VERSION ""

NS_ :

BS_:

BU_: CHUD_LS VKM_LS RCRM_LS MSM_RR_LS MSM_LR_LS CGM_LS BSM_LS VPM_LS ISRVM_LS DCAC_LS TouchPad_LS RSC_LS LVMPC_LS EOCM2B_K1_LS EOCM2A_K1_LS LCM_LS TIM_B_LS V2V_LS TCP_LS CSM_LS EOCM2B_K2_LS EOCM2A_K2_LS TIM_A_LS LVMNav_LS HFP_LS EDI_LS ARB_LS RSE_LS Dummy_LS VIS2_LS ICS_LS FCM_LS EOCM_F_LS VICM_LS AGC_LS MSM_P_LS OTIM_LS HVSM_R_LS HVSM_F_LS DVB_T_LS SBZA_R_LS PSD_R_LS PSD_L_LS UHP_Low UPA_LS STC_LS SBZA_L_LS PTM_LS ONSTAR_LS APA_LS TestTool_LS PHS_LS PDIM_LS CHM_LS RSA_LS AMP_LS HUD_LS MSM_LS HBSM_LS SCL_LS ECC_LS RadioHead_LS PEPS_LS IPC_LS AOS_LS SDM_LS TIM_LS BCM_LS

BO_ 2151292928 V2V_Customization_Menu_LS: 5 V2V_LS
 SG_ TrfRdsdInfCsStAvail : 0|1@0+ (1,0) [0|1] ""  CGM_LS,CSM_LS,RadioHead_LS
 SG_ TrfRdsdInfCsCrStVal : 10|3@0+ (1,0) [0|7] ""  CGM_LS,CSM_LS,RadioHead_LS
 SG_ TRICA_Resrv5Avail : 32|1@0+ (1,0) [0|1] ""  CGM_LS,CSM_LS,RadioHead_LS
 SG_ TRICA_Resrv4Avail : 33|1@0+ (1,0) [0|1] ""  CGM_LS,CSM_LS,RadioHead_LS
 SG_ TRICA_Resrv3Avail : 34|1@0+ (1,0) [0|1] ""  CGM_LS,CSM_LS,RadioHead_LS
 SG_ TRICA_Resrv2Avail : 35|1@0+ (1,0) [0|1] ""  CGM_LS,CSM_LS,RadioHead_LS
 SG_ TRICA_Resrv1Avail : 36|1@0+ (1,0) [0|1] ""  CGM_LS,CSM_LS,RadioHead_LS
 SG_ TRICA_OnAvail : 37|1@0+ (1,0) [0|1] ""  CGM_LS,CSM_LS,RadioHead_LS
 SG_ TRICA_OfAvail : 38|1@0+ (1,0) [0|1] ""  CGM_LS,CSM_LS,RadioHead_LS
 SG_ IntrStopAlrtCsSetAvl : 2|1@0+ (1,0) [0|1] ""  CGM_LS,CSM_LS,RadioHead_LS
 SG_ IntrStAlrtCsCrSetVal : 5|3@0+ (1,0) [0|7] ""  CGM_LS,CSM_LS,RadioHead_LS
 SG_ ISACA_Resrv4Avail : 16|1@0+ (1,0) [0|1] ""  CGM_LS,CSM_LS,RadioHead_LS
 SG_ ISACA_Resrv3Avail : 17|1@0+ (1,0) [0|1] ""  CGM_LS,CSM_LS,RadioHead_LS
 SG_ ISACA_Resrv2Avail : 18|1@0+ (1,0) [0|1] ""  CGM_LS,CSM_LS,RadioHead_LS
 SG_ ISACA_Resrv1Avail : 19|1@0+ (1,0) [0|1] ""  CGM_LS,CSM_LS,RadioHead_LS
 SG_ ISACA_AlrtBrkAvail : 20|1@0+ (1,0) [0|1] ""  CGM_LS,CSM_LS,RadioHead_LS
 SG_ ISACA_AlrtAvail : 21|1@0+ (1,0) [0|1] ""  CGM_LS,CSM_LS,RadioHead_LS
 SG_ ISACA_OfAvail : 22|1@0+ (1,0) [0|1] ""  CGM_LS,CSM_LS,RadioHead_LS
 SG_ CntdVehBrkAltCsStAvl : 1|1@0+ (1,0) [0|1] ""  CGM_LS,CSM_LS,RadioHead_LS
 SG_ CntdVehBrAltCsCrStVal : 13|3@0+ (1,0) [0|7] ""  CGM_LS,CSM_LS,RadioHead_LS
 SG_ CVBACA_Resrv5Avail : 24|1@0+ (1,0) [0|1] ""  CGM_LS,CSM_LS,RadioHead_LS
 SG_ CVBACA_Resrv4Avail : 25|1@0+ (1,0) [0|1] ""  CGM_LS,CSM_LS,RadioHead_LS
 SG_ CVBACA_Resrv3Avail : 26|1@0+ (1,0) [0|1] ""  CGM_LS,CSM_LS,RadioHead_LS
 SG_ CVBACA_Resrv2Avail : 27|1@0+ (1,0) [0|1] ""  CGM_LS,CSM_LS,RadioHead_LS
 SG_ CVBACA_Resrv1Avail : 28|1@0+ (1,0) [0|1] ""  CGM_LS,CSM_LS,RadioHead_LS
 SG_ CVBACA_OnAvail : 29|1@0+ (1,0) [0|1] ""  CGM_LS,CSM_LS,RadioHead_LS
 SG_ CVBACA_OfAvail : 30|1@0+ (1,0) [0|1] ""  CGM_LS,CSM_LS,RadioHead_LS

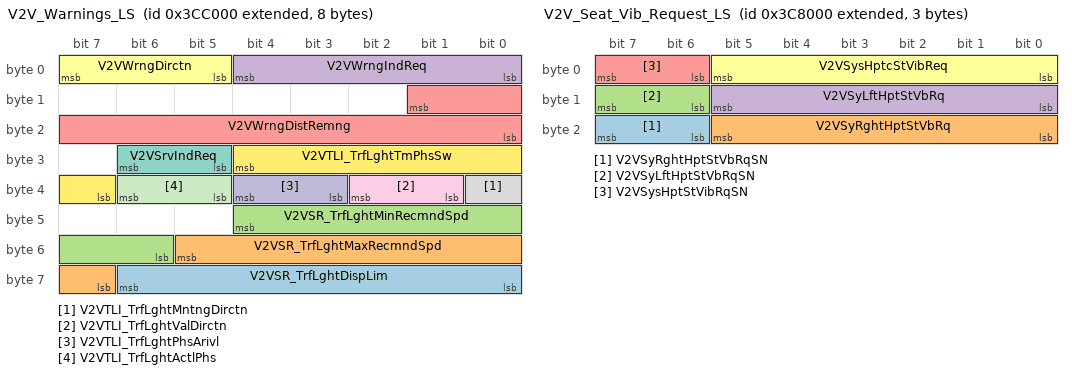
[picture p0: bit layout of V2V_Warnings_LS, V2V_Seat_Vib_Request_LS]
BO_ 2151464960 V2V_Warnings_LS: 8 V2V_LS
 SG_ V2VSR_TrfLghtDispLim : 62|7@0+ (1,0) [0|127] "km/h"  CGM_LS,IPC_LS
 SG_ V2VSR_TrfLghtMaxRecmndSpd : 53|7@0+ (1,0) [0|127] "km/h"  CGM_LS,IPC_LS
 SG_ V2VSR_TrfLghtMinRecmndSpd : 44|7@0+ (1,0) [0|127] "km/h"  CGM_LS,IPC_LS
 SG_ V2VWrngIndReq : 4|5@0+ (1,0) [0|31] ""  CGM_LS,IPC_LS
 SG_ V2VWrngDistRemng : 9|10@0+ (1,0) [0|1023] ""  CGM_LS,IPC_LS
 SG_ V2VWrngDirctn : 7|3@0+ (1,0) [0|7] ""  CGM_LS,IPC_LS
 SG_ V2VSrvIndReq : 30|2@0+ (1,0) [0|3] ""  CGM_LS,IPC_LS
 SG_ V2VTLI_TrfLghtMntngDirctn : 32|1@0+ (1,0) [0|1] ""  CGM_LS,IPC_LS
 SG_ V2VTLI_TrfLghtValDirctn : 34|2@0+ (1,0) [0|3] ""  CGM_LS,IPC_LS
 SG_ V2VTLI_TrfLghtPhsArivl : 36|2@0+ (1,0) [0|3] ""  CGM_LS,IPC_LS
 SG_ V2VTLI_TrfLghtActlPhs : 38|2@0+ (1,0) [0|3] ""  CGM_LS,IPC_LS
 SG_ V2VTLI_TrfLghtTmPhsSw : 28|6@0+ (1,0) [0|63] ""  CGM_LS,IPC_LS

BO_ 2151448576 V2V_Seat_Vib_Request_LS: 3 V2V_LS
 SG_ V2VSyRghtHptStVbRqSN : 23|2@0+ (1,0) [0|3] ""  MSM_P_LS,MSM_LS
 SG_ V2VSyRghtHptStVbRq : 21|6@0+ (1,0) [0|63] ""  MSM_P_LS,MSM_LS
 SG_ V2VSyLftHptStVbRqSN : 15|2@0+ (1,0) [0|3] ""  MSM_P_LS,MSM_LS
 SG_ V2VSyLftHptStVbRq : 13|6@0+ (1,0) [0|63] ""  MSM_P_LS,MSM_LS
 SG_ V2VSysHptStVibRqSN : 7|2@0+ (1,0) [0|3] ""  MSM_P_LS,MSM_LS
 SG_ V2VSysHptcStVibReq : 5|6@0+ (1,0) [0|63] ""  MSM_P_LS,MSM_LS

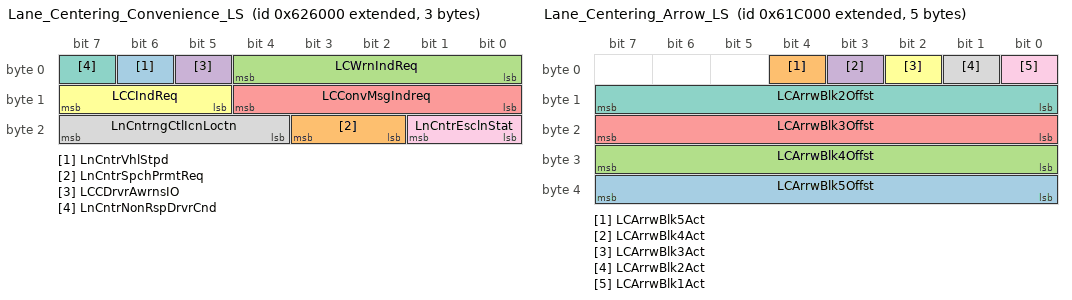
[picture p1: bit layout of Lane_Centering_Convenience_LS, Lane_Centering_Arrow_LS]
BO_ 2153930752 Lane_Centering_Convenience_LS: 3 EOCM2A_K2_LS
 SG_ LnCntrVhlStpd : 6|1@0+ (1,0) [0|1] ""  TCP_LS,ONSTAR_LS,CGM_LS
 SG_ LnCntrSpchPrmtReq : 19|2@0+ (1,0) [0|3] ""  CSM_LS,TCP_LS,ONSTAR_LS,CGM_LS
 SG_ LCWrnIndReq : 4|5@0+ (1,0) [0|31] ""  CGM_LS,IPC_LS
 SG_ LCCDrvrAwrnsIO : 5|1@0+ (1,0) [0|1] ""  TCP_LS,ONSTAR_LS,CGM_LS,IPC_LS
 SG_ LCConvMsgIndreq : 12|5@0+ (1,0) [0|31] ""  CSM_LS,CGM_LS,IPC_LS
 SG_ LCCIndReq : 15|3@0+ (1,0) [0|7] ""  TCP_LS,ONSTAR_LS,CGM_LS,IPC_LS
 SG_ LnCntrNonRspDrvrCnd : 7|1@0+ (1,0) [0|1] ""  TCP_LS,ONSTAR_LS,CGM_LS
 SG_ LnCntrngCtlIcnLoctn : 23|4@0- (1,0) [-8|7] ""  CGM_LS,IPC_LS
 SG_ LnCntrEsclnStat : 17|2@0+ (1,0) [0|3] ""  TCP_LS,ONSTAR_LS,CGM_LS

BO_ 2153889792 Lane_Centering_Arrow_LS: 5 EOCM2A_K2_LS
 SG_ LCArrwBlk5Offst : 39|8@0- (1,0) [-128|127] ""  CGM_LS,IPC_LS
 SG_ LCArrwBlk5Act : 4|1@0+ (1,0) [0|1] ""  CGM_LS,IPC_LS
 SG_ LCArrwBlk4Offst : 31|8@0- (1,0) [-128|127] ""  CGM_LS,IPC_LS
 SG_ LCArrwBlk4Act : 3|1@0+ (1,0) [0|1] ""  CGM_LS,IPC_LS
 SG_ LCArrwBlk3Offst : 23|8@0- (1,0) [-128|127] ""  CGM_LS,IPC_LS
 SG_ LCArrwBlk3Act : 2|1@0+ (1,0) [0|1] ""  CGM_LS,IPC_LS
 SG_ LCArrwBlk2Offst : 15|8@0- (1,0) [-128|127] ""  CGM_LS,IPC_LS
 SG_ LCArrwBlk2Act : 1|1@0+ (1,0) [0|1] ""  CGM_LS,IPC_LS
 SG_ LCArrwBlk1Act : 0|1@0+ (1,0) [0|1] ""  CGM_LS,IPC_LS

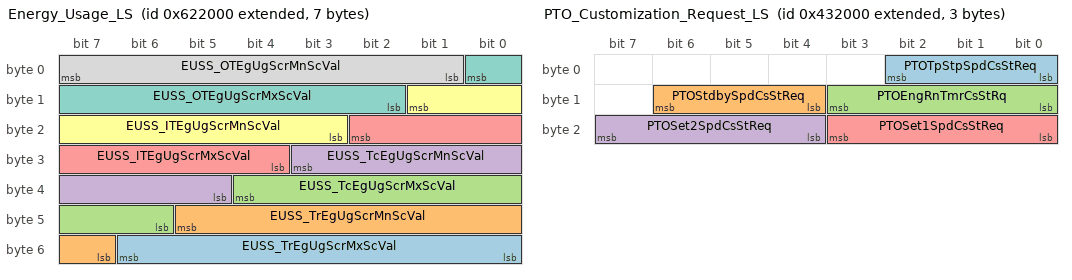
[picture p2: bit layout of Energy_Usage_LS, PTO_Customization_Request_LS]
BO_ 2153914368 Energy_Usage_LS: 7 VICM_LS
 SG_ EUSS_TrEgUgScrMxScVal : 54|7@0- (0.1,0) [-5|5] ""  CGM_LS,CSM_LS,RadioHead_LS
 SG_ EUSS_TrEgUgScrMnScVal : 45|7@0- (0.1,0) [-5|5] ""  CGM_LS,CSM_LS,RadioHead_LS
 SG_ EUSS_TcEgUgScrMxScVal : 36|7@0- (0.1,0) [-5|5] ""  CGM_LS,CSM_LS,RadioHead_LS
 SG_ EUSS_TcEgUgScrMnScVal : 27|7@0- (0.1,0) [-5|5] ""  CGM_LS,CSM_LS,RadioHead_LS
 SG_ EUSS_ITEgUgScrMxScVal : 18|7@0- (0.1,0) [-5|5] ""  CGM_LS,CSM_LS,RadioHead_LS
 SG_ EUSS_ITEgUgScrMnScVal : 9|7@0- (0.1,0) [-5|5] ""  CGM_LS,CSM_LS,RadioHead_LS
 SG_ EUSS_OTEgUgScrMxScVal : 0|7@0- (0.1,0) [-5|5] ""  CGM_LS,CSM_LS,RadioHead_LS
 SG_ EUSS_OTEgUgScrMnScVal : 7|7@0- (0.1,0) [-5|5] ""  CGM_LS,CSM_LS,RadioHead_LS

BO_ 2151882752 PTO_Customization_Request_LS: 3 RadioHead_LS
 SG_ PTOTpStpSpdCsStReq : 2|3@0+ (1,0) [0|7] ""  BCM_LS
 SG_ PTOStdbySpdCsStReq : 14|3@0+ (1,0) [0|7] ""  BCM_LS
 SG_ PTOEngRnTmrCsStRq : 11|4@0+ (1,0) [0|15] ""  BCM_LS
 SG_ PTOSet2SpdCsStReq : 23|4@0+ (1,0) [0|15] ""  BCM_LS
 SG_ PTOSet1SpdCsStReq : 19|4@0+ (1,0) [0|15] ""  BCM_LS

BO_ 2151899136 PTO_Status_LS: 5 BCM_LS
 SG_ PTOAccelUpnBrkRelIO : 22|1@0+ (1,0) [0|1] ""  CGM_LS,IPC_LS
 SG_ PTOEngUpnBrkRelIO : 23|1@0+ (1,0) [0|1] ""  CGM_LS,IPC_LS
 SG_ PTOManTransInGrIO : 21|1@0+ (1,0) [0|1] ""  CGM_LS,IPC_LS
 SG_ PTOServIndOn : 31|1@0+ (1,0) [0|1] ""  CGM_LS,IPC_LS
 SG_ PTOVDM : 20|1@0+ (1,0) [0|1] ""  CGM_LS,CSM_LS,RadioHead_LS,IPC_LS
 SG_ PTOVDA : 19|1@0+ (1,0) [0|1] ""  CGM_LS,CSM_LS,RadioHead_LS,IPC_LS
 SG_ PTOTransInGearIO : 13|1@0+ (1,0) [0|1] ""  CGM_LS,IPC_LS
 SG_ PTOTpStpSpdCsStAvl : 10|1@0+ (1,0) [0|1] ""  CGM_LS,CSM_LS,RadioHead_LS
 SG_ PTOTpStSpdCsCrStVal : 26|3@0+ (1,0) [0|7] ""  CGM_LS,CSM_LS,RadioHead_LS
 SG_ PTOStdbySpdCsStAvl : 12|1@0+ (1,0) [0|1] ""  CGM_LS,CSM_LS,RadioHead_LS
 SG_ PTOStdbSpdCsCrStVal : 18|3@0+ (1,0) [0|7] ""  CGM_LS,CSM_LS,RadioHead_LS
 SG_ PTOSetPrkBrkIO : 14|1@0+ (1,0) [0|1] ""  CGM_LS,IPC_LS
 SG_ PTOSet2SpdCsStAvl : 9|1@0+ (1,0) [0|1] ""  CGM_LS,CSM_LS,RadioHead_LS
 SG_ PTOSet2SpdCsCrStVal : 39|4@0+ (1,0) [0|15] ""  CGM_LS,CSM_LS,RadioHead_LS
 SG_ PTOSet1SpdCsStAvl : 8|1@0+ (1,0) [0|1] ""  CGM_LS,CSM_LS,RadioHead_LS
 SG_ PTOSet1SpdCsCrStVal : 35|4@0+ (1,0) [0|15] ""  CGM_LS,CSM_LS,RadioHead_LS
 SG_ PTORelCltPedIO : 15|1@0+ (1,0) [0|1] ""  CGM_LS,IPC_LS
 SG_ PTORelBrkPedIO : 0|1@0+ (1,0) [0|1] ""  CGM_LS,IPC_LS
 SG_ PTORelAccPedIO : 1|1@0+ (1,0) [0|1] ""  CGM_LS,IPC_LS
 SG_ PTORedEngSpdIO : 2|1@0+ (1,0) [0|1] ""  CGM_LS,IPC_LS
 SG_ PTOPrsRelCltPedIO : 3|1@0+ (1,0) [0|1] ""  CGM_LS,IPC_LS
 SG_ PTOPrsRelBrkPedIO : 4|1@0+ (1,0) [0|1] ""  CGM_LS,IPC_LS
 SG_ PTOEngRnTmrCsStAvl : 11|1@0+ (1,0) [0|1] ""  CGM_LS,CSM_LS,RadioHead_LS
 SG_ PTOEnRnTmCsCrStVal : 30|4@0+ (1,0) [0|15] ""  CGM_LS,CSM_LS,RadioHead_LS
 SG_ PTOEngmntStatInd : 6|2@0+ (1,0) [0|3] ""  CGM_LS,IPC_LS
 SG_ PTODisengCrsCntlIO : 7|1@0+ (1,0) [0|1] ""  CGM_LS,IPC_LS

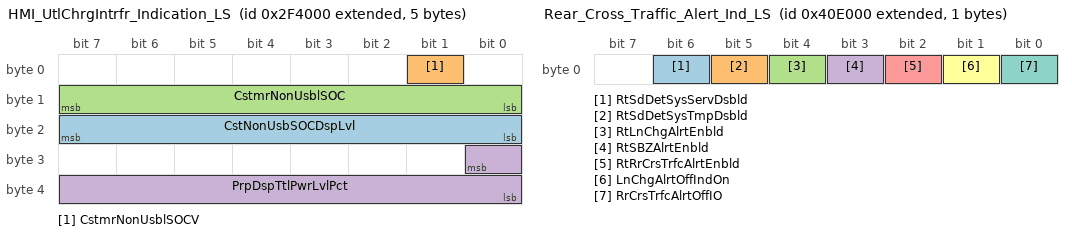
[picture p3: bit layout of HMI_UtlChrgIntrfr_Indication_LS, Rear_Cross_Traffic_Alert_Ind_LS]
BO_ 2150580224 HMI_UtlChrgIntrfr_Indication_LS: 5 VICM_LS
 SG_ CstNonUsbSOCDspLvl : 23|8@0+ (0.392157,0) [0|100.000035] "%"  CGM_LS,IPC_LS
 SG_ CstmrNonUsblSOCV : 1|1@0+ (1,0) [0|1] ""  CSM_LS,ONSTAR_LS,CGM_LS,IPC_LS
 SG_ CstmrNonUsblSOC : 15|8@0+ (0.392157,0) [0|100.000035] "%"  CSM_LS,ONSTAR_LS,CGM_LS,IPC_LS
 SG_ PrpDspTtlPwrLvlPct : 24|9@0- (0.392157,0) [-100.392192|100.000035] "%"  CSM_LS,RadioHead_LS,CGM_LS,IPC_LS

BO_ 2020 USDT_Req_to_VICM_LS: 8 TestTool_LS
 SG_ DgnInf : 7|64@0+ (1,0) [0|1.84467440737096E+019] ""  CGM_LS,TCP_LS,ONSTAR_LS,BSM_LS,VICM_LS

BO_ 2151735296 Rear_Cross_Traffic_Alert_Ind_LS: 1 SBZA_L_LS
 SG_ RtSdDetSysServDsbld : 6|1@0+ (1,0) [0|1] ""  SBZA_R_LS,CGM_LS
 SG_ RtSdDetSysTmpDsbld : 5|1@0+ (1,0) [0|1] ""  SBZA_R_LS,CGM_LS
 SG_ RtLnChgAlrtEnbld : 4|1@0+ (1,0) [0|1] ""  SBZA_R_LS,CGM_LS
 SG_ RtSBZAlrtEnbld : 3|1@0+ (1,0) [0|1] ""  SBZA_R_LS,CGM_LS
 SG_ RtRrCrsTrfcAlrtEnbld : 2|1@0+ (1,0) [0|1] ""  SBZA_R_LS,CGM_LS
 SG_ LnChgAlrtOffIndOn : 1|1@0+ (1,0) [0|1] ""  CGM_LS,SBZA_R_LS,IPC_LS
 SG_ RrCrsTrfcAlrtOffIO : 0|1@0+ (1,0) [0|1] ""  CGM_LS,SBZA_R_LS,IPC_LS

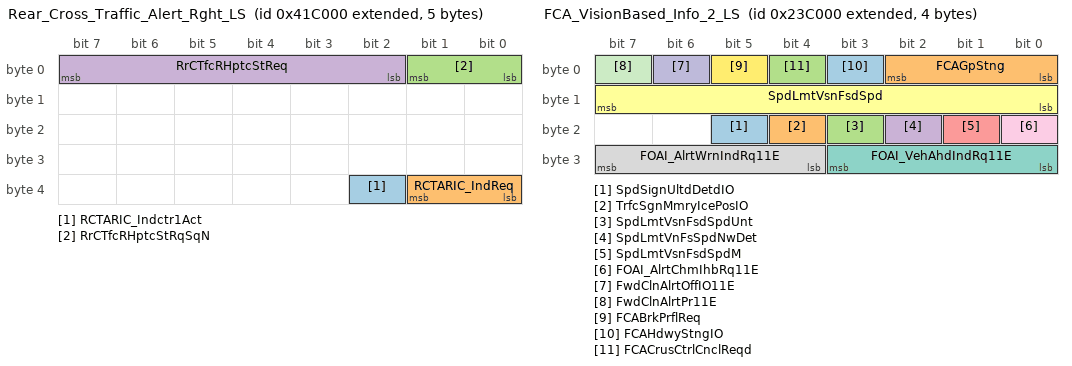
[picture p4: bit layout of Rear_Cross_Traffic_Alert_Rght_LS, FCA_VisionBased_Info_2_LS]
BO_ 2151792640 Rear_Cross_Traffic_Alert_Rght_LS: 5 SBZA_R_LS
 SG_ RCTARIC_Indctr1Act : 34|1@0+ (1,0) [0|1] ""  CGM_LS,VPM_LS,CSM_LS,RadioHead_LS
 SG_ RCTARIC_IndReq : 33|2@0+ (1,0) [0|3] ""  CGM_LS,VPM_LS,CSM_LS,RadioHead_LS
 SG_ RrCTfcRHptcStRqSqN : 1|2@0+ (1,0) [0|3] ""  CGM_LS,VPM_LS,MSM_P_LS,MSM_LS
 SG_ RrCTfcRHptcStReq : 7|6@0+ (1,0) [0|63] ""  CGM_LS,VPM_LS,MSM_P_LS,MSM_LS

BO_ 2149826560 FCA_VisionBased_Info_2_LS: 4 FCM_LS
 SG_ SpdSignUltdDetdIO : 21|1@0+ (1,0) [0|1] ""  CGM_LS,IPC_LS
 SG_ TrfcSgnMmryIcePosIO : 20|1@0+ (1,0) [0|1] ""  CGM_LS,IPC_LS
 SG_ SpdLmtVsnFsdSpdUnt : 19|1@0+ (1,0) [0|1] ""  IPC_LS,CGM_LS,BCM_LS
 SG_ SpdLmtVnFsSpdNwDet : 18|1@0+ (1,0) [0|1] ""  CGM_LS,BCM_LS
 SG_ SpdLmtVsnFsdSpdM : 17|1@0+ (1,0) [0|1] ""  CGM_LS,BCM_LS,IPC_LS
 SG_ SpdLmtVsnFsdSpd : 15|8@0+ (1,0) [0|255] ""  CSM_LS,RadioHead_LS,CGM_LS,BCM_LS,IPC_LS
 SG_ FOAI_VehAhdIndRq11E : 27|4@0+ (1,0) [0|15] ""  BCM_LS,CGM_LS,IPC_LS,CHUD_LS,HUD_LS
 SG_ FOAI_AlrtWrnIndRq11E : 31|4@0+ (1,0) [0|15] ""  BCM_LS,CGM_LS,IPC_LS,CHUD_LS,HUD_LS
 SG_ FOAI_AlrtChmIhbRq11E : 16|1@0+ (1,0) [0|1] ""  BCM_LS,CGM_LS,IPC_LS,CHUD_LS,HUD_LS
 SG_ FwdClnAlrtOffIO11E : 6|1@0+ (1,0) [0|1] ""  CGM_LS,IPC_LS
 SG_ FwdClnAlrtPr11E : 7|1@0+ (1,0) [0|1] ""  CGM_LS,IPC_LS,CHUD_LS,HUD_LS
 SG_ FCABrkPrflReq : 5|1@0+ (1,0) [0|1] ""  CGM_LS,BCM_LS
 SG_ FCAHdwyStngIO : 3|1@0+ (1,0) [0|1] ""  CGM_LS,IPC_LS
 SG_ FCAGpStng : 2|3@0+ (1,0) [0|7] ""  CGM_LS,IPC_LS
 SG_ FCACrusCtrlCnclReqd : 4|1@0+ (1,0) [0|1] ""  CGM_LS,BCM_LS

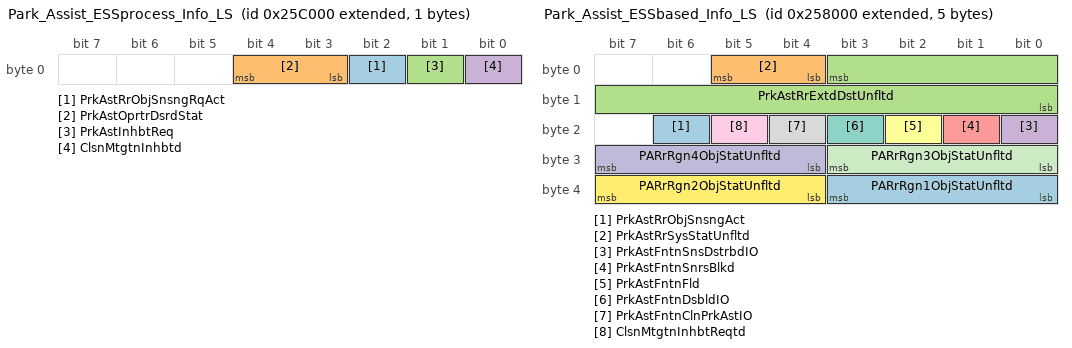
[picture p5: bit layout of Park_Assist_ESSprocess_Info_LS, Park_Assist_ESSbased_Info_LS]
BO_ 2149957632 Park_Assist_ESSprocess_Info_LS: 1 EOCM_F_LS
 SG_ PrkAstRrObjSnsngRqAct : 2|1@0+ (1,0) [0|1] ""  CGM_LS,UPA_LS,APA_LS
 SG_ PrkAstOprtrDsrdStat : 4|2@0+ (1,0) [0|3] ""  CGM_LS,UPA_LS,APA_LS
 SG_ PrkAstInhbtReq : 1|1@0+ (1,0) [0|1] ""  CGM_LS,UPA_LS,APA_LS
 SG_ ClsnMtgtnInhbtd : 0|1@0+ (1,0) [0|1] ""  CGM_LS,UPA_LS,APA_LS

BO_ 2149941248 Park_Assist_ESSbased_Info_LS: 5 APA_LS
 SG_ PrkAstRrObjSnsngAct : 22|1@0+ (1,0) [0|1] ""  EOCM2B_K2_LS,EOCM2A_K2_LS,CGM_LS,EOCM_F_LS
 SG_ PrkAstRrSysStatUnfltd : 5|2@0+ (1,0) [0|3] ""  EOCM2B_K2_LS,EOCM2A_K2_LS,CGM_LS,EOCM_F_LS
 SG_ PrkAstRrExtdDstUnfltd : 3|12@0+ (0.01,0) [0|40.95] "m"  EOCM2B_K2_LS,EOCM2A_K2_LS,CGM_LS,EOCM_F_LS
 SG_ PrkAstFntnSnsDstrbdIO : 16|1@0+ (1,0) [0|1] ""  CGM_LS,EOCM2B_K2_LS,EOCM2A_K2_LS,SBZA_R_LS,SBZA_L_LS,EOCM_F_LS
 SG_ PrkAstFntnSnrsBlkd : 17|1@0+ (1,0) [0|1] ""  CGM_LS,EOCM2B_K2_LS,EOCM2A_K2_LS,SBZA_R_LS,SBZA_L_LS,EOCM_F_LS
 SG_ PrkAstFntnFld : 18|1@0+ (1,0) [0|1] ""  CGM_LS,EOCM2B_K2_LS,EOCM2A_K2_LS,SBZA_R_LS,SBZA_L_LS,EOCM_F_LS
 SG_ PrkAstFntnDsbldIO : 19|1@0+ (1,0) [0|1] ""  CGM_LS,EOCM2B_K2_LS,EOCM2A_K2_LS,SBZA_R_LS,SBZA_L_LS,EOCM_F_LS
 SG_ PrkAstFntnClnPrkAstIO : 20|1@0+ (1,0) [0|1] ""  CGM_LS,EOCM2B_K2_LS,EOCM2A_K2_LS,SBZA_R_LS,SBZA_L_LS,EOCM_F_LS
 SG_ ClsnMtgtnInhbtReqtd : 21|1@0+ (1,0) [0|1] ""  EOCM2B_K2_LS,EOCM2A_K2_LS,CGM_LS,EOCM_F_LS
 SG_ PARrRgn4ObjStatUnfltd : 31|4@0+ (1,0) [0|15] ""  EOCM2B_K2_LS,EOCM2A_K2_LS,CGM_LS,EOCM_F_LS
 SG_ PARrRgn3ObjStatUnfltd : 27|4@0+ (1,0) [0|15] ""  EOCM2B_K2_LS,EOCM2A_K2_LS,CGM_LS,EOCM_F_LS
 SG_ PARrRgn2ObjStatUnfltd : 39|4@0+ (1,0) [0|15] ""  EOCM2B_K2_LS,EOCM2A_K2_LS,CGM_LS,EOCM_F_LS
 SG_ PARrRgn1ObjStatUnfltd : 35|4@0+ (1,0) [0|15] ""  EOCM2B_K2_LS,EOCM2A_K2_LS,CGM_LS,EOCM_F_LS

BO_ 2156314624 High_Volt_Time_Based_Chrg_LS: 8 VICM_LS
 SG_ HVChrgSysSplyFltIO : 23|1@0+ (1,0) [0|1] ""  CGM_LS,IPC_LS
 SG_ OffBrdCSFltDtctd : 6|1@0+ (1,0) [0|1] ""  CSM_LS,ONSTAR_LS,CGM_LS,IPC_LS
 SG_ OBVhCsACChgRqBnVs : 7|1@0+ (1,0) [0|1] ""  BCM_LS,CGM_LS,CSM_LS,RadioHead_LS
 SG_ TODCNPDT_Min : 13|6@0+ (1,0) [0|63] "Minute"  BCM_LS,CGM_LS,CSM_LS,RadioHead_LS
 SG_ TODCNPDT_Hr : 2|5@0+ (1,0) [0|31] "Hour"  BCM_LS,CGM_LS,CSM_LS,RadioHead_LS
 SG_ TODCNPDT_DyOfWk : 5|3@0+ (1,0) [0|7] ""  BCM_LS,CGM_LS,CSM_LS,RadioHead_LS
 SG_ HVBatBlkSOC : 63|8@0+ (0.392157,0) [0|100.000035] "%"  CGM_LS,CSM_LS,RadioHead_LS,IPC_LS
 SG_ TODCOpMd : 22|3@0+ (1,0) [0|7] ""  CSM_LS,TCP_LS,CGM_LS,RadioHead_LS,ONSTAR_LS
 SG_ TODCDMPTO_TpOvR : 51|4@0+ (1,0) [0|15] ""  BCM_LS,TCP_LS,CGM_LS,ONSTAR_LS,CSM_LS,RadioHead_LS,IPC_LS
 SG_ TODCDMPTO_CmPgR : 52|1@0+ (1,0) [0|1] ""  BCM_LS,TCP_LS,CGM_LS,ONSTAR_LS,CSM_LS,RadioHead_LS,IPC_LS
 SG_ HVChrgSysStNot : 55|3@0+ (1,0) [0|7] ""  BCM_LS,CSM_LS,TCP_LS,CGM_LS,RadioHead_LS,ONSTAR_LS
 SG_ HVChrgAbrtRsn : 19|3@0+ (1,0) [0|7] ""  CSM_LS,TCP_LS,CGM_LS,RadioHead_LS,ONSTAR_LS
 SG_ HVCSCLPD_UsrIntTyp : 16|2@0+ (1,0) [0|3] ""  BCM_LS,CGM_LS,CSM_LS,RadioHead_LS
 SG_ HVCSCLPD_RdCrntLv3 : 44|5@0+ (1,0) [0|31] "A"  BCM_LS,CGM_LS,CSM_LS,RadioHead_LS
 SG_ HVCSCLPD_RdCrntLv2 : 33|5@0+ (1,0) [0|31] "A"  BCM_LS,CGM_LS,CSM_LS,RadioHead_LS
 SG_ HVCSCLPD_RdCrntLv1 : 38|5@0+ (1,0) [0|31] "A"  BCM_LS,CGM_LS,CSM_LS,RadioHead_LS
 SG_ HVCSCLPD_NrmChrgC : 27|5@0+ (1,0) [0|31] "A"  BCM_LS,CGM_LS,CSM_LS,RadioHead_LS
 SG_ HVCSCLPD_ChgLvlPfS : 30|3@0+ (1,0) [0|7] ""  BCM_LS,CGM_LS,CSM_LS,RadioHead_LS

BO_ 2150449152 Engine_Information_5_LS: 4 BCM_LS
 SG_ ESPDrvrExtIO : 29|1@0+ (1,0) [0|1] ""  IPC_LS,CGM_LS
 SG_ ESPDrvrDrStIndtrmntIO : 30|1@0+ (1,0) [0|1] ""  IPC_LS,CGM_LS
 SG_ ESPAutoPrkIO : 31|1@0+ (1,0) [0|1] ""  IPC_LS,CGM_LS
 SG_ ManTransIndReq : 28|3@0+ (1,0) [0|7] ""  CGM_LS,IPC_LS
 SG_ SrvcFlSysPrkInOpnArIO : 0|1@0+ (1,0) [0|1] ""  CGM_LS,IPC_LS
 SG_ TnDrvStblCtrlOffUnbIO : 2|1@0+ (1,0) [0|1] ""  CGM_LS,IPC_LS
 SG_ TnDrvTrCtrlOffUnbIO : 1|1@0+ (1,0) [0|1] ""  CGM_LS,IPC_LS
 SG_ ASIRI_Indication08 : 16|1@0+ (1,0) [0|1] ""  CSM_LS,CGM_LS,IPC_LS
 SG_ ASIRI_Indication07 : 17|1@0+ (1,0) [0|1] ""  CSM_LS,CGM_LS,IPC_LS
 SG_ ASIRI_Indication06 : 18|1@0+ (1,0) [0|1] ""  CSM_LS,CGM_LS,IPC_LS
 SG_ ASIRI_Indication05 : 19|1@0+ (1,0) [0|1] ""  CSM_LS,CGM_LS,IPC_LS
 SG_ ASIRI_Indication04 : 20|1@0+ (1,0) [0|1] ""  CSM_LS,CGM_LS,IPC_LS
 SG_ ASIRI_Indication03 : 21|1@0+ (1,0) [0|1] ""  CSM_LS,CGM_LS,IPC_LS
 SG_ ASIRI_Indication02 : 22|1@0+ (1,0) [0|1] ""  CSM_LS,CGM_LS,IPC_LS
 SG_ ASIRI_Indication01 : 23|1@0+ (1,0) [0|1] ""  CSM_LS,CGM_LS,IPC_LS
 SG_ SpdLmtrSttngTypAct : 25|2@0+ (1,0) [0|3] ""  FCM_LS,VIS2_LS,CSM_LS,RadioHead_LS,CGM_LS,IPC_LS
 SG_ FuelSysNEmsRltMalfAct : 4|1@0+ (1,0) [0|1] ""  CGM_LS,IPC_LS
 SG_ InActFuelMdFuelLvlIO : 3|1@0+ (1,0) [0|1] ""  CGM_LS,IPC_LS
 SG_ EngInltSpcfcHmdtyV : 7|1@0+ (1,0) [0|1] ""  CGM_LS,ECC_LS
 SG_ EngInltSpcfcHmdtyM : 6|1@0+ (1,0) [0|1] ""  CGM_LS,ECC_LS
 SG_ EngInltSpcfcHmdty : 15|8@0+ (0.0196078,0) [0|4.999989] "% water"  CGM_LS,ECC_LS
 SG_ AltFuelSysOvrflDtdIO : 5|1@0+ (1,0) [0|1] ""  CGM_LS,IPC_LS

BO_ 2149810176 FCA_VisionBased_Info_1_LS: 1 BCM_LS
 SG_ FCAHptcStVbnRqSeqN : 1|2@0+ (1,0) [0|3] ""  MSM_P_LS,MSM_LS
 SG_ FCAHptcStVbnReq : 7|6@0+ (1,0) [0|63] ""  MSM_P_LS,MSM_LS

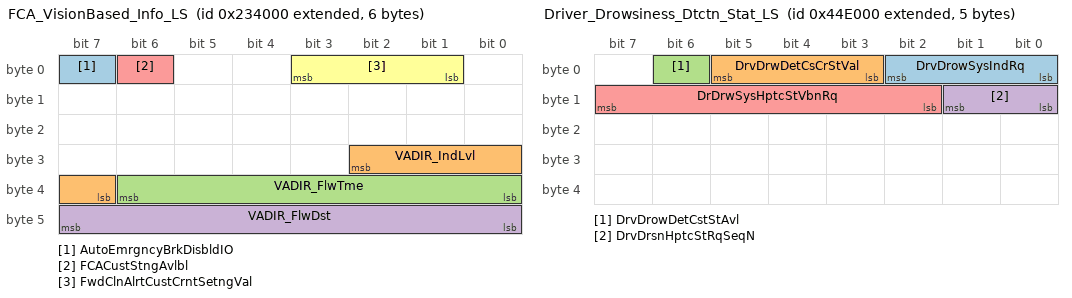
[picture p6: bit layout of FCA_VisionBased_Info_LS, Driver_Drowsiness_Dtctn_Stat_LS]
BO_ 2149793792 FCA_VisionBased_Info_LS: 6 FCM_LS
 SG_ AutoEmrgncyBrkDisbldIO : 7|1@0+ (1,0) [0|1] ""  CGM_LS,IPC_LS
 SG_ VADIR_IndLvl : 26|4@0+ (1,0) [0|15] ""  CSM_LS,RadioHead_LS,CGM_LS,IPC_LS
 SG_ VADIR_FlwTme : 38|7@0+ (0.1,0) [0|12.7] "s"  CSM_LS,RadioHead_LS,CGM_LS,IPC_LS
 SG_ VADIR_FlwDst : 47|8@0+ (1,0) [0|255] "m"  CSM_LS,RadioHead_LS,CGM_LS,IPC_LS
 SG_ FCACustStngAvlbl : 6|1@0+ (1,0) [0|1] ""  CGM_LS,CSM_LS,RadioHead_LS
 SG_ FwdClnAlrtCustCrntSetngVal : 3|3@0+ (1,0) [0|7] ""  CGM_LS,CSM_LS,RadioHead_LS

BO_ 2150080512 Aux_Coolant_Heater_Status_LS: 8 VICM_LS
 SG_ LBCVLS_VehGPSLctV : 27|1@0+ (1,0) [0|1] ""  CGM_LS,CSM_LS,RadioHead_LS
 SG_ LBCVLS_VehGPSLct : 26|3@0+ (1,0) [0|7] ""  CGM_LS,CSM_LS,RadioHead_LS
 SG_ LBCPSS_PosUpdtStat : 20|2@0+ (1,0) [0|3] ""  CGM_LS,CSM_LS,RadioHead_LS
 SG_ LBCPSS_PosUpdtLct : 18|3@0+ (1,0) [0|7] ""  CGM_LS,CSM_LS,RadioHead_LS
 SG_ LBCCsStAvl : 7|1@0+ (1,0) [0|1] ""  CGM_LS,CSM_LS,RadioHead_LS
 SG_ LBCCsCrStVal : 2|2@0+ (1,0) [0|3] ""  CGM_LS,CSM_LS,RadioHead_LS
 SG_ LBCCF_Lct4PosStrdIO : 28|1@0+ (1,0) [0|1] ""  CGM_LS,CSM_LS,RadioHead_LS
 SG_ LBCCF_Lct3PosStrdIO : 29|1@0+ (1,0) [0|1] ""  CGM_LS,CSM_LS,RadioHead_LS
 SG_ LBCCF_Lct2PosStrdIO : 30|1@0+ (1,0) [0|1] ""  CGM_LS,CSM_LS,RadioHead_LS
 SG_ LBCCF_Lct1PosStrdIO : 31|1@0+ (1,0) [0|1] ""  CGM_LS,CSM_LS,RadioHead_LS
 SG_ LBCCDRR_PosNumbr : 10|3@0+ (1,0) [0|7] ""  CGM_LS,CSM_LS,RadioHead_LS
 SG_ LBCCDRR_ClrStrdPosResp : 12|2@0+ (1,0) [0|3] ""  CGM_LS,CSM_LS,RadioHead_LS
 SG_ ChrgCyclOvrlEngyEcnEq : 51|12@0+ (0.1,0) [0|409.5] "km/l"  CGM_LS,CSM_LS,RadioHead_LS
 SG_ ChrgCyclElecEngyEcnEq : 35|12@0+ (0.1,0) [0|409.5] "km/l"  CGM_LS,CSM_LS,RadioHead_LS
 SG_ LBCChrgLvlPrfExpIO : 6|1@0+ (1,0) [0|1] ""  CGM_LS,CSM_LS,RadioHead_LS
 SG_ EngAstHtDfrdHtMdAct : 0|1@0+ (1,0) [0|1] ""  CGM_LS,ECC_LS
 SG_ AuxClntHtrVlvStat : 5|3@0+ (1,0) [0|7] ""  CGM_LS,ECC_LS

BO_ 2153873408 Heated_Steering_Whl_Rqsted_LS: 1 EOCM2B_K2_LS
 SG_ MnlHtdStWhlRqstd : 7|1@0+ (1,0) [0|1] ""  CGM_LS,ECC_LS

BO_ 2152128512 Performance_Mode_Cust_Setings_LS: 4 BCM_LS
 SG_ PSPMCA_PsngStPrfMd6Avl : 16|1@0+ (1,0) [0|1] ""  CGM_LS,CSM_LS,RadioHead_LS
 SG_ PSPMCA_PsngStPrfMd5Avl : 17|1@0+ (1,0) [0|1] ""  CGM_LS,CSM_LS,RadioHead_LS
 SG_ PSPMCA_PsngStPrfMd4Avl : 18|1@0+ (1,0) [0|1] ""  CGM_LS,CSM_LS,RadioHead_LS
 SG_ PSPMCA_PsngStPrfMd3Avl : 19|1@0+ (1,0) [0|1] ""  CGM_LS,CSM_LS,RadioHead_LS
 SG_ PSPMCA_PsngStPrfMd2Avl : 20|1@0+ (1,0) [0|1] ""  CGM_LS,CSM_LS,RadioHead_LS
 SG_ PSPMCA_PsngStPrfMd1Avl : 21|1@0+ (1,0) [0|1] ""  CGM_LS,CSM_LS,RadioHead_LS
 SG_ DSPMCA_DrvrStPrfMd6Avl : 8|1@0+ (1,0) [0|1] ""  CGM_LS,CSM_LS,RadioHead_LS
 SG_ DSPMCA_DrvrStPrfMd5Avl : 9|1@0+ (1,0) [0|1] ""  CGM_LS,CSM_LS,RadioHead_LS
 SG_ DSPMCA_DrvrStPrfMd4Avl : 10|1@0+ (1,0) [0|1] ""  CGM_LS,CSM_LS,RadioHead_LS
 SG_ DSPMCA_DrvrStPrfMd3Avl : 11|1@0+ (1,0) [0|1] ""  CGM_LS,CSM_LS,RadioHead_LS
 SG_ DSPMCA_DrvrStPrfMd2Avl : 12|1@0+ (1,0) [0|1] ""  CGM_LS,CSM_LS,RadioHead_LS
 SG_ DSPMCA_DrvrStPrfMd1Avl : 13|1@0+ (1,0) [0|1] ""  CGM_LS,CSM_LS,RadioHead_LS
 SG_ DSPMCA_DrvStyPrfMd7Avl : 24|1@0+ (1,0) [0|1] ""  CGM_LS,CSM_LS,RadioHead_LS
 SG_ DSPMCA_DrvStyPrfMd6Avl : 25|1@0+ (1,0) [0|1] ""  CGM_LS,CSM_LS,RadioHead_LS
 SG_ DSPMCA_DrvStyPrfMd5Avl : 26|1@0+ (1,0) [0|1] ""  CGM_LS,CSM_LS,RadioHead_LS
 SG_ DSPMCA_DrvStyPrfMd4Avl : 27|1@0+ (1,0) [0|1] ""  CGM_LS,CSM_LS,RadioHead_LS
 SG_ DSPMCA_DrvStyPrfMd3Avl : 28|1@0+ (1,0) [0|1] ""  CGM_LS,CSM_LS,RadioHead_LS
 SG_ DSPMCA_DrvStyPrfMd2Avl : 29|1@0+ (1,0) [0|1] ""  CGM_LS,CSM_LS,RadioHead_LS
 SG_ DSPMCA_DrvStyPrfMd1Avl : 30|1@0+ (1,0) [0|1] ""  CGM_LS,CSM_LS,RadioHead_LS
 SG_ ACCPMCA_ACCPrfMd6Avl : 0|1@0+ (1,0) [0|1] ""  CGM_LS,CSM_LS,RadioHead_LS
 SG_ ACCPMCA_ACCPrfMd5Avl : 1|1@0+ (1,0) [0|1] ""  CGM_LS,CSM_LS,RadioHead_LS
 SG_ ACCPMCA_ACCPrfMd4Avl : 2|1@0+ (1,0) [0|1] ""  CGM_LS,CSM_LS,RadioHead_LS
 SG_ ACCPMCA_ACCPrfMd3Avl : 3|1@0+ (1,0) [0|1] ""  CGM_LS,CSM_LS,RadioHead_LS
 SG_ ACCPMCA_ACCPrfMd2Avl : 4|1@0+ (1,0) [0|1] ""  CGM_LS,CSM_LS,RadioHead_LS
 SG_ ACCPMCA_ACCPrfMd1Avl : 5|1@0+ (1,0) [0|1] ""  CGM_LS,CSM_LS,RadioHead_LS

BO_ 2151997440 Driver_Drowsiness_Dtctn_Stat_LS: 5 FCM_LS
 SG_ DrvDrowSysIndRq : 2|3@0+ (1,0) [0|7] ""  CGM_LS,BCM_LS,IPC_LS
 SG_ DrvDrwDetCsCrStVal : 5|3@0+ (1,0) [0|7] ""  CGM_LS,CSM_LS,RadioHead_LS
 SG_ DrvDrowDetCstStAvl : 6|1@0+ (1,0) [0|1] ""  CGM_LS,CSM_LS,RadioHead_LS
 SG_ DrvDrsnHptcStRqSeqN : 9|2@0+ (1,0) [0|3] ""  CGM_LS,MSM_P_LS,MSM_LS
 SG_ DrDrwSysHptcStVbnRq : 15|6@0+ (1,0) [0|63] ""  CGM_LS,BCM_LS,MSM_P_LS,MSM_LS

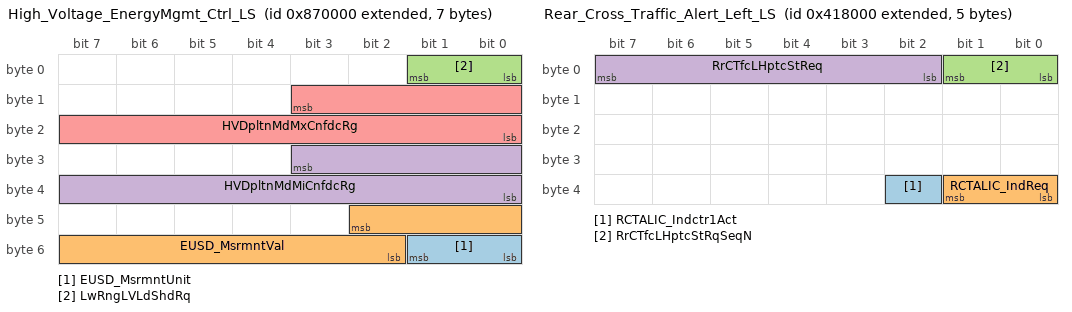
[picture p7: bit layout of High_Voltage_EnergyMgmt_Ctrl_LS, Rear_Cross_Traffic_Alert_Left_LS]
BO_ 2156331008 High_Voltage_EnergyMgmt_Ctrl_LS: 7 VICM_LS
 SG_ EUSD_MsrmntUnit : 49|2@0+ (1,0) [0|3] ""  CGM_LS,CSM_LS,RadioHead_LS
 SG_ EUSD_MsrmntVal : 42|9@0+ (1,0) [0|511] ""  CGM_LS,CSM_LS,RadioHead_LS
 SG_ LwRngLVLdShdRq : 1|2@0+ (1,0) [0|3] ""  CSM_LS,CGM_LS,RadioHead_LS,BCM_LS
 SG_ HVDpltnMdMiCnfdcRg : 27|12@0+ (0.1,0) [0|409.5] "km"  CGM_LS,CSM_LS,RadioHead_LS,IPC_LS
 SG_ HVDpltnMdMxCnfdcRg : 11|12@0+ (0.1,0) [0|409.5] "km"  CGM_LS,CSM_LS,RadioHead_LS,IPC_LS

BO_ 2151776256 Rear_Cross_Traffic_Alert_Left_LS: 5 SBZA_L_LS
 SG_ RCTALIC_Indctr1Act : 34|1@0+ (1,0) [0|1] ""  CGM_LS,VPM_LS,CSM_LS,RadioHead_LS
 SG_ RCTALIC_IndReq : 33|2@0+ (1,0) [0|3] ""  CGM_LS,VPM_LS,CSM_LS,RadioHead_LS
 SG_ RrCTfcLHptcStRqSeqN : 1|2@0+ (1,0) [0|3] ""  CGM_LS,VPM_LS,MSM_P_LS,MSM_LS
 SG_ RrCTfcLHptcStReq : 7|6@0+ (1,0) [0|63] ""  CGM_LS,VPM_LS,MSM_P_LS,MSM_LS

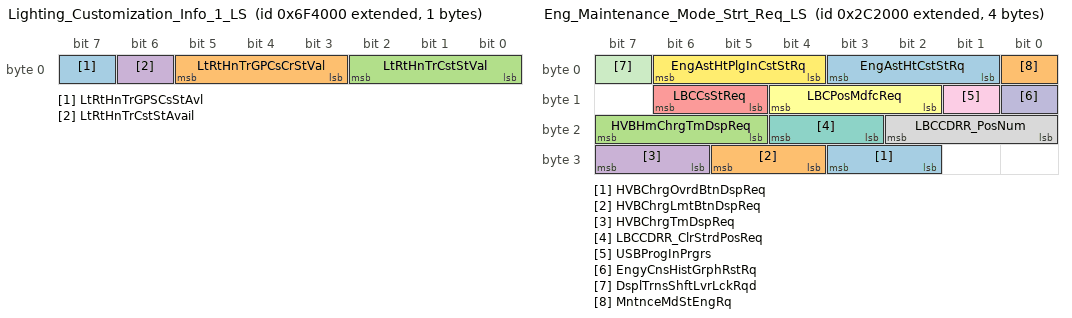
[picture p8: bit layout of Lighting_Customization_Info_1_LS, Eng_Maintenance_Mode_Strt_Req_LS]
BO_ 2154774528 Lighting_Customization_Info_1_LS: 1 BCM_LS
 SG_ LtRtHnTrGPSCsStAvl : 7|1@0+ (1,0) [0|1] ""  CGM_LS,CSM_LS,RadioHead_LS
 SG_ LtRtHnTrGPCsCrStVal : 5|3@0+ (1,0) [0|7] ""  CGM_LS,CSM_LS,RadioHead_LS
 SG_ LtRtHnTrCstStVal : 2|3@0+ (1,0) [0|7] ""  CGM_LS,CSM_LS,RadioHead_LS
 SG_ LtRtHnTrCstStAvail : 6|1@0+ (1,0) [0|1] ""  CGM_LS,CSM_LS,RadioHead_LS

BO_ 2150375424 Eng_Maintenance_Mode_Strt_Req_LS: 4 RadioHead_LS
 SG_ HVBChrgOvrdBtnDspReq : 27|2@0+ (1,0) [0|3] ""  VICM_LS
 SG_ HVBChrgLmtBtnDspReq : 29|2@0+ (1,0) [0|3] ""  VICM_LS
 SG_ HVBHmChrgTmDspReq : 23|3@0+ (1,0) [0|7] ""  VICM_LS
 SG_ HVBChrgTmDspReq : 31|2@0+ (1,0) [0|3] ""  VICM_LS
 SG_ LBCCsStReq : 14|2@0+ (1,0) [0|3] ""  BSM_LS,VICM_LS
 SG_ LBCPosMdfcReq : 12|3@0+ (1,0) [0|7] ""  BSM_LS,VICM_LS
 SG_ LBCCDRR_ClrStrdPosReq : 20|2@0+ (1,0) [0|3] ""  BSM_LS,VICM_LS
 SG_ LBCCDRR_PosNum : 18|3@0+ (1,0) [0|7] ""  BSM_LS,VICM_LS
 SG_ USBProgInPrgrs : 9|1@0+ (1,0) [0|1] ""  BCM_LS
 SG_ EngyCnsHistGrphRstRq : 8|1@0+ (1,0) [0|1] ""  BSM_LS,VICM_LS
 SG_ DsplTrnsShftLvrLckRqd : 7|1@0+ (1,0) [0|1] ""  BCM_LS
 SG_ EngAstHtPlgInCstStRq : 6|3@0+ (1,0) [0|7] ""  BSM_LS,VICM_LS
 SG_ EngAstHtCstStRq : 3|3@0+ (1,0) [0|7] ""  BSM_LS,VICM_LS
 SG_ MntnceMdStEngRq : 0|1@0+ (1,0) [0|1] ""  BSM_LS,VICM_LS

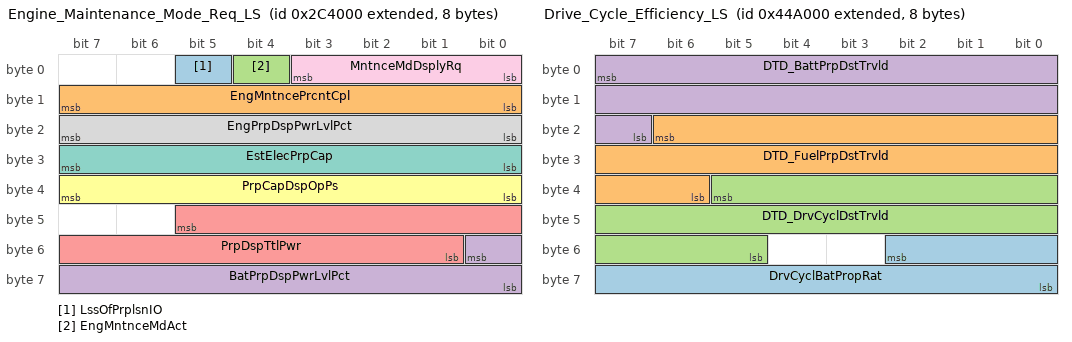
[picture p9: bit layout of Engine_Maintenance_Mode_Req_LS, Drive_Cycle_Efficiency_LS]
BO_ 2150383616 Engine_Maintenance_Mode_Req_LS: 8 VICM_LS
 SG_ LssOfPrplsnIO : 5|1@0+ (1,0) [0|1] ""  CGM_LS,IPC_LS
 SG_ EngMntncePrcntCpl : 15|8@0+ (0.392157,0) [0|100.000035] "%"  CGM_LS,IPC_LS
 SG_ EngMntnceMdAct : 4|1@0+ (1,0) [0|1] ""  CGM_LS,IPC_LS
 SG_ BatPrpDspPwrLvlPct : 48|9@0- (0.392157,0) [-100.392192|100.000035] "%"  CSM_LS,CGM_LS,IPC_LS
 SG_ PrpDspTtlPwr : 45|13@0+ (0.5,-326.6) [-326.6|3768.9] "kW"  CSM_LS,RadioHead_LS,CGM_LS,IPC_LS
 SG_ PrpCapDspOpPs : 39|8@0+ (0.392157,0) [0|100.000035] "%"  CSM_LS,RadioHead_LS,CGM_LS,IPC_LS
 SG_ EstElecPrpCap : 31|8@0+ (0.392157,0) [0|100.000035] "%"  CSM_LS,ONSTAR_LS,CGM_LS,IPC_LS
 SG_ EngPrpDspPwrLvlPct : 23|8@0+ (0.392157,0) [0|100.000035] "%"  CSM_LS,RadioHead_LS,CGM_LS,IPC_LS
 SG_ MntnceMdDsplyRq : 3|4@0+ (1,0) [0|15] ""  CGM_LS,CSM_LS,RadioHead_LS

BO_ 2151981056 Drive_Cycle_Efficiency_LS: 8 VICM_LS
 SG_ DrvCyclBatPropRat : 50|11@0+ (0.048852,0) [0|100.000044] "%"  CGM_LS,CSM_LS,RadioHead_LS
 SG_ DTD_FuelPrpDstTrvld : 22|17@0+ (0.015625,0) [0|2047.984375] "km"  CGM_LS,CSM_LS,RadioHead_LS
 SG_ DTD_DrvCyclDstTrvld : 37|17@0+ (0.015625,0) [0|2047.984375] "km"  CGM_LS,CSM_LS,RadioHead_LS
 SG_ DTD_BattPrpDstTrvld : 7|17@0+ (0.015625,0) [0|2047.984375] "km"  CGM_LS,CSM_LS,RadioHead_LS

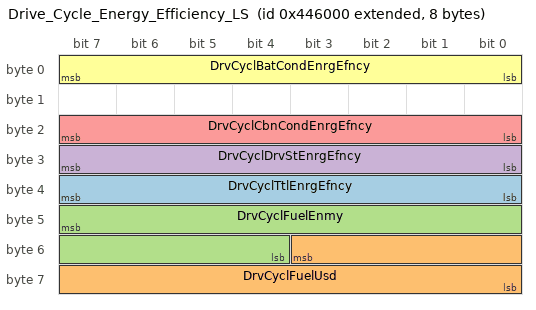
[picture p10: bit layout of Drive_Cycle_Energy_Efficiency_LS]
BO_ 2151964672 Drive_Cycle_Energy_Efficiency_LS: 8 VICM_LS
 SG_ DrvCyclTtlEnrgEfncy : 39|8@0+ (0.392157,0) [0|100.000035] "%"  CGM_LS,CSM_LS,RadioHead_LS
 SG_ DrvCyclFuelUsd : 51|12@0+ (0.125,0) [0|511.875] "liters"  CGM_LS,CSM_LS,RadioHead_LS
 SG_ DrvCyclFuelEnmy : 47|12@0+ (0.1,0) [0|409.5] "km/liters"  CGM_LS,CSM_LS,RadioHead_LS
 SG_ DrvCyclDrvStEnrgEfncy : 31|8@0+ (0.392157,0) [0|100.000035] "%"  CGM_LS,CSM_LS,RadioHead_LS
 SG_ DrvCyclCbnCondEnrgEfncy : 23|8@0+ (0.392157,0) [0|100.000035] "%"  CGM_LS,CSM_LS,RadioHead_LS
 SG_ DrvCyclBatCondEnrgEfncy : 7|8@0+ (0.392157,0) [0|100.000035] "%"  CGM_LS,CSM_LS,RadioHead_LS

BO_TX_BU_ 2151448576 : CGM_LS,V2V_LS;
BO_TX_BU_ 2153914368 : BSM_LS,VICM_LS;
BO_TX_BU_ 2151882752 : CGM_LS,CSM_LS,RadioHead_LS;
BO_TX_BU_ 2150580224 : BSM_LS,VICM_LS;
BO_TX_BU_ 2020 : CSM_LS,CGM_LS,TCP_LS,ONSTAR_LS,TestTool_LS;
BO_TX_BU_ 2151735296 : EOCM2A_K2_LS,SBZA_L_LS;
BO_TX_BU_ 2151792640 : EOCM2A_K2_LS,SBZA_L_LS,SBZA_R_LS;
BO_TX_BU_ 2149826560 : VIS2_LS,FCM_LS;
BO_TX_BU_ 2149957632 : EOCM2A_K2_LS,EOCM_F_LS;
BO_TX_BU_ 2149941248 : UPA_LS,APA_LS;
BO_TX_BU_ 2149810176 : EOCM2B_K2_LS,FCM_LS,BCM_LS;
BO_TX_BU_ 2149793792 : EOCM_F_LS,BCM_LS,FCM_LS;
BO_TX_BU_ 2150080512 : BSM_LS,VICM_LS;
BO_TX_BU_ 2151997440 : VIS2_LS,FCM_LS;
BO_TX_BU_ 2156331008 : BSM_LS,VICM_LS;
BO_TX_BU_ 2151776256 : EOCM2A_K2_LS,SBZA_L_LS;
BO_TX_BU_ 2150375424 : CGM_LS,CSM_LS,RadioHead_LS;
BO_TX_BU_ 2150383616 : BSM_LS,VICM_LS;
BO_TX_BU_ 2151981056 : BSM_LS,VICM_LS;
BO_TX_BU_ 2151964672 : BSM_LS,VICM_LS;
CM_ SG_ 2151899136 PTORelBrkPedIO "Power Take Off Release Brake Pedal To Engage Indication On";
BA_DEF_ SG_  "VNSigPrimaryTriggering" ENUM  "No","Yes","DLCLS","DLCHS","DLCCE","DLCFO";
BA_DEF_ SG_  "VNSigRemoteDiagnostics" ENUM  "No","Yes","DLCLS","DLCHS","DLCCE","DLCFO";
BA_DEF_ SG_  "VNSigInfotainment" ENUM  "No","Yes","DLCLS","DLCHS","DLCCE","DLCFO";
BA_DEF_ SG_  "VNSigParkedVehicle" ENUM  "No","Yes","DLCLS","DLCHS","DLCCE","DLCFO";
BA_DEF_ SG_  "VNSigIntermediate" ENUM  "No","Yes","DLCLS","DLCHS","DLCCE","DLCFO";
BA_DEF_ SG_  "VNSigUnused_4" ENUM  "No","Yes","DLCLS","DLCHS","DLCCE","DLCFO";
BA_DEF_ SG_  "SignalType" STRING ;
BA_DEF_ SG_  "PacketOrder" INT 0 65535;
BA_DEF_ SG_  "SignalLongName" STRING ;
BA_DEF_ SG_  "GenSigStartValue" INT 0 65535;
BA_DEF_ SG_  "VNSigDiagnostic" ENUM  "No","Yes","DLCLS","DLCHS","DLCCE","DLCFO";
BA_DEF_ SG_  "VNSigAllNodes" ENUM  "No","Yes","DLCLS","DLCHS","DLCCE","DLCFO";
BA_DEF_ SG_  "GenSigDeltaValue" INT 0 0;
BA_DEF_ SG_  "GenSigInactiveValue" INT 0 0;
BA_DEF_ SG_  "GenSigSendType" ENUM  "not used","not used","not used","not used","not used","not used","not used","NoSigSendType","not used","not used","OnAnyChange","OnChangeIfActive","OnDelta","DLCLS","DLCHS","DLCCE","DLCFO";
BA_DEF_ SG_  "GenSigSendOnInit" ENUM  "Not Initialized","Application","Handler","DLCLS","DLCHS","DLCCE","DLCFO";
BA_DEF_ BO_  "AppGenMsgCycleTime" INT 0 0;
BA_DEF_ BO_  "TpTxIndex" INT 0 99;
BA_DEF_ BO_  "GenMsgILSupport" ENUM  "No","Yes","DLCLS","DLCHS","DLCCE","DLCFO";
BA_DEF_ BO_  "TpApplType" STRING ;
BA_DEF_ BO_  "Prio" INT 0 7;
BA_DEF_ BO_  "MessageSubnet" ENUM  "LS","MS","HS","CE","PE","HV","FO","S1","HE","LE","HE2","DLCLS","DLCHS","DLCCE","DLCFO";
BA_DEF_ BO_  "GenMsgMandatoryToSupervision" ENUM  "No","Yes","DLCLS","DLCHS","DLCCE","DLCFO";
BA_DEF_ BO_  "DiagState" ENUM  "No","Yes","DLCLS","DLCHS","DLCCE","DLCFO";
BA_DEF_ BO_  "GenMsgStartDelayTime" INT 0 100000;
BA_DEF_ BO_  "GenMsgDelayTime" INT 0 100000;
BA_DEF_ BO_  "GenMsgCycleTime" INT 0 100000;
BA_DEF_ BO_  "GenMsgSendType" ENUM  "cyclicX","spontanX","cyclicIfActiveX","spontanWithDelay","cyclicAndSpontanX","cyclicAndSpontanWithDelay","spontanWithRepitition","cyclicIfActiveAndSpontanWD","DLCLS","DLCHS","DLCCE","DLCFO";
BA_DEF_ BO_  "DiagResponse" ENUM  "No","Yes","DLCLS","DLCHS","DLCCE","DLCFO";
BA_DEF_ BO_  "DiagRequest" ENUM  "No","Yes","DLCLS","DLCHS","DLCCE","DLCFO";
BA_DEF_ BO_  "NmMessage" ENUM  "No","Yes","DLCLS","DLCHS","DLCCE","DLCFO";
BA_DEF_REL_ BU_SG_REL_  "GenSigSuprvRespComment" STRING ;
BA_DEF_REL_ BU_SG_REL_  "GenSigVBitResp" ENUM  "No","Yes","DLCLS","DLCHS","DLCCE","DLCFO";
BA_DEF_REL_ BU_SG_REL_  "GenSigVBitRespComment" STRING ;
BA_DEF_REL_ BU_SG_REL_  "GenSigVDAFailComment" STRING ;
BA_DEF_REL_ BU_SG_REL_  "GenSigVDAFailResp" ENUM  "No","Yes","DLCLS","DLCHS","DLCCE","DLCFO";
BA_DEF_REL_ BU_SG_REL_  "GenSigRxStartValue" STRING ;
BA_DEF_REL_ BU_SG_REL_  "GenSigSuprvRespSubValue" INT 0 65535;
BA_DEF_REL_ BU_SG_REL_  "GenSigSuprvResp" ENUM  "None","Notify App","Substitute Default","DLCLS","DLCHS","DLCCE","DLCFO";
BA_DEF_REL_ BU_SG_REL_  "GenSigTimeoutMsg" HEX -2147483648 268435455;
BA_DEF_REL_ BU_SG_REL_  "GenSigTimeoutTime" INT 0 15000;
BA_DEF_DEF_  "VNSigPrimaryTriggering" "No";
BA_DEF_DEF_  "VNSigRemoteDiagnostics" "No";
BA_DEF_DEF_  "VNSigInfotainment" "No";
BA_DEF_DEF_  "VNSigParkedVehicle" "No";
BA_DEF_DEF_  "VNSigIntermediate" "No";
BA_DEF_DEF_  "VNSigUnused_4" "No";
BA_DEF_DEF_  "SignalType" "";
BA_DEF_DEF_  "PacketOrder" 0;
BA_DEF_DEF_  "SignalLongName" "";
BA_DEF_DEF_  "GenSigStartValue" 0;
BA_DEF_DEF_  "VNSigDiagnostic" "No";
BA_DEF_DEF_  "VNSigAllNodes" "No";
BA_DEF_DEF_  "GenSigDeltaValue" 0;
BA_DEF_DEF_  "GenSigInactiveValue" 0;
BA_DEF_DEF_  "GenSigSendType" "NoSigSendType";
BA_DEF_DEF_  "GenSigSendOnInit" "Not Initialized";
BA_DEF_DEF_  "AppGenMsgCycleTime" 0;
BA_DEF_DEF_  "TpTxIndex" 0;
BA_DEF_DEF_  "GenMsgILSupport" "Yes";
BA_DEF_DEF_  "TpApplType" "";
BA_DEF_DEF_  "Prio" 4;
BA_DEF_DEF_  "MessageSubnet" "FO";
BA_DEF_DEF_  "GenMsgMandatoryToSupervision" "No";
BA_DEF_DEF_  "DiagState" "No";
BA_DEF_DEF_  "GenMsgStartDelayTime" 0;
BA_DEF_DEF_  "GenMsgDelayTime" 0;
BA_DEF_DEF_  "GenMsgCycleTime" 0;
BA_DEF_DEF_  "GenMsgSendType" "spontanX";
BA_DEF_DEF_  "DiagResponse" "No";
BA_DEF_DEF_  "DiagRequest" "No";
BA_DEF_DEF_  "NmMessage" "No";
BA_DEF_DEF_REL_ "GenSigSuprvRespComment" "";
BA_DEF_DEF_REL_ "GenSigVBitResp" "No";
BA_DEF_DEF_REL_ "GenSigVBitRespComment" "";
BA_DEF_DEF_REL_ "GenSigVDAFailComment" "";
BA_DEF_DEF_REL_ "GenSigVDAFailResp" "No";
BA_DEF_DEF_REL_ "GenSigRxStartValue" "";
BA_DEF_DEF_REL_ "GenSigSuprvRespSubValue" 0;
BA_DEF_DEF_REL_ "GenSigSuprvResp" "None";
BA_DEF_DEF_REL_ "GenSigTimeoutMsg" 0;
BA_DEF_DEF_REL_ "GenSigTimeoutTime" 0;
BA_ "MessageSubnet" BO_ 2151292928 0;
BA_ "GenMsgDelayTime" BO_ 2151292928 100;
BA_ "MessageSubnet" BO_ 2151464960 0;
BA_ "GenMsgDelayTime" BO_ 2151464960 100;
BA_ "MessageSubnet" BO_ 2151448576 0;
BA_ "GenMsgDelayTime" BO_ 2151448576 100;
BA_ "MessageSubnet" BO_ 2153930752 0;
BA_ "GenMsgDelayTime" BO_ 2153930752 100;
BA_ "AppGenMsgCycleTime" BO_ 2153889792 250;
BA_ "MessageSubnet" BO_ 2153889792 0;
BA_ "GenMsgDelayTime" BO_ 2153889792 100;
BA_ "MessageSubnet" BO_ 2153914368 0;
BA_ "GenMsgDelayTime" BO_ 2153914368 100;
BA_ "MessageSubnet" BO_ 2151882752 0;
BA_ "GenMsgDelayTime" BO_ 2151882752 100;
BA_ "MessageSubnet" BO_ 2151899136 0;
BA_ "GenMsgCycleTime" BO_ 2151899136 250;
BA_ "GenMsgSendType" BO_ 2151899136 0;
BA_ "MessageSubnet" BO_ 2150580224 0;
BA_ "GenMsgDelayTime" BO_ 2150580224 100;
BA_ "Prio" BO_ 2020 0;
BA_ "MessageSubnet" BO_ 2020 0;
BA_ "DiagRequest" BO_ 2020 1;
BA_ "MessageSubnet" BO_ 2151735296 0;
BA_ "GenMsgDelayTime" BO_ 2151735296 100;
BA_ "MessageSubnet" BO_ 2151792640 0;
BA_ "GenMsgDelayTime" BO_ 2151792640 100;
BA_ "MessageSubnet" BO_ 2149826560 0;
BA_ "GenMsgDelayTime" BO_ 2149826560 100;
BA_ "MessageSubnet" BO_ 2149957632 0;
BA_ "GenMsgDelayTime" BO_ 2149957632 100;
BA_ "MessageSubnet" BO_ 2149941248 0;
BA_ "GenMsgDelayTime" BO_ 2149941248 30;
BA_ "MessageSubnet" BO_ 2156314624 0;
BA_ "GenMsgDelayTime" BO_ 2156314624 100;
BA_ "MessageSubnet" BO_ 2150449152 0;
BA_ "GenMsgDelayTime" BO_ 2150449152 100;
BA_ "MessageSubnet" BO_ 2149810176 0;
BA_ "GenMsgDelayTime" BO_ 2149810176 100;
BA_ "MessageSubnet" BO_ 2149793792 0;
BA_ "GenMsgDelayTime" BO_ 2149793792 100;
BA_ "MessageSubnet" BO_ 2150080512 0;
BA_ "GenMsgDelayTime" BO_ 2150080512 100;
BA_ "MessageSubnet" BO_ 2153873408 0;
BA_ "GenMsgDelayTime" BO_ 2153873408 100;
BA_ "MessageSubnet" BO_ 2152128512 0;
BA_ "GenMsgCycleTime" BO_ 2152128512 2000;
BA_ "GenMsgSendType" BO_ 2152128512 0;
BA_ "MessageSubnet" BO_ 2151997440 0;
BA_ "GenMsgDelayTime" BO_ 2151997440 100;
BA_ "MessageSubnet" BO_ 2156331008 0;
BA_ "GenMsgDelayTime" BO_ 2156331008 100;
BA_ "MessageSubnet" BO_ 2151776256 0;
BA_ "GenMsgDelayTime" BO_ 2151776256 100;
BA_ "MessageSubnet" BO_ 2154774528 0;
BA_ "GenMsgDelayTime" BO_ 2154774528 100;
BA_ "MessageSubnet" BO_ 2150375424 0;
BA_ "GenMsgDelayTime" BO_ 2150375424 100;
BA_ "MessageSubnet" BO_ 2150383616 0;
BA_ "GenMsgDelayTime" BO_ 2150383616 100;
BA_ "MessageSubnet" BO_ 2151981056 0;
BA_ "GenMsgDelayTime" BO_ 2151981056 100;
BA_ "MessageSubnet" BO_ 2151964672 0;
BA_ "GenMsgDelayTime" BO_ 2151964672 100;
BA_ "GenSigSendType" SG_ 2151292928 TrfRdsdInfCsStAvail 10;
BA_ "GenSigSendOnInit" SG_ 2151292928 TrfRdsdInfCsStAvail 2;
BA_ "SignalType" SG_ 2151292928 TrfRdsdInfCsStAvail "BLN";
BA_ "SignalLongName" SG_ 2151292928 TrfRdsdInfCsStAvail "Traffic and Roadside Information Customization Setting Available";
BA_ "VNSigAllNodes" SG_ 2151292928 TrfRdsdInfCsStAvail 1;
BA_ "GenSigSendType" SG_ 2151292928 TrfRdsdInfCsCrStVal 10;
BA_ "GenSigSendOnInit" SG_ 2151292928 TrfRdsdInfCsCrStVal 2;
BA_ "SignalType" SG_ 2151292928 TrfRdsdInfCsCrStVal "ENM";
BA_ "SignalLongName" SG_ 2151292928 TrfRdsdInfCsCrStVal "Traffic and Roadside Information Customization Current Setting Value";
BA_ "VNSigAllNodes" SG_ 2151292928 TrfRdsdInfCsCrStVal 1;
BA_ "GenSigSendType" SG_ 2151292928 TRICA_Resrv5Avail 10;
BA_ "GenSigSendOnInit" SG_ 2151292928 TRICA_Resrv5Avail 2;
BA_ "SignalType" SG_ 2151292928 TRICA_Resrv5Avail "BLN";
BA_ "PacketOrder" SG_ 2151292928 TRICA_Resrv5Avail 7;
BA_ "SignalLongName" SG_ 2151292928 TRICA_Resrv5Avail "Traffic and Roadside Information Customization Available : Reserved5 Available";
BA_ "VNSigAllNodes" SG_ 2151292928 TRICA_Resrv5Avail 1;
BA_ "GenSigSendType" SG_ 2151292928 TRICA_Resrv4Avail 10;
BA_ "GenSigSendOnInit" SG_ 2151292928 TRICA_Resrv4Avail 2;
BA_ "SignalType" SG_ 2151292928 TRICA_Resrv4Avail "BLN";
BA_ "PacketOrder" SG_ 2151292928 TRICA_Resrv4Avail 6;
BA_ "SignalLongName" SG_ 2151292928 TRICA_Resrv4Avail "Traffic and Roadside Information Customization Available : Reserved4 Available";
BA_ "VNSigAllNodes" SG_ 2151292928 TRICA_Resrv4Avail 1;
BA_ "GenSigSendType" SG_ 2151292928 TRICA_Resrv3Avail 10;
BA_ "GenSigSendOnInit" SG_ 2151292928 TRICA_Resrv3Avail 2;
BA_ "SignalType" SG_ 2151292928 TRICA_Resrv3Avail "BLN";
BA_ "PacketOrder" SG_ 2151292928 TRICA_Resrv3Avail 5;
BA_ "SignalLongName" SG_ 2151292928 TRICA_Resrv3Avail "Traffic and Roadside Information Customization Available : Reserved3 Available";
BA_ "VNSigAllNodes" SG_ 2151292928 TRICA_Resrv3Avail 1;
BA_ "GenSigSendType" SG_ 2151292928 TRICA_Resrv2Avail 10;
BA_ "GenSigSendOnInit" SG_ 2151292928 TRICA_Resrv2Avail 2;
BA_ "SignalType" SG_ 2151292928 TRICA_Resrv2Avail "BLN";
BA_ "PacketOrder" SG_ 2151292928 TRICA_Resrv2Avail 4;
BA_ "SignalLongName" SG_ 2151292928 TRICA_Resrv2Avail "Traffic and Roadside Information Customization Available : Reserved2 Available";
BA_ "VNSigAllNodes" SG_ 2151292928 TRICA_Resrv2Avail 1;
BA_ "GenSigSendType" SG_ 2151292928 TRICA_Resrv1Avail 10;
BA_ "GenSigSendOnInit" SG_ 2151292928 TRICA_Resrv1Avail 2;
BA_ "SignalType" SG_ 2151292928 TRICA_Resrv1Avail "BLN";
BA_ "PacketOrder" SG_ 2151292928 TRICA_Resrv1Avail 3;
BA_ "SignalLongName" SG_ 2151292928 TRICA_Resrv1Avail "Traffic and Roadside Information Customization Available : Reserved1 Available";
BA_ "VNSigAllNodes" SG_ 2151292928 TRICA_Resrv1Avail 1;
BA_ "GenSigSendType" SG_ 2151292928 TRICA_OnAvail 10;
BA_ "GenSigSendOnInit" SG_ 2151292928 TRICA_OnAvail 2;
BA_ "SignalType" SG_ 2151292928 TRICA_OnAvail "BLN";
BA_ "PacketOrder" SG_ 2151292928 TRICA_OnAvail 2;
BA_ "SignalLongName" SG_ 2151292928 TRICA_OnAvail "Traffic and Roadside Information Customization Available : On Available";
BA_ "VNSigAllNodes" SG_ 2151292928 TRICA_OnAvail 1;
BA_ "GenSigSendType" SG_ 2151292928 TRICA_OfAvail 10;
BA_ "GenSigSendOnInit" SG_ 2151292928 TRICA_OfAvail 2;
BA_ "SignalType" SG_ 2151292928 TRICA_OfAvail "BLN";
BA_ "PacketOrder" SG_ 2151292928 TRICA_OfAvail 1;
BA_ "SignalLongName" SG_ 2151292928 TRICA_OfAvail "Traffic and Roadside Information Customization Available : Off Available";
BA_ "VNSigAllNodes" SG_ 2151292928 TRICA_OfAvail 1;
BA_ "GenSigSendType" SG_ 2151292928 IntrStopAlrtCsSetAvl 10;
BA_ "GenSigSendOnInit" SG_ 2151292928 IntrStopAlrtCsSetAvl 2;
BA_ "SignalType" SG_ 2151292928 IntrStopAlrtCsSetAvl "BLN";
BA_ "SignalLongName" SG_ 2151292928 IntrStopAlrtCsSetAvl "Intersection Stop Alert Customization Setting Available";
BA_ "VNSigAllNodes" SG_ 2151292928 IntrStopAlrtCsSetAvl 1;
BA_ "GenSigSendType" SG_ 2151292928 IntrStAlrtCsCrSetVal 10;
BA_ "GenSigSendOnInit" SG_ 2151292928 IntrStAlrtCsCrSetVal 2;
BA_ "SignalType" SG_ 2151292928 IntrStAlrtCsCrSetVal "ENM";
BA_ "SignalLongName" SG_ 2151292928 IntrStAlrtCsCrSetVal "Intersection Stop Alert Customization Current Setting Value";
BA_ "VNSigAllNodes" SG_ 2151292928 IntrStAlrtCsCrSetVal 1;
BA_ "GenSigSendType" SG_ 2151292928 ISACA_Resrv4Avail 10;
BA_ "GenSigSendOnInit" SG_ 2151292928 ISACA_Resrv4Avail 2;
BA_ "SignalType" SG_ 2151292928 ISACA_Resrv4Avail "BLN";
BA_ "PacketOrder" SG_ 2151292928 ISACA_Resrv4Avail 7;
BA_ "SignalLongName" SG_ 2151292928 ISACA_Resrv4Avail "Intersection Stop Alert Customization Available : Reserved4 Available";
BA_ "VNSigAllNodes" SG_ 2151292928 ISACA_Resrv4Avail 1;
BA_ "GenSigSendType" SG_ 2151292928 ISACA_Resrv3Avail 10;
BA_ "GenSigSendOnInit" SG_ 2151292928 ISACA_Resrv3Avail 2;
BA_ "SignalType" SG_ 2151292928 ISACA_Resrv3Avail "BLN";
BA_ "PacketOrder" SG_ 2151292928 ISACA_Resrv3Avail 6;
BA_ "SignalLongName" SG_ 2151292928 ISACA_Resrv3Avail "Intersection Stop Alert Customization Available : Reserved3 Available";
BA_ "VNSigAllNodes" SG_ 2151292928 ISACA_Resrv3Avail 1;
BA_ "GenSigSendType" SG_ 2151292928 ISACA_Resrv2Avail 10;
BA_ "GenSigSendOnInit" SG_ 2151292928 ISACA_Resrv2Avail 2;
BA_ "SignalType" SG_ 2151292928 ISACA_Resrv2Avail "BLN";
BA_ "PacketOrder" SG_ 2151292928 ISACA_Resrv2Avail 5;
BA_ "SignalLongName" SG_ 2151292928 ISACA_Resrv2Avail "Intersection Stop Alert Customization Available : Reserved2 Available";
BA_ "VNSigAllNodes" SG_ 2151292928 ISACA_Resrv2Avail 1;
BA_ "GenSigSendType" SG_ 2151292928 ISACA_Resrv1Avail 10;
BA_ "GenSigSendOnInit" SG_ 2151292928 ISACA_Resrv1Avail 2;
BA_ "SignalType" SG_ 2151292928 ISACA_Resrv1Avail "BLN";
BA_ "PacketOrder" SG_ 2151292928 ISACA_Resrv1Avail 4;
BA_ "SignalLongName" SG_ 2151292928 ISACA_Resrv1Avail "Intersection Stop Alert Customization Available : Reserved1 Available";
BA_ "VNSigAllNodes" SG_ 2151292928 ISACA_Resrv1Avail 1;
BA_ "GenSigSendType" SG_ 2151292928 ISACA_AlrtBrkAvail 10;
BA_ "GenSigSendOnInit" SG_ 2151292928 ISACA_AlrtBrkAvail 2;
BA_ "SignalType" SG_ 2151292928 ISACA_AlrtBrkAvail "BLN";
BA_ "PacketOrder" SG_ 2151292928 ISACA_AlrtBrkAvail 3;
BA_ "SignalLongName" SG_ 2151292928 ISACA_AlrtBrkAvail "Intersection Stop Alert Customization Available : Alert and Brake Available";
BA_ "VNSigAllNodes" SG_ 2151292928 ISACA_AlrtBrkAvail 1;
BA_ "GenSigSendType" SG_ 2151292928 ISACA_AlrtAvail 10;
BA_ "GenSigSendOnInit" SG_ 2151292928 ISACA_AlrtAvail 2;
BA_ "SignalType" SG_ 2151292928 ISACA_AlrtAvail "BLN";
BA_ "PacketOrder" SG_ 2151292928 ISACA_AlrtAvail 2;
BA_ "SignalLongName" SG_ 2151292928 ISACA_AlrtAvail "Intersection Stop Alert Customization Available : Alert Available";
BA_ "VNSigAllNodes" SG_ 2151292928 ISACA_AlrtAvail 1;
BA_ "GenSigSendType" SG_ 2151292928 ISACA_OfAvail 10;
BA_ "GenSigSendOnInit" SG_ 2151292928 ISACA_OfAvail 2;
BA_ "SignalType" SG_ 2151292928 ISACA_OfAvail "BLN";
BA_ "PacketOrder" SG_ 2151292928 ISACA_OfAvail 1;
BA_ "SignalLongName" SG_ 2151292928 ISACA_OfAvail "Intersection Stop Alert Customization Available : Off Available";
BA_ "VNSigAllNodes" SG_ 2151292928 ISACA_OfAvail 1;
BA_ "GenSigSendType" SG_ 2151292928 CntdVehBrkAltCsStAvl 10;
BA_ "GenSigSendOnInit" SG_ 2151292928 CntdVehBrkAltCsStAvl 2;
BA_ "SignalType" SG_ 2151292928 CntdVehBrkAltCsStAvl "BLN";
BA_ "SignalLongName" SG_ 2151292928 CntdVehBrkAltCsStAvl "Connected Vehicle Braking Alerts Customization Setting Available";
BA_ "VNSigAllNodes" SG_ 2151292928 CntdVehBrkAltCsStAvl 1;
BA_ "GenSigSendType" SG_ 2151292928 CntdVehBrAltCsCrStVal 10;
BA_ "GenSigSendOnInit" SG_ 2151292928 CntdVehBrAltCsCrStVal 2;
BA_ "SignalType" SG_ 2151292928 CntdVehBrAltCsCrStVal "ENM";
BA_ "SignalLongName" SG_ 2151292928 CntdVehBrAltCsCrStVal "Connected Vehicle Braking Alerts Customization Current Setting Value";
BA_ "VNSigAllNodes" SG_ 2151292928 CntdVehBrAltCsCrStVal 1;
BA_ "GenSigSendType" SG_ 2151292928 CVBACA_Resrv5Avail 10;
BA_ "GenSigSendOnInit" SG_ 2151292928 CVBACA_Resrv5Avail 2;
BA_ "SignalType" SG_ 2151292928 CVBACA_Resrv5Avail "BLN";
BA_ "PacketOrder" SG_ 2151292928 CVBACA_Resrv5Avail 7;
BA_ "SignalLongName" SG_ 2151292928 CVBACA_Resrv5Avail "Connected Vehicle Braking Alerts Customization Available : Reserved5 Available";
BA_ "VNSigAllNodes" SG_ 2151292928 CVBACA_Resrv5Avail 1;
BA_ "GenSigSendType" SG_ 2151292928 CVBACA_Resrv4Avail 10;
BA_ "GenSigSendOnInit" SG_ 2151292928 CVBACA_Resrv4Avail 2;
BA_ "SignalType" SG_ 2151292928 CVBACA_Resrv4Avail "BLN";
BA_ "PacketOrder" SG_ 2151292928 CVBACA_Resrv4Avail 6;
BA_ "SignalLongName" SG_ 2151292928 CVBACA_Resrv4Avail "Connected Vehicle Braking Alerts Customization Available : Reserved4 Available";
BA_ "VNSigAllNodes" SG_ 2151292928 CVBACA_Resrv4Avail 1;
BA_ "GenSigSendType" SG_ 2151292928 CVBACA_Resrv3Avail 10;
BA_ "GenSigSendOnInit" SG_ 2151292928 CVBACA_Resrv3Avail 2;
BA_ "SignalType" SG_ 2151292928 CVBACA_Resrv3Avail "BLN";
BA_ "PacketOrder" SG_ 2151292928 CVBACA_Resrv3Avail 5;
BA_ "SignalLongName" SG_ 2151292928 CVBACA_Resrv3Avail "Connected Vehicle Braking Alerts Customization Available : Reserved3 Available";
BA_ "VNSigAllNodes" SG_ 2151292928 CVBACA_Resrv3Avail 1;
BA_ "GenSigSendType" SG_ 2151292928 CVBACA_Resrv2Avail 10;
BA_ "GenSigSendOnInit" SG_ 2151292928 CVBACA_Resrv2Avail 2;
BA_ "SignalType" SG_ 2151292928 CVBACA_Resrv2Avail "BLN";
BA_ "PacketOrder" SG_ 2151292928 CVBACA_Resrv2Avail 4;
BA_ "SignalLongName" SG_ 2151292928 CVBACA_Resrv2Avail "Connected Vehicle Braking Alerts Customization Available : Reserved2 Available";
BA_ "VNSigAllNodes" SG_ 2151292928 CVBACA_Resrv2Avail 1;
BA_ "GenSigSendType" SG_ 2151292928 CVBACA_Resrv1Avail 10;
BA_ "GenSigSendOnInit" SG_ 2151292928 CVBACA_Resrv1Avail 2;
BA_ "SignalType" SG_ 2151292928 CVBACA_Resrv1Avail "BLN";
BA_ "PacketOrder" SG_ 2151292928 CVBACA_Resrv1Avail 3;
BA_ "SignalLongName" SG_ 2151292928 CVBACA_Resrv1Avail "Connected Vehicle Braking Alerts Customization Available : Reserved1 Available";
BA_ "VNSigAllNodes" SG_ 2151292928 CVBACA_Resrv1Avail 1;
BA_ "GenSigSendType" SG_ 2151292928 CVBACA_OnAvail 10;
BA_ "GenSigSendOnInit" SG_ 2151292928 CVBACA_OnAvail 2;
BA_ "SignalType" SG_ 2151292928 CVBACA_OnAvail "BLN";
BA_ "PacketOrder" SG_ 2151292928 CVBACA_OnAvail 2;
BA_ "SignalLongName" SG_ 2151292928 CVBACA_OnAvail "Connected Vehicle Braking Alerts Customization Available : On Available";
BA_ "VNSigAllNodes" SG_ 2151292928 CVBACA_OnAvail 1;
BA_ "GenSigSendType" SG_ 2151292928 CVBACA_OfAvail 10;
BA_ "GenSigSendOnInit" SG_ 2151292928 CVBACA_OfAvail 2;
BA_ "SignalType" SG_ 2151292928 CVBACA_OfAvail "BLN";
BA_ "PacketOrder" SG_ 2151292928 CVBACA_OfAvail 1;
BA_ "SignalLongName" SG_ 2151292928 CVBACA_OfAvail "Connected Vehicle Braking Alerts Customization Available : Off Available";
BA_ "VNSigAllNodes" SG_ 2151292928 CVBACA_OfAvail 1;
BA_ "GenSigDeltaValue" SG_ 2151464960 V2VSR_TrfLghtDispLim 1;
BA_ "GenSigSendType" SG_ 2151464960 V2VSR_TrfLghtDispLim 12;
BA_ "PacketOrder" SG_ 2151464960 V2VSR_TrfLghtDispLim 3;
BA_ "SignalType" SG_ 2151464960 V2VSR_TrfLghtDispLim "UNM";
BA_ "SignalLongName" SG_ 2151464960 V2VSR_TrfLghtDispLim "Vehicle to Vehicle Speed Recommendation : Traffic Light Maximum Display Limit";
BA_ "VNSigAllNodes" SG_ 2151464960 V2VSR_TrfLghtDispLim 1;
BA_ "GenSigDeltaValue" SG_ 2151464960 V2VSR_TrfLghtMaxRecmndSpd 1;
BA_ "GenSigSendType" SG_ 2151464960 V2VSR_TrfLghtMaxRecmndSpd 12;
BA_ "PacketOrder" SG_ 2151464960 V2VSR_TrfLghtMaxRecmndSpd 2;
BA_ "SignalType" SG_ 2151464960 V2VSR_TrfLghtMaxRecmndSpd "UNM";
BA_ "SignalLongName" SG_ 2151464960 V2VSR_TrfLghtMaxRecmndSpd "Vehicle to Vehicle Speed Recommendation : Traffic Light Maximum Recommended Speed";
BA_ "VNSigAllNodes" SG_ 2151464960 V2VSR_TrfLghtMaxRecmndSpd 1;
BA_ "GenSigDeltaValue" SG_ 2151464960 V2VSR_TrfLghtMinRecmndSpd 1;
BA_ "GenSigSendType" SG_ 2151464960 V2VSR_TrfLghtMinRecmndSpd 12;
BA_ "PacketOrder" SG_ 2151464960 V2VSR_TrfLghtMinRecmndSpd 1;
BA_ "SignalType" SG_ 2151464960 V2VSR_TrfLghtMinRecmndSpd "UNM";
BA_ "SignalLongName" SG_ 2151464960 V2VSR_TrfLghtMinRecmndSpd "Vehicle to Vehicle Speed Recommendation : Traffic Light Minimum Recommended Speed";
BA_ "VNSigAllNodes" SG_ 2151464960 V2VSR_TrfLghtMinRecmndSpd 1;
BA_ "GenSigSendType" SG_ 2151464960 V2VWrngIndReq 10;
BA_ "SignalType" SG_ 2151464960 V2VWrngIndReq "ENM";
BA_ "SignalLongName" SG_ 2151464960 V2VWrngIndReq "Vehicle To Vehicle Warning Indication Request";
BA_ "VNSigAllNodes" SG_ 2151464960 V2VWrngIndReq 1;
BA_ "GenSigDeltaValue" SG_ 2151464960 V2VWrngDistRemng 1;
BA_ "GenSigSendType" SG_ 2151464960 V2VWrngDistRemng 12;
BA_ "SignalType" SG_ 2151464960 V2VWrngDistRemng "UNM";
BA_ "SignalLongName" SG_ 2151464960 V2VWrngDistRemng "Vehicle to Vehicle Warning Distance Remaining";
BA_ "VNSigAllNodes" SG_ 2151464960 V2VWrngDistRemng 1;
BA_ "GenSigSendType" SG_ 2151464960 V2VWrngDirctn 10;
BA_ "SignalType" SG_ 2151464960 V2VWrngDirctn "ENM";
BA_ "SignalLongName" SG_ 2151464960 V2VWrngDirctn "Vehicle to Vehicle Warning Direction";
BA_ "VNSigAllNodes" SG_ 2151464960 V2VWrngDirctn 1;
BA_ "GenSigSendType" SG_ 2151464960 V2VSrvIndReq 10;
BA_ "SignalType" SG_ 2151464960 V2VSrvIndReq "ENM";
BA_ "SignalLongName" SG_ 2151464960 V2VSrvIndReq "Vehicle To Vehicle Service Indication Request";
BA_ "VNSigAllNodes" SG_ 2151464960 V2VSrvIndReq 1;
BA_ "GenSigSendType" SG_ 2151464960 V2VTLI_TrfLghtMntngDirctn 10;
BA_ "PacketOrder" SG_ 2151464960 V2VTLI_TrfLghtMntngDirctn 5;
BA_ "SignalType" SG_ 2151464960 V2VTLI_TrfLghtMntngDirctn "ENM";
BA_ "SignalLongName" SG_ 2151464960 V2VTLI_TrfLghtMntngDirctn "Vehicle to Vehicle Traffic Light Information : Traffic Light Mounting Direction";
BA_ "VNSigAllNodes" SG_ 2151464960 V2VTLI_TrfLghtMntngDirctn 1;
BA_ "GenSigSendType" SG_ 2151464960 V2VTLI_TrfLghtValDirctn 10;
BA_ "PacketOrder" SG_ 2151464960 V2VTLI_TrfLghtValDirctn 4;
BA_ "SignalType" SG_ 2151464960 V2VTLI_TrfLghtValDirctn "ENM";
BA_ "SignalLongName" SG_ 2151464960 V2VTLI_TrfLghtValDirctn "Vehicle to Vehicle Traffic Light Information : Traffic Light Valid Direction";
BA_ "VNSigAllNodes" SG_ 2151464960 V2VTLI_TrfLghtValDirctn 1;
BA_ "GenSigSendType" SG_ 2151464960 V2VTLI_TrfLghtPhsArivl 10;
BA_ "PacketOrder" SG_ 2151464960 V2VTLI_TrfLghtPhsArivl 3;
BA_ "SignalType" SG_ 2151464960 V2VTLI_TrfLghtPhsArivl "ENM";
BA_ "SignalLongName" SG_ 2151464960 V2VTLI_TrfLghtPhsArivl "Vehicle to Vehicle Traffic Light Information : Traffic Light Phase at Arrival";
BA_ "VNSigAllNodes" SG_ 2151464960 V2VTLI_TrfLghtPhsArivl 1;
BA_ "GenSigSendType" SG_ 2151464960 V2VTLI_TrfLghtActlPhs 10;
BA_ "PacketOrder" SG_ 2151464960 V2VTLI_TrfLghtActlPhs 2;
BA_ "SignalType" SG_ 2151464960 V2VTLI_TrfLghtActlPhs "ENM";
BA_ "SignalLongName" SG_ 2151464960 V2VTLI_TrfLghtActlPhs "Vehicle to Vehicle Traffic Light Information : Traffic Light Actual Phase";
BA_ "VNSigAllNodes" SG_ 2151464960 V2VTLI_TrfLghtActlPhs 1;
BA_ "GenSigDeltaValue" SG_ 2151464960 V2VTLI_TrfLghtTmPhsSw 1;
BA_ "GenSigSendType" SG_ 2151464960 V2VTLI_TrfLghtTmPhsSw 12;
BA_ "PacketOrder" SG_ 2151464960 V2VTLI_TrfLghtTmPhsSw 1;
BA_ "SignalType" SG_ 2151464960 V2VTLI_TrfLghtTmPhsSw "UNM";
BA_ "SignalLongName" SG_ 2151464960 V2VTLI_TrfLghtTmPhsSw "Vehicle to Vehicle Traffic Light Information : Traffic Light Time to Phase Switch";
BA_ "VNSigAllNodes" SG_ 2151464960 V2VTLI_TrfLghtTmPhsSw 1;
BA_ "GenSigDeltaValue" SG_ 2151448576 V2VSyRghtHptStVbRqSN 1;
BA_ "GenSigSendType" SG_ 2151448576 V2VSyRghtHptStVbRqSN 12;
BA_ "SignalType" SG_ 2151448576 V2VSyRghtHptStVbRqSN "UNM";
BA_ "SignalLongName" SG_ 2151448576 V2VSyRghtHptStVbRqSN "Vehicle to Vehicle System Right Haptic Seat Vibration Request Sequence Number";
BA_ "VNSigAllNodes" SG_ 2151448576 V2VSyRghtHptStVbRqSN 1;
BA_ "GenSigDeltaValue" SG_ 2151448576 V2VSyRghtHptStVbRq 1;
BA_ "GenSigSendType" SG_ 2151448576 V2VSyRghtHptStVbRq 12;
BA_ "SignalType" SG_ 2151448576 V2VSyRghtHptStVbRq "UNM";
BA_ "SignalLongName" SG_ 2151448576 V2VSyRghtHptStVbRq "Vehicle to Vehicle System Right Haptic Seat Vibration Request";
BA_ "VNSigAllNodes" SG_ 2151448576 V2VSyRghtHptStVbRq 1;
BA_ "GenSigDeltaValue" SG_ 2151448576 V2VSyLftHptStVbRqSN 1;
BA_ "GenSigSendType" SG_ 2151448576 V2VSyLftHptStVbRqSN 12;
BA_ "SignalType" SG_ 2151448576 V2VSyLftHptStVbRqSN "UNM";
BA_ "SignalLongName" SG_ 2151448576 V2VSyLftHptStVbRqSN "Vehicle to Vehicle System Left Haptic Seat Vibration Request Sequence Number";
BA_ "VNSigAllNodes" SG_ 2151448576 V2VSyLftHptStVbRqSN 1;
BA_ "GenSigDeltaValue" SG_ 2151448576 V2VSyLftHptStVbRq 1;
BA_ "GenSigSendType" SG_ 2151448576 V2VSyLftHptStVbRq 12;
BA_ "SignalType" SG_ 2151448576 V2VSyLftHptStVbRq "UNM";
BA_ "SignalLongName" SG_ 2151448576 V2VSyLftHptStVbRq "Vehicle to Vehicle System Left Haptic Seat Vibration Request";
BA_ "VNSigAllNodes" SG_ 2151448576 V2VSyLftHptStVbRq 1;
BA_ "GenSigDeltaValue" SG_ 2151448576 V2VSysHptStVibRqSN 1;
BA_ "GenSigSendType" SG_ 2151448576 V2VSysHptStVibRqSN 12;
BA_ "SignalType" SG_ 2151448576 V2VSysHptStVibRqSN "UNM";
BA_ "SignalLongName" SG_ 2151448576 V2VSysHptStVibRqSN "Vehicle to Vehicle System Haptic Seat Vibration Request Sequence Number";
BA_ "VNSigAllNodes" SG_ 2151448576 V2VSysHptStVibRqSN 1;
BA_ "GenSigDeltaValue" SG_ 2151448576 V2VSysHptcStVibReq 1;
BA_ "GenSigSendType" SG_ 2151448576 V2VSysHptcStVibReq 12;
BA_ "SignalType" SG_ 2151448576 V2VSysHptcStVibReq "UNM";
BA_ "SignalLongName" SG_ 2151448576 V2VSysHptcStVibReq "Vehicle to Vehicle System Haptic Seat Vibration Request";
BA_ "VNSigAllNodes" SG_ 2151448576 V2VSysHptcStVibReq 1;
BA_ "GenSigSendType" SG_ 2153930752 LnCntrVhlStpd 10;
BA_ "GenSigSendOnInit" SG_ 2153930752 LnCntrVhlStpd 2;
BA_ "SignalType" SG_ 2153930752 LnCntrVhlStpd "BLN";
BA_ "SignalLongName" SG_ 2153930752 LnCntrVhlStpd "Lane Centering Vehicle Stopped";
BA_ "VNSigAllNodes" SG_ 2153930752 LnCntrVhlStpd 1;
BA_ "GenSigSendType" SG_ 2153930752 LnCntrSpchPrmtReq 10;
BA_ "GenSigSendOnInit" SG_ 2153930752 LnCntrSpchPrmtReq 2;
BA_ "SignalType" SG_ 2153930752 LnCntrSpchPrmtReq "ENM";
BA_ "SignalLongName" SG_ 2153930752 LnCntrSpchPrmtReq "Lane Centering Speech Prompt Request";
BA_ "VNSigAllNodes" SG_ 2153930752 LnCntrSpchPrmtReq 1;
BA_ "GenSigSendType" SG_ 2153930752 LCWrnIndReq 10;
BA_ "SignalType" SG_ 2153930752 LCWrnIndReq "ENM";
BA_ "SignalLongName" SG_ 2153930752 LCWrnIndReq "Lane Centering Warning Indication Request";
BA_ "VNSigAllNodes" SG_ 2153930752 LCWrnIndReq 1;
BA_ "GenSigSendType" SG_ 2153930752 LCCDrvrAwrnsIO 10;
BA_ "SignalType" SG_ 2153930752 LCCDrvrAwrnsIO "BLN";
BA_ "SignalLongName" SG_ 2153930752 LCCDrvrAwrnsIO "Lane Centering Driver Awareness Indication On";
BA_ "VNSigAllNodes" SG_ 2153930752 LCCDrvrAwrnsIO 1;
BA_ "GenSigSendType" SG_ 2153930752 LCConvMsgIndreq 10;
BA_ "SignalType" SG_ 2153930752 LCConvMsgIndreq "ENM";
BA_ "SignalLongName" SG_ 2153930752 LCConvMsgIndreq "Lane Centering Convenience Message Indication Request";
BA_ "VNSigAllNodes" SG_ 2153930752 LCConvMsgIndreq 1;
BA_ "GenSigSendType" SG_ 2153930752 LCCIndReq 10;
BA_ "SignalType" SG_ 2153930752 LCCIndReq "ENM";
BA_ "SignalLongName" SG_ 2153930752 LCCIndReq "Lane Centering Control Indication Request";
BA_ "VNSigAllNodes" SG_ 2153930752 LCCIndReq 1;
BA_ "GenSigSendType" SG_ 2153930752 LnCntrNonRspDrvrCnd 10;
BA_ "GenSigSendOnInit" SG_ 2153930752 LnCntrNonRspDrvrCnd 2;
BA_ "SignalType" SG_ 2153930752 LnCntrNonRspDrvrCnd "BLN";
BA_ "SignalLongName" SG_ 2153930752 LnCntrNonRspDrvrCnd "Lane Centering Non Responsive Driver Condition";
BA_ "VNSigAllNodes" SG_ 2153930752 LnCntrNonRspDrvrCnd 1;
BA_ "GenSigDeltaValue" SG_ 2153930752 LnCntrngCtlIcnLoctn 1;
BA_ "GenSigSendType" SG_ 2153930752 LnCntrngCtlIcnLoctn 12;
BA_ "SignalType" SG_ 2153930752 LnCntrngCtlIcnLoctn "SNM";
BA_ "SignalLongName" SG_ 2153930752 LnCntrngCtlIcnLoctn "Lane Centering Control Icon Location";
BA_ "VNSigAllNodes" SG_ 2153930752 LnCntrngCtlIcnLoctn 1;
BA_ "GenSigSendType" SG_ 2153930752 LnCntrEsclnStat 10;
BA_ "GenSigSendOnInit" SG_ 2153930752 LnCntrEsclnStat 2;
BA_ "SignalType" SG_ 2153930752 LnCntrEsclnStat "ENM";
BA_ "SignalLongName" SG_ 2153930752 LnCntrEsclnStat "Lane Centering Escalation Status";
BA_ "VNSigAllNodes" SG_ 2153930752 LnCntrEsclnStat 1;
BA_ "GenSigDeltaValue" SG_ 2153889792 LCArrwBlk5Offst 1;
BA_ "GenSigSendType" SG_ 2153889792 LCArrwBlk5Offst 12;
BA_ "GenSigSendOnInit" SG_ 2153889792 LCArrwBlk5Offst 2;
BA_ "SignalType" SG_ 2153889792 LCArrwBlk5Offst "SNM";
BA_ "SignalLongName" SG_ 2153889792 LCArrwBlk5Offst "Lane Centering Arrow Block 5 Offset";
BA_ "VNSigAllNodes" SG_ 2153889792 LCArrwBlk5Offst 1;
BA_ "GenSigSendType" SG_ 2153889792 LCArrwBlk5Act 10;
BA_ "GenSigSendOnInit" SG_ 2153889792 LCArrwBlk5Act 2;
BA_ "SignalType" SG_ 2153889792 LCArrwBlk5Act "BLN";
BA_ "SignalLongName" SG_ 2153889792 LCArrwBlk5Act "Lane Centering Arrow Block 5 Active";
BA_ "VNSigAllNodes" SG_ 2153889792 LCArrwBlk5Act 1;
BA_ "GenSigDeltaValue" SG_ 2153889792 LCArrwBlk4Offst 1;
BA_ "GenSigSendType" SG_ 2153889792 LCArrwBlk4Offst 12;
BA_ "GenSigSendOnInit" SG_ 2153889792 LCArrwBlk4Offst 2;
BA_ "SignalType" SG_ 2153889792 LCArrwBlk4Offst "SNM";
BA_ "SignalLongName" SG_ 2153889792 LCArrwBlk4Offst "Lane Centering Arrow Block 4 Offset";
BA_ "VNSigAllNodes" SG_ 2153889792 LCArrwBlk4Offst 1;
BA_ "GenSigSendType" SG_ 2153889792 LCArrwBlk4Act 10;
BA_ "GenSigSendOnInit" SG_ 2153889792 LCArrwBlk4Act 2;
BA_ "SignalType" SG_ 2153889792 LCArrwBlk4Act "BLN";
BA_ "SignalLongName" SG_ 2153889792 LCArrwBlk4Act "Lane Centering Arrow Block 4 Active";
BA_ "VNSigAllNodes" SG_ 2153889792 LCArrwBlk4Act 1;
BA_ "GenSigDeltaValue" SG_ 2153889792 LCArrwBlk3Offst 1;
BA_ "GenSigSendType" SG_ 2153889792 LCArrwBlk3Offst 12;
BA_ "GenSigSendOnInit" SG_ 2153889792 LCArrwBlk3Offst 2;
BA_ "SignalType" SG_ 2153889792 LCArrwBlk3Offst "SNM";
BA_ "SignalLongName" SG_ 2153889792 LCArrwBlk3Offst "Lane Centering Arrow Block 3 Offset";
BA_ "VNSigAllNodes" SG_ 2153889792 LCArrwBlk3Offst 1;
BA_ "GenSigSendType" SG_ 2153889792 LCArrwBlk3Act 10;
BA_ "GenSigSendOnInit" SG_ 2153889792 LCArrwBlk3Act 2;
BA_ "SignalType" SG_ 2153889792 LCArrwBlk3Act "BLN";
BA_ "SignalLongName" SG_ 2153889792 LCArrwBlk3Act "Lane Centering Arrow Block 3 Active";
BA_ "VNSigAllNodes" SG_ 2153889792 LCArrwBlk3Act 1;
BA_ "GenSigDeltaValue" SG_ 2153889792 LCArrwBlk2Offst 1;
BA_ "GenSigSendType" SG_ 2153889792 LCArrwBlk2Offst 12;
BA_ "GenSigSendOnInit" SG_ 2153889792 LCArrwBlk2Offst 2;
BA_ "SignalType" SG_ 2153889792 LCArrwBlk2Offst "SNM";
BA_ "SignalLongName" SG_ 2153889792 LCArrwBlk2Offst "Lane Centering Arrow Block 2 Offset";
BA_ "VNSigAllNodes" SG_ 2153889792 LCArrwBlk2Offst 1;
BA_ "GenSigSendType" SG_ 2153889792 LCArrwBlk2Act 10;
BA_ "GenSigSendOnInit" SG_ 2153889792 LCArrwBlk2Act 2;
BA_ "SignalType" SG_ 2153889792 LCArrwBlk2Act "BLN";
BA_ "SignalLongName" SG_ 2153889792 LCArrwBlk2Act "Lane Centering Arrow Block 2 Active";
BA_ "VNSigAllNodes" SG_ 2153889792 LCArrwBlk2Act 1;
BA_ "GenSigSendType" SG_ 2153889792 LCArrwBlk1Act 10;
BA_ "GenSigSendOnInit" SG_ 2153889792 LCArrwBlk1Act 2;
BA_ "SignalType" SG_ 2153889792 LCArrwBlk1Act "BLN";
BA_ "SignalLongName" SG_ 2153889792 LCArrwBlk1Act "Lane Centering Arrow Block 1 Active";
BA_ "VNSigAllNodes" SG_ 2153889792 LCArrwBlk1Act 1;
BA_ "GenSigDeltaValue" SG_ 2153914368 EUSS_TrEgUgScrMxScVal 1;
BA_ "GenSigSendType" SG_ 2153914368 EUSS_TrEgUgScrMxScVal 12;
BA_ "GenSigSendOnInit" SG_ 2153914368 EUSS_TrEgUgScrMxScVal 1;
BA_ "VNSigInfotainment" SG_ 2153914368 EUSS_TrEgUgScrMxScVal 1;
BA_ "SignalType" SG_ 2153914368 EUSS_TrEgUgScrMxScVal "SNM";
BA_ "PacketOrder" SG_ 2153914368 EUSS_TrEgUgScrMxScVal 8;
BA_ "SignalLongName" SG_ 2153914368 EUSS_TrEgUgScrMxScVal "Energy Usage Score Scaling : Terrain Energy Usage Score Maximum Scale Value";
BA_ "VNSigAllNodes" SG_ 2153914368 EUSS_TrEgUgScrMxScVal 1;
BA_ "GenSigDeltaValue" SG_ 2153914368 EUSS_TrEgUgScrMnScVal 1;
BA_ "GenSigSendType" SG_ 2153914368 EUSS_TrEgUgScrMnScVal 12;
BA_ "GenSigSendOnInit" SG_ 2153914368 EUSS_TrEgUgScrMnScVal 1;
BA_ "VNSigInfotainment" SG_ 2153914368 EUSS_TrEgUgScrMnScVal 1;
BA_ "SignalType" SG_ 2153914368 EUSS_TrEgUgScrMnScVal "SNM";
BA_ "PacketOrder" SG_ 2153914368 EUSS_TrEgUgScrMnScVal 7;
BA_ "SignalLongName" SG_ 2153914368 EUSS_TrEgUgScrMnScVal "Energy Usage Score Scaling : Terrain Energy Usage Score Minimum Scale Value";
BA_ "VNSigAllNodes" SG_ 2153914368 EUSS_TrEgUgScrMnScVal 1;
BA_ "GenSigDeltaValue" SG_ 2153914368 EUSS_TcEgUgScrMxScVal 1;
BA_ "GenSigSendType" SG_ 2153914368 EUSS_TcEgUgScrMxScVal 12;
BA_ "GenSigSendOnInit" SG_ 2153914368 EUSS_TcEgUgScrMxScVal 1;
BA_ "VNSigInfotainment" SG_ 2153914368 EUSS_TcEgUgScrMxScVal 1;
BA_ "SignalType" SG_ 2153914368 EUSS_TcEgUgScrMxScVal "SNM";
BA_ "PacketOrder" SG_ 2153914368 EUSS_TcEgUgScrMxScVal 6;
BA_ "SignalLongName" SG_ 2153914368 EUSS_TcEgUgScrMxScVal "Energy Usage Score Scaling : Technique Energy Usage Score Maximum Scale Value";
BA_ "VNSigAllNodes" SG_ 2153914368 EUSS_TcEgUgScrMxScVal 1;
BA_ "GenSigDeltaValue" SG_ 2153914368 EUSS_TcEgUgScrMnScVal 1;
BA_ "GenSigSendType" SG_ 2153914368 EUSS_TcEgUgScrMnScVal 12;
BA_ "GenSigSendOnInit" SG_ 2153914368 EUSS_TcEgUgScrMnScVal 1;
BA_ "VNSigInfotainment" SG_ 2153914368 EUSS_TcEgUgScrMnScVal 1;
BA_ "SignalType" SG_ 2153914368 EUSS_TcEgUgScrMnScVal "SNM";
BA_ "PacketOrder" SG_ 2153914368 EUSS_TcEgUgScrMnScVal 5;
BA_ "SignalLongName" SG_ 2153914368 EUSS_TcEgUgScrMnScVal "Energy Usage Score Scaling : Technique Energy Usage Score Minimum Scale Value";
BA_ "VNSigAllNodes" SG_ 2153914368 EUSS_TcEgUgScrMnScVal 1;
BA_ "GenSigDeltaValue" SG_ 2153914368 EUSS_ITEgUgScrMxScVal 1;
BA_ "GenSigSendType" SG_ 2153914368 EUSS_ITEgUgScrMxScVal 12;
BA_ "GenSigSendOnInit" SG_ 2153914368 EUSS_ITEgUgScrMxScVal 1;
BA_ "VNSigInfotainment" SG_ 2153914368 EUSS_ITEgUgScrMxScVal 1;
BA_ "SignalType" SG_ 2153914368 EUSS_ITEgUgScrMxScVal "SNM";
BA_ "PacketOrder" SG_ 2153914368 EUSS_ITEgUgScrMxScVal 4;
BA_ "SignalLongName" SG_ 2153914368 EUSS_ITEgUgScrMxScVal "Energy Usage Score Scaling : Inside Temp Energy Usage Score Max Scale Value";
BA_ "VNSigAllNodes" SG_ 2153914368 EUSS_ITEgUgScrMxScVal 1;
BA_ "GenSigDeltaValue" SG_ 2153914368 EUSS_ITEgUgScrMnScVal 1;
BA_ "GenSigSendType" SG_ 2153914368 EUSS_ITEgUgScrMnScVal 12;
BA_ "GenSigSendOnInit" SG_ 2153914368 EUSS_ITEgUgScrMnScVal 1;
BA_ "VNSigInfotainment" SG_ 2153914368 EUSS_ITEgUgScrMnScVal 1;
BA_ "SignalType" SG_ 2153914368 EUSS_ITEgUgScrMnScVal "SNM";
BA_ "PacketOrder" SG_ 2153914368 EUSS_ITEgUgScrMnScVal 3;
BA_ "SignalLongName" SG_ 2153914368 EUSS_ITEgUgScrMnScVal "Energy Usage Score Scaling : Inside Temp Energy Usage Score Min Scale Value";
BA_ "VNSigAllNodes" SG_ 2153914368 EUSS_ITEgUgScrMnScVal 1;
BA_ "GenSigDeltaValue" SG_ 2153914368 EUSS_OTEgUgScrMxScVal 1;
BA_ "GenSigSendType" SG_ 2153914368 EUSS_OTEgUgScrMxScVal 12;
BA_ "GenSigSendOnInit" SG_ 2153914368 EUSS_OTEgUgScrMxScVal 1;
BA_ "VNSigInfotainment" SG_ 2153914368 EUSS_OTEgUgScrMxScVal 1;
BA_ "SignalType" SG_ 2153914368 EUSS_OTEgUgScrMxScVal "SNM";
BA_ "PacketOrder" SG_ 2153914368 EUSS_OTEgUgScrMxScVal 2;
BA_ "SignalLongName" SG_ 2153914368 EUSS_OTEgUgScrMxScVal "Energy Usage Score Scaling : Outside Temp Energy Usage Score Max Scale Value";
BA_ "VNSigAllNodes" SG_ 2153914368 EUSS_OTEgUgScrMxScVal 1;
BA_ "GenSigDeltaValue" SG_ 2153914368 EUSS_OTEgUgScrMnScVal 1;
BA_ "GenSigSendType" SG_ 2153914368 EUSS_OTEgUgScrMnScVal 12;
BA_ "GenSigSendOnInit" SG_ 2153914368 EUSS_OTEgUgScrMnScVal 1;
BA_ "VNSigInfotainment" SG_ 2153914368 EUSS_OTEgUgScrMnScVal 1;
BA_ "SignalType" SG_ 2153914368 EUSS_OTEgUgScrMnScVal "SNM";
BA_ "PacketOrder" SG_ 2153914368 EUSS_OTEgUgScrMnScVal 1;
BA_ "SignalLongName" SG_ 2153914368 EUSS_OTEgUgScrMnScVal "Energy Usage Score Scaling : Outside Temp Energy Usage Score Min Scale Value";
BA_ "VNSigAllNodes" SG_ 2153914368 EUSS_OTEgUgScrMnScVal 1;
BA_ "GenSigSendType" SG_ 2151882752 PTOTpStpSpdCsStReq 10;
BA_ "VNSigInfotainment" SG_ 2151882752 PTOTpStpSpdCsStReq 1;
BA_ "SignalType" SG_ 2151882752 PTOTpStpSpdCsStReq "ENM";
BA_ "SignalLongName" SG_ 2151882752 PTOTpStpSpdCsStReq "Power Take Off Tap Step Speed Customization Setting Request";
BA_ "VNSigAllNodes" SG_ 2151882752 PTOTpStpSpdCsStReq 1;
BA_ "GenSigSendType" SG_ 2151882752 PTOStdbySpdCsStReq 10;
BA_ "VNSigInfotainment" SG_ 2151882752 PTOStdbySpdCsStReq 1;
BA_ "SignalType" SG_ 2151882752 PTOStdbySpdCsStReq "ENM";
BA_ "SignalLongName" SG_ 2151882752 PTOStdbySpdCsStReq "Power Take Off Standby Speed Customization Setting Request";
BA_ "VNSigAllNodes" SG_ 2151882752 PTOStdbySpdCsStReq 1;
BA_ "GenSigSendType" SG_ 2151882752 PTOEngRnTmrCsStRq 10;
BA_ "VNSigInfotainment" SG_ 2151882752 PTOEngRnTmrCsStRq 1;
BA_ "SignalType" SG_ 2151882752 PTOEngRnTmrCsStRq "ENM";
BA_ "SignalLongName" SG_ 2151882752 PTOEngRnTmrCsStRq "Power Take Off Engine Run Timer Customization Setting Request";
BA_ "VNSigAllNodes" SG_ 2151882752 PTOEngRnTmrCsStRq 1;
BA_ "GenSigSendType" SG_ 2151882752 PTOSet2SpdCsStReq 10;
BA_ "VNSigInfotainment" SG_ 2151882752 PTOSet2SpdCsStReq 1;
BA_ "SignalType" SG_ 2151882752 PTOSet2SpdCsStReq "ENM";
BA_ "SignalLongName" SG_ 2151882752 PTOSet2SpdCsStReq "Power Take Off Set 2 Speed Customization Setting Request";
BA_ "VNSigAllNodes" SG_ 2151882752 PTOSet2SpdCsStReq 1;
BA_ "GenSigSendType" SG_ 2151882752 PTOSet1SpdCsStReq 10;
BA_ "VNSigInfotainment" SG_ 2151882752 PTOSet1SpdCsStReq 1;
BA_ "SignalType" SG_ 2151882752 PTOSet1SpdCsStReq "ENM";
BA_ "SignalLongName" SG_ 2151882752 PTOSet1SpdCsStReq "Power Take Off Set 1 Speed Customization Setting Request";
BA_ "VNSigAllNodes" SG_ 2151882752 PTOSet1SpdCsStReq 1;
BA_ "SignalType" SG_ 2151899136 PTOAccelUpnBrkRelIO "BLN";
BA_ "SignalLongName" SG_ 2151899136 PTOAccelUpnBrkRelIO "Power Take Off Acceleration Upon Brake Release Indication On";
BA_ "VNSigAllNodes" SG_ 2151899136 PTOAccelUpnBrkRelIO 1;
BA_ "SignalType" SG_ 2151899136 PTOEngUpnBrkRelIO "BLN";
BA_ "SignalLongName" SG_ 2151899136 PTOEngUpnBrkRelIO "Power Take Off Engage Upon Brake Release Indication On";
BA_ "VNSigAllNodes" SG_ 2151899136 PTOEngUpnBrkRelIO 1;
BA_ "SignalType" SG_ 2151899136 PTOManTransInGrIO "BLN";
BA_ "SignalLongName" SG_ 2151899136 PTOManTransInGrIO "Power Take Off Manual Transmission In Gear Indication On";
BA_ "VNSigAllNodes" SG_ 2151899136 PTOManTransInGrIO 1;
BA_ "SignalType" SG_ 2151899136 PTOServIndOn "BLN";
BA_ "SignalLongName" SG_ 2151899136 PTOServIndOn "Power Take Off Service Indication On";
BA_ "VNSigAllNodes" SG_ 2151899136 PTOServIndOn 1;
BA_ "SignalType" SG_ 2151899136 PTOVDM "ENM";
BA_ "SignalLongName" SG_ 2151899136 PTOVDM "Power Take Off Virtual Device Mask";
BA_ "VNSigAllNodes" SG_ 2151899136 PTOVDM 1;
BA_ "SignalType" SG_ 2151899136 PTOVDA "ENM";
BA_ "SignalLongName" SG_ 2151899136 PTOVDA "Power Take Off Virtual Device Availability";
BA_ "GenSigStartValue" SG_ 2151899136 PTOVDA 1;
BA_ "VNSigAllNodes" SG_ 2151899136 PTOVDA 1;
BA_ "SignalType" SG_ 2151899136 PTOTransInGearIO "BLN";
BA_ "SignalLongName" SG_ 2151899136 PTOTransInGearIO "Power Take Off Transmission In Gear Indication On";
BA_ "VNSigAllNodes" SG_ 2151899136 PTOTransInGearIO 1;
BA_ "VNSigInfotainment" SG_ 2151899136 PTOTpStpSpdCsStAvl 1;
BA_ "SignalType" SG_ 2151899136 PTOTpStpSpdCsStAvl "BLN";
BA_ "SignalLongName" SG_ 2151899136 PTOTpStpSpdCsStAvl "Power Take Off Tap Step Speed Customization Setting Available";
BA_ "VNSigAllNodes" SG_ 2151899136 PTOTpStpSpdCsStAvl 1;
BA_ "VNSigInfotainment" SG_ 2151899136 PTOTpStSpdCsCrStVal 1;
BA_ "SignalType" SG_ 2151899136 PTOTpStSpdCsCrStVal "ENM";
BA_ "SignalLongName" SG_ 2151899136 PTOTpStSpdCsCrStVal "Power Take Off Tap Step Speed Customization Current Setting Value";
BA_ "VNSigAllNodes" SG_ 2151899136 PTOTpStSpdCsCrStVal 1;
BA_ "VNSigInfotainment" SG_ 2151899136 PTOStdbySpdCsStAvl 1;
BA_ "SignalType" SG_ 2151899136 PTOStdbySpdCsStAvl "BLN";
BA_ "SignalLongName" SG_ 2151899136 PTOStdbySpdCsStAvl "Power Take Off Standby Speed Customization Setting Available";
BA_ "VNSigAllNodes" SG_ 2151899136 PTOStdbySpdCsStAvl 1;
BA_ "VNSigInfotainment" SG_ 2151899136 PTOStdbSpdCsCrStVal 1;
BA_ "SignalType" SG_ 2151899136 PTOStdbSpdCsCrStVal "ENM";
BA_ "SignalLongName" SG_ 2151899136 PTOStdbSpdCsCrStVal "Power Take Off Standby Speed Customization Current Setting Value";
BA_ "VNSigAllNodes" SG_ 2151899136 PTOStdbSpdCsCrStVal 1;
BA_ "SignalType" SG_ 2151899136 PTOSetPrkBrkIO "BLN";
BA_ "SignalLongName" SG_ 2151899136 PTOSetPrkBrkIO "Power Take Off Set Park Brake Indication On";
BA_ "VNSigAllNodes" SG_ 2151899136 PTOSetPrkBrkIO 1;
BA_ "VNSigInfotainment" SG_ 2151899136 PTOSet2SpdCsStAvl 1;
BA_ "SignalType" SG_ 2151899136 PTOSet2SpdCsStAvl "BLN";
BA_ "SignalLongName" SG_ 2151899136 PTOSet2SpdCsStAvl "Power Take Off Set 2 Speed Customization Setting Available";
BA_ "VNSigAllNodes" SG_ 2151899136 PTOSet2SpdCsStAvl 1;
BA_ "VNSigInfotainment" SG_ 2151899136 PTOSet2SpdCsCrStVal 1;
BA_ "SignalType" SG_ 2151899136 PTOSet2SpdCsCrStVal "ENM";
BA_ "SignalLongName" SG_ 2151899136 PTOSet2SpdCsCrStVal "Power Take Off Set 2 Speed Customization Current Setting Value";
BA_ "VNSigAllNodes" SG_ 2151899136 PTOSet2SpdCsCrStVal 1;
BA_ "VNSigInfotainment" SG_ 2151899136 PTOSet1SpdCsStAvl 1;
BA_ "SignalType" SG_ 2151899136 PTOSet1SpdCsStAvl "BLN";
BA_ "SignalLongName" SG_ 2151899136 PTOSet1SpdCsStAvl "Power Take Off Set 1 Speed Customization Setting Available";
BA_ "VNSigAllNodes" SG_ 2151899136 PTOSet1SpdCsStAvl 1;
BA_ "VNSigInfotainment" SG_ 2151899136 PTOSet1SpdCsCrStVal 1;
BA_ "SignalType" SG_ 2151899136 PTOSet1SpdCsCrStVal "ENM";
BA_ "SignalLongName" SG_ 2151899136 PTOSet1SpdCsCrStVal "Power Take Off Set 1 Speed Customization Current Setting Value";
BA_ "VNSigAllNodes" SG_ 2151899136 PTOSet1SpdCsCrStVal 1;
BA_ "SignalType" SG_ 2151899136 PTORelCltPedIO "BLN";
BA_ "SignalLongName" SG_ 2151899136 PTORelCltPedIO "Power Take Off Release Clutch Pedal Indication On";
BA_ "VNSigAllNodes" SG_ 2151899136 PTORelCltPedIO 1;
BA_ "SignalType" SG_ 2151899136 PTORelBrkPedIO "BLN";
BA_ "SignalLongName" SG_ 2151899136 PTORelBrkPedIO "Power Take Off Release Brake Pedal Indication On";
BA_ "VNSigAllNodes" SG_ 2151899136 PTORelBrkPedIO 1;
BA_ "SignalType" SG_ 2151899136 PTORelAccPedIO "BLN";
BA_ "SignalLongName" SG_ 2151899136 PTORelAccPedIO "Power Take Off Release Accelerator Pedal Indication On";
BA_ "VNSigAllNodes" SG_ 2151899136 PTORelAccPedIO 1;
BA_ "SignalType" SG_ 2151899136 PTORedEngSpdIO "BLN";
BA_ "SignalLongName" SG_ 2151899136 PTORedEngSpdIO "Power Take Off Reduce Engine Speed Indication On";
BA_ "VNSigAllNodes" SG_ 2151899136 PTORedEngSpdIO 1;
BA_ "SignalType" SG_ 2151899136 PTOPrsRelCltPedIO "BLN";
BA_ "SignalLongName" SG_ 2151899136 PTOPrsRelCltPedIO "Power Take Off Press and Release Clutch Pedal Indication On";
BA_ "VNSigAllNodes" SG_ 2151899136 PTOPrsRelCltPedIO 1;
BA_ "SignalType" SG_ 2151899136 PTOPrsRelBrkPedIO "BLN";
BA_ "SignalLongName" SG_ 2151899136 PTOPrsRelBrkPedIO "Power Take Off Press and Release Brake Pedal Indication On";
BA_ "VNSigAllNodes" SG_ 2151899136 PTOPrsRelBrkPedIO 1;
BA_ "VNSigInfotainment" SG_ 2151899136 PTOEngRnTmrCsStAvl 1;
BA_ "SignalType" SG_ 2151899136 PTOEngRnTmrCsStAvl "BLN";
BA_ "SignalLongName" SG_ 2151899136 PTOEngRnTmrCsStAvl "Power Take Off Engine Run Timer Customization Setting Available";
BA_ "VNSigAllNodes" SG_ 2151899136 PTOEngRnTmrCsStAvl 1;
BA_ "VNSigInfotainment" SG_ 2151899136 PTOEnRnTmCsCrStVal 1;
BA_ "SignalType" SG_ 2151899136 PTOEnRnTmCsCrStVal "ENM";
BA_ "SignalLongName" SG_ 2151899136 PTOEnRnTmCsCrStVal "Power Take Off Engine Run Timer Customization Current Setting Value";
BA_ "VNSigAllNodes" SG_ 2151899136 PTOEnRnTmCsCrStVal 1;
BA_ "SignalType" SG_ 2151899136 PTOEngmntStatInd "ENM";
BA_ "SignalLongName" SG_ 2151899136 PTOEngmntStatInd "Power Take Off Engagement Status Indication";
BA_ "VNSigAllNodes" SG_ 2151899136 PTOEngmntStatInd 1;
BA_ "SignalType" SG_ 2151899136 PTODisengCrsCntlIO "BLN";
BA_ "SignalLongName" SG_ 2151899136 PTODisengCrsCntlIO "Power Take Off Disengage Cruise Control Indication On";
BA_ "VNSigAllNodes" SG_ 2151899136 PTODisengCrsCntlIO 1;
BA_ "GenSigDeltaValue" SG_ 2150580224 CstNonUsbSOCDspLvl 1;
BA_ "GenSigSendType" SG_ 2150580224 CstNonUsbSOCDspLvl 12;
BA_ "GenSigSendOnInit" SG_ 2150580224 CstNonUsbSOCDspLvl 1;
BA_ "SignalType" SG_ 2150580224 CstNonUsbSOCDspLvl "UNM";
BA_ "SignalLongName" SG_ 2150580224 CstNonUsbSOCDspLvl "Customer Non Usable State of Charge Display Level";
BA_ "VNSigAllNodes" SG_ 2150580224 CstNonUsbSOCDspLvl 1;
BA_ "GenSigSendType" SG_ 2150580224 CstmrNonUsblSOCV 10;
BA_ "GenSigSendOnInit" SG_ 2150580224 CstmrNonUsblSOCV 1;
BA_ "SignalType" SG_ 2150580224 CstmrNonUsblSOCV "ENM";
BA_ "SignalLongName" SG_ 2150580224 CstmrNonUsblSOCV "Customer Non Usable State of Charge Validity";
BA_ "VNSigAllNodes" SG_ 2150580224 CstmrNonUsblSOCV 1;
BA_ "GenSigDeltaValue" SG_ 2150580224 CstmrNonUsblSOC 1;
BA_ "GenSigSendType" SG_ 2150580224 CstmrNonUsblSOC 12;
BA_ "GenSigSendOnInit" SG_ 2150580224 CstmrNonUsblSOC 1;
BA_ "SignalType" SG_ 2150580224 CstmrNonUsblSOC "UNM";
BA_ "SignalLongName" SG_ 2150580224 CstmrNonUsblSOC "Customer Non Usable State of Charge";
BA_ "VNSigAllNodes" SG_ 2150580224 CstmrNonUsblSOC 1;
BA_ "GenSigDeltaValue" SG_ 2150580224 PrpDspTtlPwrLvlPct 1;
BA_ "GenSigSendType" SG_ 2150580224 PrpDspTtlPwrLvlPct 12;
BA_ "GenSigSendOnInit" SG_ 2150580224 PrpDspTtlPwrLvlPct 1;
BA_ "VNSigInfotainment" SG_ 2150580224 PrpDspTtlPwrLvlPct 1;
BA_ "SignalType" SG_ 2150580224 PrpDspTtlPwrLvlPct "SNM";
BA_ "SignalLongName" SG_ 2150580224 PrpDspTtlPwrLvlPct "Propulsion Display Total Power Level Percent";
BA_ "VNSigAllNodes" SG_ 2150580224 PrpDspTtlPwrLvlPct 1;
BA_ "SignalType" SG_ 2020 DgnInf "UNM";
BA_ "SignalLongName" SG_ 2020 DgnInf "Diagnostic Information";
BA_ "VNSigDiagnostic" SG_ 2020 DgnInf 1;
BA_ "VNSigAllNodes" SG_ 2020 DgnInf 1;
BA_ "GenSigSendType" SG_ 2151735296 RtSdDetSysServDsbld 10;
BA_ "SignalType" SG_ 2151735296 RtSdDetSysServDsbld "BLN";
BA_ "SignalLongName" SG_ 2151735296 RtSdDetSysServDsbld "Right Side Detection System Service Disabled";
BA_ "VNSigAllNodes" SG_ 2151735296 RtSdDetSysServDsbld 1;
BA_ "GenSigSendType" SG_ 2151735296 RtSdDetSysTmpDsbld 10;
BA_ "SignalType" SG_ 2151735296 RtSdDetSysTmpDsbld "BLN";
BA_ "SignalLongName" SG_ 2151735296 RtSdDetSysTmpDsbld "Right Side Detection System Temp Disabled";
BA_ "VNSigAllNodes" SG_ 2151735296 RtSdDetSysTmpDsbld 1;
BA_ "GenSigSendType" SG_ 2151735296 RtLnChgAlrtEnbld 10;
BA_ "SignalType" SG_ 2151735296 RtLnChgAlrtEnbld "BLN";
BA_ "SignalLongName" SG_ 2151735296 RtLnChgAlrtEnbld "Right Lane Change Alert Enabled";
BA_ "VNSigAllNodes" SG_ 2151735296 RtLnChgAlrtEnbld 1;
BA_ "GenSigSendType" SG_ 2151735296 RtSBZAlrtEnbld 10;
BA_ "SignalType" SG_ 2151735296 RtSBZAlrtEnbld "BLN";
BA_ "SignalLongName" SG_ 2151735296 RtSBZAlrtEnbld "Right Side Blind Zone Alert Enabled";
BA_ "VNSigAllNodes" SG_ 2151735296 RtSBZAlrtEnbld 1;
BA_ "GenSigSendType" SG_ 2151735296 RtRrCrsTrfcAlrtEnbld 10;
BA_ "SignalType" SG_ 2151735296 RtRrCrsTrfcAlrtEnbld "BLN";
BA_ "SignalLongName" SG_ 2151735296 RtRrCrsTrfcAlrtEnbld "Right Rear Cross Traffic Alert Enabled";
BA_ "VNSigAllNodes" SG_ 2151735296 RtRrCrsTrfcAlrtEnbld 1;
BA_ "GenSigSendType" SG_ 2151735296 LnChgAlrtOffIndOn 10;
BA_ "SignalType" SG_ 2151735296 LnChgAlrtOffIndOn "BLN";
BA_ "SignalLongName" SG_ 2151735296 LnChgAlrtOffIndOn "Lane Change Alert Off Indication On";
BA_ "VNSigAllNodes" SG_ 2151735296 LnChgAlrtOffIndOn 1;
BA_ "GenSigSendType" SG_ 2151735296 RrCrsTrfcAlrtOffIO 10;
BA_ "SignalType" SG_ 2151735296 RrCrsTrfcAlrtOffIO "BLN";
BA_ "SignalLongName" SG_ 2151735296 RrCrsTrfcAlrtOffIO "Rear Cross Traffic Alert Off Indication On";
BA_ "VNSigAllNodes" SG_ 2151735296 RrCrsTrfcAlrtOffIO 1;
BA_ "GenSigSendType" SG_ 2151792640 RCTARIC_Indctr1Act 10;
BA_ "SignalType" SG_ 2151792640 RCTARIC_Indctr1Act "BLN";
BA_ "PacketOrder" SG_ 2151792640 RCTARIC_Indctr1Act 1;
BA_ "SignalLongName" SG_ 2151792640 RCTARIC_Indctr1Act "Rear Cross Traffic Alert Right Indication Control : Indicator 1 Active";
BA_ "VNSigAllNodes" SG_ 2151792640 RCTARIC_Indctr1Act 1;
BA_ "GenSigSendType" SG_ 2151792640 RCTARIC_IndReq 10;
BA_ "SignalType" SG_ 2151792640 RCTARIC_IndReq "ENM";
BA_ "PacketOrder" SG_ 2151792640 RCTARIC_IndReq 2;
BA_ "SignalLongName" SG_ 2151792640 RCTARIC_IndReq "Rear Cross Traffic Alert Right Indication Control : Indication Request";
BA_ "VNSigAllNodes" SG_ 2151792640 RCTARIC_IndReq 1;
BA_ "GenSigDeltaValue" SG_ 2151792640 RrCTfcRHptcStRqSqN 1;
BA_ "GenSigSendType" SG_ 2151792640 RrCTfcRHptcStRqSqN 12;
BA_ "SignalType" SG_ 2151792640 RrCTfcRHptcStRqSqN "UNM";
BA_ "SignalLongName" SG_ 2151792640 RrCTfcRHptcStRqSqN "Rear Cross Traffic Alert Right Haptic Seat Request Sequence Number";
BA_ "VNSigAllNodes" SG_ 2151792640 RrCTfcRHptcStRqSqN 1;
BA_ "GenSigDeltaValue" SG_ 2151792640 RrCTfcRHptcStReq 1;
BA_ "GenSigSendType" SG_ 2151792640 RrCTfcRHptcStReq 12;
BA_ "SignalType" SG_ 2151792640 RrCTfcRHptcStReq "UNM";
BA_ "SignalLongName" SG_ 2151792640 RrCTfcRHptcStReq "Rear Cross Traffic Alert Right Haptic Seat Request";
BA_ "VNSigAllNodes" SG_ 2151792640 RrCTfcRHptcStReq 1;
BA_ "GenSigSendType" SG_ 2149826560 SpdSignUltdDetdIO 10;
BA_ "GenSigSendOnInit" SG_ 2149826560 SpdSignUltdDetdIO 1;
BA_ "SignalType" SG_ 2149826560 SpdSignUltdDetdIO "BLN";
BA_ "SignalLongName" SG_ 2149826560 SpdSignUltdDetdIO "Speed Sign Unlimited Detected Indication On";
BA_ "VNSigAllNodes" SG_ 2149826560 SpdSignUltdDetdIO 1;
BA_ "GenSigSendType" SG_ 2149826560 TrfcSgnMmryIcePosIO 10;
BA_ "SignalType" SG_ 2149826560 TrfcSgnMmryIcePosIO "BLN";
BA_ "SignalLongName" SG_ 2149826560 TrfcSgnMmryIcePosIO "Traffic Sign Memory Ice Possible Indication On";
BA_ "VNSigAllNodes" SG_ 2149826560 TrfcSgnMmryIcePosIO 1;
BA_ "GenSigSendType" SG_ 2149826560 SpdLmtVsnFsdSpdUnt 10;
BA_ "SignalType" SG_ 2149826560 SpdLmtVsnFsdSpdUnt "ENM";
BA_ "SignalLongName" SG_ 2149826560 SpdLmtVsnFsdSpdUnt "Speed Limit Vision Fused Speed Unit";
BA_ "VNSigAllNodes" SG_ 2149826560 SpdLmtVsnFsdSpdUnt 1;
BA_ "GenSigSendType" SG_ 2149826560 SpdLmtVnFsSpdNwDet 10;
BA_ "SignalType" SG_ 2149826560 SpdLmtVnFsSpdNwDet "BLN";
BA_ "SignalLongName" SG_ 2149826560 SpdLmtVnFsSpdNwDet "Speed Limit Vision Fused Speed New Detected";
BA_ "VNSigAllNodes" SG_ 2149826560 SpdLmtVnFsSpdNwDet 1;
BA_ "GenSigSendType" SG_ 2149826560 SpdLmtVsnFsdSpdM 10;
BA_ "SignalType" SG_ 2149826560 SpdLmtVsnFsdSpdM "ENM";
BA_ "SignalLongName" SG_ 2149826560 SpdLmtVsnFsdSpdM "Speed Limit Vision Fused Speed Mask";
BA_ "VNSigAllNodes" SG_ 2149826560 SpdLmtVsnFsdSpdM 1;
BA_ "GenSigDeltaValue" SG_ 2149826560 SpdLmtVsnFsdSpd 1;
BA_ "GenSigSendType" SG_ 2149826560 SpdLmtVsnFsdSpd 12;
BA_ "SignalType" SG_ 2149826560 SpdLmtVsnFsdSpd "UNM";
BA_ "SignalLongName" SG_ 2149826560 SpdLmtVsnFsdSpd "Speed Limit Vision Fused Speed";
BA_ "VNSigAllNodes" SG_ 2149826560 SpdLmtVsnFsdSpd 1;
BA_ "GenSigSendType" SG_ 2149826560 FOAI_VehAhdIndRq11E 10;
BA_ "SignalType" SG_ 2149826560 FOAI_VehAhdIndRq11E "ENM";
BA_ "PacketOrder" SG_ 2149826560 FOAI_VehAhdIndRq11E 3;
BA_ "SignalLongName" SG_ 2149826560 FOAI_VehAhdIndRq11E "Forward Object Alert Indications : Vehicle Ahead Indication Request";
BA_ "VNSigAllNodes" SG_ 2149826560 FOAI_VehAhdIndRq11E 1;
BA_ "GenSigSendType" SG_ 2149826560 FOAI_AlrtWrnIndRq11E 10;
BA_ "SignalType" SG_ 2149826560 FOAI_AlrtWrnIndRq11E "ENM";
BA_ "PacketOrder" SG_ 2149826560 FOAI_AlrtWrnIndRq11E 2;
BA_ "SignalLongName" SG_ 2149826560 FOAI_AlrtWrnIndRq11E "Forward Object Alert Indications : Alert Warning Indication Request";
BA_ "VNSigAllNodes" SG_ 2149826560 FOAI_AlrtWrnIndRq11E 1;
BA_ "GenSigSendType" SG_ 2149826560 FOAI_AlrtChmIhbRq11E 10;
BA_ "SignalType" SG_ 2149826560 FOAI_AlrtChmIhbRq11E "ENM";
BA_ "PacketOrder" SG_ 2149826560 FOAI_AlrtChmIhbRq11E 1;
BA_ "SignalLongName" SG_ 2149826560 FOAI_AlrtChmIhbRq11E "Forward Object Alert Indications : Alert Warning Chime Inhibit Request";
BA_ "VNSigAllNodes" SG_ 2149826560 FOAI_AlrtChmIhbRq11E 1;
BA_ "GenSigSendType" SG_ 2149826560 FwdClnAlrtOffIO11E 10;
BA_ "SignalType" SG_ 2149826560 FwdClnAlrtOffIO11E "BLN";
BA_ "SignalLongName" SG_ 2149826560 FwdClnAlrtOffIO11E "Forward Collision Alert Off Indication On";
BA_ "VNSigAllNodes" SG_ 2149826560 FwdClnAlrtOffIO11E 1;
BA_ "GenSigSendType" SG_ 2149826560 FwdClnAlrtPr11E 10;
BA_ "GenSigSendOnInit" SG_ 2149826560 FwdClnAlrtPr11E 1;
BA_ "SignalType" SG_ 2149826560 FwdClnAlrtPr11E "BLN";
BA_ "SignalLongName" SG_ 2149826560 FwdClnAlrtPr11E "Forward Collision Alert Present";
BA_ "VNSigAllNodes" SG_ 2149826560 FwdClnAlrtPr11E 1;
BA_ "GenSigSendType" SG_ 2149826560 FCABrkPrflReq 10;
BA_ "SignalType" SG_ 2149826560 FCABrkPrflReq "BLN";
BA_ "SignalLongName" SG_ 2149826560 FCABrkPrflReq "Forward Collision Alert Brake Prefill Request";
BA_ "VNSigAllNodes" SG_ 2149826560 FCABrkPrflReq 1;
BA_ "GenSigSendType" SG_ 2149826560 FCAHdwyStngIO 10;
BA_ "SignalType" SG_ 2149826560 FCAHdwyStngIO "BLN";
BA_ "SignalLongName" SG_ 2149826560 FCAHdwyStngIO "Forward Collision Alert Headway Setting Indication On";
BA_ "VNSigAllNodes" SG_ 2149826560 FCAHdwyStngIO 1;
BA_ "GenSigSendType" SG_ 2149826560 FCAGpStng 10;
BA_ "SignalType" SG_ 2149826560 FCAGpStng "ENM";
BA_ "SignalLongName" SG_ 2149826560 FCAGpStng "Forward Collision Alert Gap Setting";
BA_ "VNSigAllNodes" SG_ 2149826560 FCAGpStng 1;
BA_ "GenSigSendType" SG_ 2149826560 FCACrusCtrlCnclReqd 10;
BA_ "SignalType" SG_ 2149826560 FCACrusCtrlCnclReqd "BLN";
BA_ "SignalLongName" SG_ 2149826560 FCACrusCtrlCnclReqd "Forward Collision Alert Cruise Control Cancel Requested";
BA_ "VNSigAllNodes" SG_ 2149826560 FCACrusCtrlCnclReqd 1;
BA_ "GenSigSendType" SG_ 2149957632 PrkAstRrObjSnsngRqAct 10;
BA_ "GenSigSendOnInit" SG_ 2149957632 PrkAstRrObjSnsngRqAct 2;
BA_ "SignalType" SG_ 2149957632 PrkAstRrObjSnsngRqAct "BLN";
BA_ "SignalLongName" SG_ 2149957632 PrkAstRrObjSnsngRqAct "Park Assistance Rear Object Sensing Request Active";
BA_ "VNSigAllNodes" SG_ 2149957632 PrkAstRrObjSnsngRqAct 1;
BA_ "GenSigSendType" SG_ 2149957632 PrkAstOprtrDsrdStat 10;
BA_ "GenSigSendOnInit" SG_ 2149957632 PrkAstOprtrDsrdStat 2;
BA_ "SignalType" SG_ 2149957632 PrkAstOprtrDsrdStat "ENM";
BA_ "SignalLongName" SG_ 2149957632 PrkAstOprtrDsrdStat "Park Assistance Operator Desired Status";
BA_ "VNSigAllNodes" SG_ 2149957632 PrkAstOprtrDsrdStat 1;
BA_ "GenSigSendType" SG_ 2149957632 PrkAstInhbtReq 10;
BA_ "GenSigSendOnInit" SG_ 2149957632 PrkAstInhbtReq 2;
BA_ "SignalType" SG_ 2149957632 PrkAstInhbtReq "BLN";
BA_ "SignalLongName" SG_ 2149957632 PrkAstInhbtReq "Park Assistance Inhibit Request";
BA_ "VNSigAllNodes" SG_ 2149957632 PrkAstInhbtReq 1;
BA_ "GenSigSendType" SG_ 2149957632 ClsnMtgtnInhbtd 10;
BA_ "GenSigSendOnInit" SG_ 2149957632 ClsnMtgtnInhbtd 2;
BA_ "SignalType" SG_ 2149957632 ClsnMtgtnInhbtd "BLN";
BA_ "SignalLongName" SG_ 2149957632 ClsnMtgtnInhbtd "Collision Mitigation Inhibited";
BA_ "VNSigAllNodes" SG_ 2149957632 ClsnMtgtnInhbtd 1;
BA_ "GenSigSendType" SG_ 2149941248 PrkAstRrObjSnsngAct 10;
BA_ "GenSigSendOnInit" SG_ 2149941248 PrkAstRrObjSnsngAct 2;
BA_ "SignalType" SG_ 2149941248 PrkAstRrObjSnsngAct "BLN";
BA_ "SignalLongName" SG_ 2149941248 PrkAstRrObjSnsngAct "Park Assistance Rear Object Sensing Active";
BA_ "VNSigAllNodes" SG_ 2149941248 PrkAstRrObjSnsngAct 1;
BA_ "GenSigSendType" SG_ 2149941248 PrkAstRrSysStatUnfltd 10;
BA_ "GenSigSendOnInit" SG_ 2149941248 PrkAstRrSysStatUnfltd 2;
BA_ "SignalType" SG_ 2149941248 PrkAstRrSysStatUnfltd "ENM";
BA_ "SignalLongName" SG_ 2149941248 PrkAstRrSysStatUnfltd "Parking Assistance Rear System Status Unfiltered";
BA_ "VNSigAllNodes" SG_ 2149941248 PrkAstRrSysStatUnfltd 1;
BA_ "GenSigDeltaValue" SG_ 2149941248 PrkAstRrExtdDstUnfltd 1;
BA_ "GenSigSendType" SG_ 2149941248 PrkAstRrExtdDstUnfltd 12;
BA_ "GenSigSendOnInit" SG_ 2149941248 PrkAstRrExtdDstUnfltd 2;
BA_ "SignalType" SG_ 2149941248 PrkAstRrExtdDstUnfltd "UNM";
BA_ "SignalLongName" SG_ 2149941248 PrkAstRrExtdDstUnfltd "Parking Assistance Rear Extended Distance Unfiltered";
BA_ "VNSigAllNodes" SG_ 2149941248 PrkAstRrExtdDstUnfltd 1;
BA_ "GenSigSendType" SG_ 2149941248 PrkAstFntnSnsDstrbdIO 10;
BA_ "GenSigSendOnInit" SG_ 2149941248 PrkAstFntnSnsDstrbdIO 2;
BA_ "SignalType" SG_ 2149941248 PrkAstFntnSnsDstrbdIO "BLN";
BA_ "SignalLongName" SG_ 2149941248 PrkAstFntnSnsDstrbdIO "Parking Assistance Function Sensors Disturbed Indication On";
BA_ "VNSigAllNodes" SG_ 2149941248 PrkAstFntnSnsDstrbdIO 1;
BA_ "GenSigSendType" SG_ 2149941248 PrkAstFntnSnrsBlkd 10;
BA_ "GenSigSendOnInit" SG_ 2149941248 PrkAstFntnSnrsBlkd 2;
BA_ "SignalType" SG_ 2149941248 PrkAstFntnSnrsBlkd "BLN";
BA_ "SignalLongName" SG_ 2149941248 PrkAstFntnSnrsBlkd "Parking Assistance Function Sensors Blocked";
BA_ "VNSigAllNodes" SG_ 2149941248 PrkAstFntnSnrsBlkd 1;
BA_ "GenSigSendType" SG_ 2149941248 PrkAstFntnFld 10;
BA_ "GenSigSendOnInit" SG_ 2149941248 PrkAstFntnFld 2;
BA_ "SignalType" SG_ 2149941248 PrkAstFntnFld "BLN";
BA_ "SignalLongName" SG_ 2149941248 PrkAstFntnFld "Parking Assistance Function Failed";
BA_ "VNSigAllNodes" SG_ 2149941248 PrkAstFntnFld 1;
BA_ "GenSigSendType" SG_ 2149941248 PrkAstFntnDsbldIO 10;
BA_ "GenSigSendOnInit" SG_ 2149941248 PrkAstFntnDsbldIO 2;
BA_ "SignalType" SG_ 2149941248 PrkAstFntnDsbldIO "BLN";
BA_ "SignalLongName" SG_ 2149941248 PrkAstFntnDsbldIO "Parking Assistance Function Disabled Indication On";
BA_ "VNSigAllNodes" SG_ 2149941248 PrkAstFntnDsbldIO 1;
BA_ "GenSigSendType" SG_ 2149941248 PrkAstFntnClnPrkAstIO 10;
BA_ "GenSigSendOnInit" SG_ 2149941248 PrkAstFntnClnPrkAstIO 2;
BA_ "SignalType" SG_ 2149941248 PrkAstFntnClnPrkAstIO "BLN";
BA_ "SignalLongName" SG_ 2149941248 PrkAstFntnClnPrkAstIO "Parking Assistance Function Clean Parking Assist Indication On";
BA_ "VNSigAllNodes" SG_ 2149941248 PrkAstFntnClnPrkAstIO 1;
BA_ "GenSigSendType" SG_ 2149941248 ClsnMtgtnInhbtReqtd 10;
BA_ "GenSigSendOnInit" SG_ 2149941248 ClsnMtgtnInhbtReqtd 2;
BA_ "SignalType" SG_ 2149941248 ClsnMtgtnInhbtReqtd "BLN";
BA_ "SignalLongName" SG_ 2149941248 ClsnMtgtnInhbtReqtd "Collision Mitigation Inhibit Requested";
BA_ "VNSigAllNodes" SG_ 2149941248 ClsnMtgtnInhbtReqtd 1;
BA_ "GenSigSendType" SG_ 2149941248 PARrRgn4ObjStatUnfltd 10;
BA_ "GenSigSendOnInit" SG_ 2149941248 PARrRgn4ObjStatUnfltd 2;
BA_ "SignalType" SG_ 2149941248 PARrRgn4ObjStatUnfltd "ENM";
BA_ "SignalLongName" SG_ 2149941248 PARrRgn4ObjStatUnfltd "Parking Assistance Rear Region 4 Object Status Unfiltered";
BA_ "VNSigAllNodes" SG_ 2149941248 PARrRgn4ObjStatUnfltd 1;
BA_ "GenSigSendType" SG_ 2149941248 PARrRgn3ObjStatUnfltd 10;
BA_ "GenSigSendOnInit" SG_ 2149941248 PARrRgn3ObjStatUnfltd 2;
BA_ "SignalType" SG_ 2149941248 PARrRgn3ObjStatUnfltd "ENM";
BA_ "SignalLongName" SG_ 2149941248 PARrRgn3ObjStatUnfltd "Parking Assistance Rear Region 3 Object Status Unfiltered";
BA_ "VNSigAllNodes" SG_ 2149941248 PARrRgn3ObjStatUnfltd 1;
BA_ "GenSigSendType" SG_ 2149941248 PARrRgn2ObjStatUnfltd 10;
BA_ "GenSigSendOnInit" SG_ 2149941248 PARrRgn2ObjStatUnfltd 2;
BA_ "SignalType" SG_ 2149941248 PARrRgn2ObjStatUnfltd "ENM";
BA_ "SignalLongName" SG_ 2149941248 PARrRgn2ObjStatUnfltd "Parking Assistance Rear Region 2 Object Status Unfiltered";
BA_ "VNSigAllNodes" SG_ 2149941248 PARrRgn2ObjStatUnfltd 1;
BA_ "GenSigSendType" SG_ 2149941248 PARrRgn1ObjStatUnfltd 10;
BA_ "GenSigSendOnInit" SG_ 2149941248 PARrRgn1ObjStatUnfltd 2;
BA_ "SignalType" SG_ 2149941248 PARrRgn1ObjStatUnfltd "ENM";
BA_ "SignalLongName" SG_ 2149941248 PARrRgn1ObjStatUnfltd "Parking Assistance Rear Region 1 Object Status Unfiltered";
BA_ "VNSigAllNodes" SG_ 2149941248 PARrRgn1ObjStatUnfltd 1;
BA_ "GenSigSendType" SG_ 2156314624 HVChrgSysSplyFltIO 10;
BA_ "SignalType" SG_ 2156314624 HVChrgSysSplyFltIO "BLN";
BA_ "SignalLongName" SG_ 2156314624 HVChrgSysSplyFltIO "High Voltage Charging System Supply Fault Indication On";
BA_ "VNSigAllNodes" SG_ 2156314624 HVChrgSysSplyFltIO 1;
BA_ "GenSigSendType" SG_ 2156314624 OffBrdCSFltDtctd 10;
BA_ "VNSigInfotainment" SG_ 2156314624 OffBrdCSFltDtctd 1;
BA_ "SignalType" SG_ 2156314624 OffBrdCSFltDtctd "BLN";
BA_ "SignalLongName" SG_ 2156314624 OffBrdCSFltDtctd "Off Board Charge Station Fault Detected";
BA_ "VNSigAllNodes" SG_ 2156314624 OffBrdCSFltDtctd 1;
BA_ "GenSigSendType" SG_ 2156314624 OBVhCsACChgRqBnVs 10;
BA_ "GenSigSendOnInit" SG_ 2156314624 OBVhCsACChgRqBnVs 1;
BA_ "VNSigInfotainment" SG_ 2156314624 OBVhCsACChgRqBnVs 1;
BA_ "SignalType" SG_ 2156314624 OBVhCsACChgRqBnVs "BLN";
BA_ "SignalLongName" SG_ 2156314624 OBVhCsACChgRqBnVs "On Board Vehicle Cease AC Charging Request Button Visible";
BA_ "VNSigAllNodes" SG_ 2156314624 OBVhCsACChgRqBnVs 1;
BA_ "GenSigDeltaValue" SG_ 2156314624 TODCNPDT_Min 1;
BA_ "GenSigSendType" SG_ 2156314624 TODCNPDT_Min 12;
BA_ "GenSigSendOnInit" SG_ 2156314624 TODCNPDT_Min 1;
BA_ "VNSigInfotainment" SG_ 2156314624 TODCNPDT_Min 1;
BA_ "SignalType" SG_ 2156314624 TODCNPDT_Min "UNM";
BA_ "PacketOrder" SG_ 2156314624 TODCNPDT_Min 3;
BA_ "SignalLongName" SG_ 2156314624 TODCNPDT_Min "Time Of Day Charging Next Planned Departure Time : Minute";
BA_ "VNSigAllNodes" SG_ 2156314624 TODCNPDT_Min 1;
BA_ "GenSigDeltaValue" SG_ 2156314624 TODCNPDT_Hr 1;
BA_ "GenSigSendType" SG_ 2156314624 TODCNPDT_Hr 12;
BA_ "GenSigSendOnInit" SG_ 2156314624 TODCNPDT_Hr 1;
BA_ "VNSigInfotainment" SG_ 2156314624 TODCNPDT_Hr 1;
BA_ "SignalType" SG_ 2156314624 TODCNPDT_Hr "UNM";
BA_ "PacketOrder" SG_ 2156314624 TODCNPDT_Hr 2;
BA_ "SignalLongName" SG_ 2156314624 TODCNPDT_Hr "Time Of Day Charging Next Planned Departure Time : Hour";
BA_ "VNSigAllNodes" SG_ 2156314624 TODCNPDT_Hr 1;
BA_ "GenSigSendType" SG_ 2156314624 TODCNPDT_DyOfWk 10;
BA_ "GenSigSendOnInit" SG_ 2156314624 TODCNPDT_DyOfWk 1;
BA_ "VNSigInfotainment" SG_ 2156314624 TODCNPDT_DyOfWk 1;
BA_ "SignalType" SG_ 2156314624 TODCNPDT_DyOfWk "ENM";
BA_ "PacketOrder" SG_ 2156314624 TODCNPDT_DyOfWk 1;
BA_ "SignalLongName" SG_ 2156314624 TODCNPDT_DyOfWk "Time Of Day Charging Next Planned Departure Time : Day of Week";
BA_ "VNSigAllNodes" SG_ 2156314624 TODCNPDT_DyOfWk 1;
BA_ "GenSigDeltaValue" SG_ 2156314624 HVBatBlkSOC 1;
BA_ "GenSigSendType" SG_ 2156314624 HVBatBlkSOC 12;
BA_ "GenSigSendOnInit" SG_ 2156314624 HVBatBlkSOC 1;
BA_ "VNSigInfotainment" SG_ 2156314624 HVBatBlkSOC 1;
BA_ "SignalType" SG_ 2156314624 HVBatBlkSOC "UNM";
BA_ "SignalLongName" SG_ 2156314624 HVBatBlkSOC "High Voltage Battery Bulk State of Charge";
BA_ "VNSigAllNodes" SG_ 2156314624 HVBatBlkSOC 1;
BA_ "GenSigSendType" SG_ 2156314624 TODCOpMd 10;
BA_ "VNSigInfotainment" SG_ 2156314624 TODCOpMd 1;
BA_ "SignalType" SG_ 2156314624 TODCOpMd "ENM";
BA_ "SignalLongName" SG_ 2156314624 TODCOpMd "Time of Day Charging Operating Mode";
BA_ "VNSigAllNodes" SG_ 2156314624 TODCOpMd 1;
BA_ "GenSigSendType" SG_ 2156314624 TODCDMPTO_TpOvR 10;
BA_ "GenSigSendOnInit" SG_ 2156314624 TODCDMPTO_TpOvR 1;
BA_ "VNSigInfotainment" SG_ 2156314624 TODCDMPTO_TpOvR 1;
BA_ "SignalType" SG_ 2156314624 TODCDMPTO_TpOvR "ENM";
BA_ "PacketOrder" SG_ 2156314624 TODCDMPTO_TpOvR 2;
BA_ "SignalLongName" SG_ 2156314624 TODCDMPTO_TpOvR "Time of Day Charging Display Main Page Temporary Override : Display Temporary Override Request";
BA_ "VNSigAllNodes" SG_ 2156314624 TODCDMPTO_TpOvR 1;
BA_ "GenSigSendType" SG_ 2156314624 TODCDMPTO_CmPgR 10;
BA_ "GenSigSendOnInit" SG_ 2156314624 TODCDMPTO_CmPgR 1;
BA_ "VNSigInfotainment" SG_ 2156314624 TODCDMPTO_CmPgR 1;
BA_ "SignalType" SG_ 2156314624 TODCDMPTO_CmPgR "BLN";
BA_ "PacketOrder" SG_ 2156314624 TODCDMPTO_CmPgR 1;
BA_ "SignalLongName" SG_ 2156314624 TODCDMPTO_CmPgR "Time of Day Charging Display Main Page Temporary Override : Charging Complete Page Requested";
BA_ "VNSigAllNodes" SG_ 2156314624 TODCDMPTO_CmPgR 1;
BA_ "GenSigSendType" SG_ 2156314624 HVChrgSysStNot 10;
BA_ "VNSigInfotainment" SG_ 2156314624 HVChrgSysStNot 1;
BA_ "SignalType" SG_ 2156314624 HVChrgSysStNot "ENM";
BA_ "SignalLongName" SG_ 2156314624 HVChrgSysStNot "High Voltage Charger System Status Notification";
BA_ "VNSigAllNodes" SG_ 2156314624 HVChrgSysStNot 1;
BA_ "GenSigSendType" SG_ 2156314624 HVChrgAbrtRsn 10;
BA_ "VNSigInfotainment" SG_ 2156314624 HVChrgAbrtRsn 1;
BA_ "SignalType" SG_ 2156314624 HVChrgAbrtRsn "ENM";
BA_ "SignalLongName" SG_ 2156314624 HVChrgAbrtRsn "High Voltage Charge Abort Reason";
BA_ "VNSigAllNodes" SG_ 2156314624 HVChrgAbrtRsn 1;
BA_ "GenSigSendType" SG_ 2156314624 HVCSCLPD_UsrIntTyp 10;
BA_ "GenSigSendOnInit" SG_ 2156314624 HVCSCLPD_UsrIntTyp 1;
BA_ "VNSigInfotainment" SG_ 2156314624 HVCSCLPD_UsrIntTyp 1;
BA_ "SignalType" SG_ 2156314624 HVCSCLPD_UsrIntTyp "ENM";
BA_ "PacketOrder" SG_ 2156314624 HVCSCLPD_UsrIntTyp 1;
BA_ "SignalLongName" SG_ 2156314624 HVCSCLPD_UsrIntTyp "High Voltage Charging System Charge Level Preference Data : User Interface Type";
BA_ "VNSigAllNodes" SG_ 2156314624 HVCSCLPD_UsrIntTyp 1;
BA_ "GenSigDeltaValue" SG_ 2156314624 HVCSCLPD_RdCrntLv3 1;
BA_ "GenSigSendType" SG_ 2156314624 HVCSCLPD_RdCrntLv3 12;
BA_ "GenSigSendOnInit" SG_ 2156314624 HVCSCLPD_RdCrntLv3 1;
BA_ "VNSigInfotainment" SG_ 2156314624 HVCSCLPD_RdCrntLv3 1;
BA_ "SignalType" SG_ 2156314624 HVCSCLPD_RdCrntLv3 "UNM";
BA_ "PacketOrder" SG_ 2156314624 HVCSCLPD_RdCrntLv3 6;
BA_ "SignalLongName" SG_ 2156314624 HVCSCLPD_RdCrntLv3 "High Voltage Charging System Charge Level Preference Data : Reduced Current Level 3";
BA_ "VNSigAllNodes" SG_ 2156314624 HVCSCLPD_RdCrntLv3 1;
BA_ "GenSigDeltaValue" SG_ 2156314624 HVCSCLPD_RdCrntLv2 1;
BA_ "GenSigSendType" SG_ 2156314624 HVCSCLPD_RdCrntLv2 12;
BA_ "GenSigSendOnInit" SG_ 2156314624 HVCSCLPD_RdCrntLv2 1;
BA_ "VNSigInfotainment" SG_ 2156314624 HVCSCLPD_RdCrntLv2 1;
BA_ "SignalType" SG_ 2156314624 HVCSCLPD_RdCrntLv2 "UNM";
BA_ "PacketOrder" SG_ 2156314624 HVCSCLPD_RdCrntLv2 5;
BA_ "SignalLongName" SG_ 2156314624 HVCSCLPD_RdCrntLv2 "High Voltage Charging System Charge Level Preference Data : Reduced Current Level 2";
BA_ "VNSigAllNodes" SG_ 2156314624 HVCSCLPD_RdCrntLv2 1;
BA_ "GenSigDeltaValue" SG_ 2156314624 HVCSCLPD_RdCrntLv1 1;
BA_ "GenSigSendType" SG_ 2156314624 HVCSCLPD_RdCrntLv1 12;
BA_ "GenSigSendOnInit" SG_ 2156314624 HVCSCLPD_RdCrntLv1 1;
BA_ "VNSigInfotainment" SG_ 2156314624 HVCSCLPD_RdCrntLv1 1;
BA_ "SignalType" SG_ 2156314624 HVCSCLPD_RdCrntLv1 "UNM";
BA_ "PacketOrder" SG_ 2156314624 HVCSCLPD_RdCrntLv1 4;
BA_ "SignalLongName" SG_ 2156314624 HVCSCLPD_RdCrntLv1 "High Voltage Charging System Charge Level Preference Data : Reduced Current Level 1";
BA_ "VNSigAllNodes" SG_ 2156314624 HVCSCLPD_RdCrntLv1 1;
BA_ "GenSigDeltaValue" SG_ 2156314624 HVCSCLPD_NrmChrgC 1;
BA_ "GenSigSendType" SG_ 2156314624 HVCSCLPD_NrmChrgC 12;
BA_ "GenSigSendOnInit" SG_ 2156314624 HVCSCLPD_NrmChrgC 1;
BA_ "VNSigInfotainment" SG_ 2156314624 HVCSCLPD_NrmChrgC 1;
BA_ "SignalType" SG_ 2156314624 HVCSCLPD_NrmChrgC "UNM";
BA_ "PacketOrder" SG_ 2156314624 HVCSCLPD_NrmChrgC 3;
BA_ "SignalLongName" SG_ 2156314624 HVCSCLPD_NrmChrgC "High Voltage Charging System Charge Level Preference Data : Normal Charge Current";
BA_ "VNSigAllNodes" SG_ 2156314624 HVCSCLPD_NrmChrgC 1;
BA_ "GenSigSendType" SG_ 2156314624 HVCSCLPD_ChgLvlPfS 10;
BA_ "GenSigSendOnInit" SG_ 2156314624 HVCSCLPD_ChgLvlPfS 1;
BA_ "VNSigInfotainment" SG_ 2156314624 HVCSCLPD_ChgLvlPfS 1;
BA_ "SignalType" SG_ 2156314624 HVCSCLPD_ChgLvlPfS "ENM";
BA_ "PacketOrder" SG_ 2156314624 HVCSCLPD_ChgLvlPfS 2;
BA_ "SignalLongName" SG_ 2156314624 HVCSCLPD_ChgLvlPfS "High Voltage Charging System Charge Level Preference Data : Charge Level Preference Status";
BA_ "VNSigAllNodes" SG_ 2156314624 HVCSCLPD_ChgLvlPfS 1;
BA_ "GenSigSendType" SG_ 2150449152 ESPDrvrExtIO 10;
BA_ "SignalType" SG_ 2150449152 ESPDrvrExtIO "BLN";
BA_ "SignalLongName" SG_ 2150449152 ESPDrvrExtIO "Electronic Shift Primary Driver Exit Indication On";
BA_ "VNSigAllNodes" SG_ 2150449152 ESPDrvrExtIO 1;
BA_ "GenSigSendType" SG_ 2150449152 ESPDrvrDrStIndtrmntIO 10;
BA_ "SignalType" SG_ 2150449152 ESPDrvrDrStIndtrmntIO "BLN";
BA_ "SignalLongName" SG_ 2150449152 ESPDrvrDrStIndtrmntIO "Electronic Shift Primary Driver Door State Indeterminate Indication On";
BA_ "VNSigAllNodes" SG_ 2150449152 ESPDrvrDrStIndtrmntIO 1;
BA_ "GenSigSendType" SG_ 2150449152 ESPAutoPrkIO 10;
BA_ "SignalType" SG_ 2150449152 ESPAutoPrkIO "BLN";
BA_ "SignalLongName" SG_ 2150449152 ESPAutoPrkIO "Electronic Shift Primary Auto Park Indication On";
BA_ "VNSigAllNodes" SG_ 2150449152 ESPAutoPrkIO 1;
BA_ "GenSigSendType" SG_ 2150449152 ManTransIndReq 10;
BA_ "SignalType" SG_ 2150449152 ManTransIndReq "ENM";
BA_ "SignalLongName" SG_ 2150449152 ManTransIndReq "Manual Transmission Indication Request";
BA_ "VNSigAllNodes" SG_ 2150449152 ManTransIndReq 1;
BA_ "GenSigSendType" SG_ 2150449152 SrvcFlSysPrkInOpnArIO 10;
BA_ "SignalType" SG_ 2150449152 SrvcFlSysPrkInOpnArIO "BLN";
BA_ "SignalLongName" SG_ 2150449152 SrvcFlSysPrkInOpnArIO "Service Fuel System Park In Open Area Indication On";
BA_ "VNSigAllNodes" SG_ 2150449152 SrvcFlSysPrkInOpnArIO 1;
BA_ "GenSigSendType" SG_ 2150449152 TnDrvStblCtrlOffUnbIO 10;
BA_ "SignalType" SG_ 2150449152 TnDrvStblCtrlOffUnbIO "BLN";
BA_ "SignalLongName" SG_ 2150449152 TnDrvStblCtrlOffUnbIO "Teen Driver Stability Control Off Unavailable Indication On";
BA_ "VNSigAllNodes" SG_ 2150449152 TnDrvStblCtrlOffUnbIO 1;
BA_ "GenSigSendType" SG_ 2150449152 TnDrvTrCtrlOffUnbIO 10;
BA_ "SignalType" SG_ 2150449152 TnDrvTrCtrlOffUnbIO "BLN";
BA_ "SignalLongName" SG_ 2150449152 TnDrvTrCtrlOffUnbIO "Teen Driver Traction Control Off Unavailable Indication On";
BA_ "VNSigAllNodes" SG_ 2150449152 TnDrvTrCtrlOffUnbIO 1;
BA_ "GenSigSendType" SG_ 2150449152 ASIRI_Indication08 10;
BA_ "SignalType" SG_ 2150449152 ASIRI_Indication08 "BLN";
BA_ "PacketOrder" SG_ 2150449152 ASIRI_Indication08 8;
BA_ "SignalLongName" SG_ 2150449152 ASIRI_Indication08 "Auto Stop Inhibit Reason Indication : Indication 8";
BA_ "VNSigAllNodes" SG_ 2150449152 ASIRI_Indication08 1;
BA_ "GenSigSendType" SG_ 2150449152 ASIRI_Indication07 10;
BA_ "SignalType" SG_ 2150449152 ASIRI_Indication07 "BLN";
BA_ "PacketOrder" SG_ 2150449152 ASIRI_Indication07 7;
BA_ "SignalLongName" SG_ 2150449152 ASIRI_Indication07 "Auto Stop Inhibit Reason Indication : Indication 7";
BA_ "VNSigAllNodes" SG_ 2150449152 ASIRI_Indication07 1;
BA_ "GenSigSendType" SG_ 2150449152 ASIRI_Indication06 10;
BA_ "SignalType" SG_ 2150449152 ASIRI_Indication06 "BLN";
BA_ "PacketOrder" SG_ 2150449152 ASIRI_Indication06 6;
BA_ "SignalLongName" SG_ 2150449152 ASIRI_Indication06 "Auto Stop Inhibit Reason Indication : Indication 6";
BA_ "VNSigAllNodes" SG_ 2150449152 ASIRI_Indication06 1;
BA_ "GenSigSendType" SG_ 2150449152 ASIRI_Indication05 10;
BA_ "SignalType" SG_ 2150449152 ASIRI_Indication05 "BLN";
BA_ "PacketOrder" SG_ 2150449152 ASIRI_Indication05 5;
BA_ "SignalLongName" SG_ 2150449152 ASIRI_Indication05 "Auto Stop Inhibit Reason Indication : Indication 5";
BA_ "VNSigAllNodes" SG_ 2150449152 ASIRI_Indication05 1;
BA_ "GenSigSendType" SG_ 2150449152 ASIRI_Indication04 10;
BA_ "SignalType" SG_ 2150449152 ASIRI_Indication04 "BLN";
BA_ "PacketOrder" SG_ 2150449152 ASIRI_Indication04 4;
BA_ "SignalLongName" SG_ 2150449152 ASIRI_Indication04 "Auto Stop Inhibit Reason Indication : Indication 4";
BA_ "VNSigAllNodes" SG_ 2150449152 ASIRI_Indication04 1;
BA_ "GenSigSendType" SG_ 2150449152 ASIRI_Indication03 10;
BA_ "SignalType" SG_ 2150449152 ASIRI_Indication03 "BLN";
BA_ "PacketOrder" SG_ 2150449152 ASIRI_Indication03 3;
BA_ "SignalLongName" SG_ 2150449152 ASIRI_Indication03 "Auto Stop Inhibit Reason Indication : Indication 3";
BA_ "VNSigAllNodes" SG_ 2150449152 ASIRI_Indication03 1;
BA_ "GenSigSendType" SG_ 2150449152 ASIRI_Indication02 10;
BA_ "SignalType" SG_ 2150449152 ASIRI_Indication02 "BLN";
BA_ "PacketOrder" SG_ 2150449152 ASIRI_Indication02 2;
BA_ "SignalLongName" SG_ 2150449152 ASIRI_Indication02 "Auto Stop Inhibit Reason Indication : Indication 2";
BA_ "VNSigAllNodes" SG_ 2150449152 ASIRI_Indication02 1;
BA_ "GenSigSendType" SG_ 2150449152 ASIRI_Indication01 10;
BA_ "SignalType" SG_ 2150449152 ASIRI_Indication01 "BLN";
BA_ "PacketOrder" SG_ 2150449152 ASIRI_Indication01 1;
BA_ "SignalLongName" SG_ 2150449152 ASIRI_Indication01 "Auto Stop Inhibit Reason Indication : Indication 1";
BA_ "VNSigAllNodes" SG_ 2150449152 ASIRI_Indication01 1;
BA_ "GenSigSendType" SG_ 2150449152 SpdLmtrSttngTypAct 10;
BA_ "SignalType" SG_ 2150449152 SpdLmtrSttngTypAct "ENM";
BA_ "SignalLongName" SG_ 2150449152 SpdLmtrSttngTypAct "Speed Limiter Setting Type Active";
BA_ "VNSigAllNodes" SG_ 2150449152 SpdLmtrSttngTypAct 1;
BA_ "GenSigSendType" SG_ 2150449152 FuelSysNEmsRltMalfAct 10;
BA_ "SignalType" SG_ 2150449152 FuelSysNEmsRltMalfAct "BLN";
BA_ "SignalLongName" SG_ 2150449152 FuelSysNEmsRltMalfAct "Fuel System Non Emissions Related Malfunction Active";
BA_ "VNSigAllNodes" SG_ 2150449152 FuelSysNEmsRltMalfAct 1;
BA_ "GenSigSendType" SG_ 2150449152 InActFuelMdFuelLvlIO 10;
BA_ "SignalType" SG_ 2150449152 InActFuelMdFuelLvlIO "BLN";
BA_ "SignalLongName" SG_ 2150449152 InActFuelMdFuelLvlIO "Inactive Fuel Mode Fuel Level Indication On";
BA_ "VNSigAllNodes" SG_ 2150449152 InActFuelMdFuelLvlIO 1;
BA_ "GenSigSendType" SG_ 2150449152 EngInltSpcfcHmdtyV 10;
BA_ "SignalType" SG_ 2150449152 EngInltSpcfcHmdtyV "ENM";
BA_ "SignalLongName" SG_ 2150449152 EngInltSpcfcHmdtyV "Engine Inlet Specific Humidity Validity";
BA_ "VNSigAllNodes" SG_ 2150449152 EngInltSpcfcHmdtyV 1;
BA_ "GenSigSendType" SG_ 2150449152 EngInltSpcfcHmdtyM 10;
BA_ "SignalType" SG_ 2150449152 EngInltSpcfcHmdtyM "ENM";
BA_ "SignalLongName" SG_ 2150449152 EngInltSpcfcHmdtyM "Engine Inlet Specific Humidity Mask";
BA_ "VNSigAllNodes" SG_ 2150449152 EngInltSpcfcHmdtyM 1;
BA_ "GenSigDeltaValue" SG_ 2150449152 EngInltSpcfcHmdty 1;
BA_ "GenSigSendType" SG_ 2150449152 EngInltSpcfcHmdty 12;
BA_ "SignalType" SG_ 2150449152 EngInltSpcfcHmdty "UNM";
BA_ "SignalLongName" SG_ 2150449152 EngInltSpcfcHmdty "Engine Inlet Specific Humidity";
BA_ "VNSigAllNodes" SG_ 2150449152 EngInltSpcfcHmdty 1;
BA_ "GenSigSendType" SG_ 2150449152 AltFuelSysOvrflDtdIO 10;
BA_ "GenSigSendOnInit" SG_ 2150449152 AltFuelSysOvrflDtdIO 2;
BA_ "SignalType" SG_ 2150449152 AltFuelSysOvrflDtdIO "BLN";
BA_ "SignalLongName" SG_ 2150449152 AltFuelSysOvrflDtdIO "Alternative Fuel System Overfill Detected Indication On";
BA_ "VNSigAllNodes" SG_ 2150449152 AltFuelSysOvrflDtdIO 1;
BA_ "GenSigDeltaValue" SG_ 2149810176 FCAHptcStVbnRqSeqN 1;
BA_ "GenSigSendType" SG_ 2149810176 FCAHptcStVbnRqSeqN 12;
BA_ "SignalType" SG_ 2149810176 FCAHptcStVbnRqSeqN "UNM";
BA_ "SignalLongName" SG_ 2149810176 FCAHptcStVbnRqSeqN "Forward Collision Alert Haptic Seat Vibration Request Sequence Number";
BA_ "VNSigAllNodes" SG_ 2149810176 FCAHptcStVbnRqSeqN 1;
BA_ "GenSigDeltaValue" SG_ 2149810176 FCAHptcStVbnReq 1;
BA_ "GenSigSendType" SG_ 2149810176 FCAHptcStVbnReq 12;
BA_ "SignalType" SG_ 2149810176 FCAHptcStVbnReq "UNM";
BA_ "SignalLongName" SG_ 2149810176 FCAHptcStVbnReq "Forward Collision Alert Haptic Seat Vibration Request";
BA_ "VNSigAllNodes" SG_ 2149810176 FCAHptcStVbnReq 1;
BA_ "GenSigSendType" SG_ 2149793792 AutoEmrgncyBrkDisbldIO 10;
BA_ "GenSigSendOnInit" SG_ 2149793792 AutoEmrgncyBrkDisbldIO 2;
BA_ "SignalType" SG_ 2149793792 AutoEmrgncyBrkDisbldIO "BLN";
BA_ "SignalLongName" SG_ 2149793792 AutoEmrgncyBrkDisbldIO "Automatic Emergency Braking Disabled Indication On";
BA_ "VNSigAllNodes" SG_ 2149793792 AutoEmrgncyBrkDisbldIO 1;
BA_ "GenSigSendType" SG_ 2149793792 VADIR_IndLvl 10;
BA_ "GenSigSendOnInit" SG_ 2149793792 VADIR_IndLvl 1;
BA_ "SignalType" SG_ 2149793792 VADIR_IndLvl "ENM";
BA_ "PacketOrder" SG_ 2149793792 VADIR_IndLvl 1;
BA_ "SignalLongName" SG_ 2149793792 VADIR_IndLvl "Vehicle Ahead Distance Indication Request : Indication Level";
BA_ "VNSigAllNodes" SG_ 2149793792 VADIR_IndLvl 1;
BA_ "GenSigDeltaValue" SG_ 2149793792 VADIR_FlwTme 1;
BA_ "GenSigSendType" SG_ 2149793792 VADIR_FlwTme 12;
BA_ "GenSigSendOnInit" SG_ 2149793792 VADIR_FlwTme 1;
BA_ "SignalType" SG_ 2149793792 VADIR_FlwTme "UNM";
BA_ "PacketOrder" SG_ 2149793792 VADIR_FlwTme 2;
BA_ "SignalLongName" SG_ 2149793792 VADIR_FlwTme "Vehicle Ahead Distance Indication Request : Following Time";
BA_ "VNSigAllNodes" SG_ 2149793792 VADIR_FlwTme 1;
BA_ "GenSigDeltaValue" SG_ 2149793792 VADIR_FlwDst 1;
BA_ "GenSigSendType" SG_ 2149793792 VADIR_FlwDst 12;
BA_ "GenSigSendOnInit" SG_ 2149793792 VADIR_FlwDst 1;
BA_ "SignalType" SG_ 2149793792 VADIR_FlwDst "UNM";
BA_ "PacketOrder" SG_ 2149793792 VADIR_FlwDst 3;
BA_ "SignalLongName" SG_ 2149793792 VADIR_FlwDst "Vehicle Ahead Distance Indication Request : Following Distance";
BA_ "VNSigAllNodes" SG_ 2149793792 VADIR_FlwDst 1;
BA_ "GenSigSendType" SG_ 2149793792 FCACustStngAvlbl 10;
BA_ "GenSigSendOnInit" SG_ 2149793792 FCACustStngAvlbl 2;
BA_ "SignalType" SG_ 2149793792 FCACustStngAvlbl "BLN";
BA_ "SignalLongName" SG_ 2149793792 FCACustStngAvlbl "Forward Collision Alert Customization Setting Available";
BA_ "VNSigAllNodes" SG_ 2149793792 FCACustStngAvlbl 1;
BA_ "GenSigSendType" SG_ 2149793792 FwdClnAlrtCustCrntSetngVal 10;
BA_ "GenSigSendOnInit" SG_ 2149793792 FwdClnAlrtCustCrntSetngVal 2;
BA_ "SignalType" SG_ 2149793792 FwdClnAlrtCustCrntSetngVal "ENM";
BA_ "SignalLongName" SG_ 2149793792 FwdClnAlrtCustCrntSetngVal "Forward Collision Alert Customization Current Setting Value";
BA_ "VNSigAllNodes" SG_ 2149793792 FwdClnAlrtCustCrntSetngVal 1;
BA_ "GenSigSendType" SG_ 2150080512 LBCVLS_VehGPSLctV 10;
BA_ "GenSigSendOnInit" SG_ 2150080512 LBCVLS_VehGPSLctV 1;
BA_ "PacketOrder" SG_ 2150080512 LBCVLS_VehGPSLctV 1;
BA_ "VNSigInfotainment" SG_ 2150080512 LBCVLS_VehGPSLctV 1;
BA_ "SignalType" SG_ 2150080512 LBCVLS_VehGPSLctV "ENM";
BA_ "SignalLongName" SG_ 2150080512 LBCVLS_VehGPSLctV "Location Based Charging Vehicle Location Status : Vehicle GPS Location Validity";
BA_ "VNSigAllNodes" SG_ 2150080512 LBCVLS_VehGPSLctV 1;
BA_ "GenSigSendType" SG_ 2150080512 LBCVLS_VehGPSLct 10;
BA_ "GenSigSendOnInit" SG_ 2150080512 LBCVLS_VehGPSLct 1;
BA_ "PacketOrder" SG_ 2150080512 LBCVLS_VehGPSLct 2;
BA_ "VNSigInfotainment" SG_ 2150080512 LBCVLS_VehGPSLct 1;
BA_ "SignalType" SG_ 2150080512 LBCVLS_VehGPSLct "ENM";
BA_ "SignalLongName" SG_ 2150080512 LBCVLS_VehGPSLct "Location Based Charging Vehicle Location Status : Vehicle GPS Location";
BA_ "VNSigAllNodes" SG_ 2150080512 LBCVLS_VehGPSLct 1;
BA_ "GenSigSendType" SG_ 2150080512 LBCPSS_PosUpdtStat 10;
BA_ "GenSigSendOnInit" SG_ 2150080512 LBCPSS_PosUpdtStat 1;
BA_ "VNSigInfotainment" SG_ 2150080512 LBCPSS_PosUpdtStat 1;
BA_ "SignalType" SG_ 2150080512 LBCPSS_PosUpdtStat "ENM";
BA_ "PacketOrder" SG_ 2150080512 LBCPSS_PosUpdtStat 1;
BA_ "SignalLongName" SG_ 2150080512 LBCPSS_PosUpdtStat "Location Based Charging Position Storage Status : Position Update Status";
BA_ "VNSigAllNodes" SG_ 2150080512 LBCPSS_PosUpdtStat 1;
BA_ "GenSigSendType" SG_ 2150080512 LBCPSS_PosUpdtLct 10;
BA_ "GenSigSendOnInit" SG_ 2150080512 LBCPSS_PosUpdtLct 1;
BA_ "VNSigInfotainment" SG_ 2150080512 LBCPSS_PosUpdtLct 1;
BA_ "SignalType" SG_ 2150080512 LBCPSS_PosUpdtLct "ENM";
BA_ "PacketOrder" SG_ 2150080512 LBCPSS_PosUpdtLct 2;
BA_ "SignalLongName" SG_ 2150080512 LBCPSS_PosUpdtLct "Location Based Charging Position Storage Status : Position Update Location";
BA_ "VNSigAllNodes" SG_ 2150080512 LBCPSS_PosUpdtLct 1;
BA_ "GenSigSendType" SG_ 2150080512 LBCCsStAvl 10;
BA_ "GenSigSendOnInit" SG_ 2150080512 LBCCsStAvl 1;
BA_ "VNSigInfotainment" SG_ 2150080512 LBCCsStAvl 1;
BA_ "SignalType" SG_ 2150080512 LBCCsStAvl "BLN";
BA_ "SignalLongName" SG_ 2150080512 LBCCsStAvl "Location Based Charging Customization Setting Available";
BA_ "VNSigAllNodes" SG_ 2150080512 LBCCsStAvl 1;
BA_ "GenSigSendType" SG_ 2150080512 LBCCsCrStVal 10;
BA_ "GenSigSendOnInit" SG_ 2150080512 LBCCsCrStVal 1;
BA_ "VNSigInfotainment" SG_ 2150080512 LBCCsCrStVal 1;
BA_ "SignalType" SG_ 2150080512 LBCCsCrStVal "ENM";
BA_ "SignalLongName" SG_ 2150080512 LBCCsCrStVal "Location Based Charging Customization Current Setting Value";
BA_ "VNSigAllNodes" SG_ 2150080512 LBCCsCrStVal 1;
BA_ "GenSigSendType" SG_ 2150080512 LBCCF_Lct4PosStrdIO 10;
BA_ "GenSigSendOnInit" SG_ 2150080512 LBCCF_Lct4PosStrdIO 1;
BA_ "VNSigInfotainment" SG_ 2150080512 LBCCF_Lct4PosStrdIO 1;
BA_ "SignalType" SG_ 2150080512 LBCCF_Lct4PosStrdIO "BLN";
BA_ "PacketOrder" SG_ 2150080512 LBCCF_Lct4PosStrdIO 4;
BA_ "SignalLongName" SG_ 2150080512 LBCCF_Lct4PosStrdIO "Location Based Charging Customer Feedback : Location 4 Position Stored Indication On";
BA_ "VNSigAllNodes" SG_ 2150080512 LBCCF_Lct4PosStrdIO 1;
BA_ "GenSigSendType" SG_ 2150080512 LBCCF_Lct3PosStrdIO 10;
BA_ "GenSigSendOnInit" SG_ 2150080512 LBCCF_Lct3PosStrdIO 1;
BA_ "VNSigInfotainment" SG_ 2150080512 LBCCF_Lct3PosStrdIO 1;
BA_ "SignalType" SG_ 2150080512 LBCCF_Lct3PosStrdIO "BLN";
BA_ "PacketOrder" SG_ 2150080512 LBCCF_Lct3PosStrdIO 3;
BA_ "SignalLongName" SG_ 2150080512 LBCCF_Lct3PosStrdIO "Location Based Charging Customer Feedback : Location 3 Position Stored Indication On";
BA_ "VNSigAllNodes" SG_ 2150080512 LBCCF_Lct3PosStrdIO 1;
BA_ "GenSigSendType" SG_ 2150080512 LBCCF_Lct2PosStrdIO 10;
BA_ "GenSigSendOnInit" SG_ 2150080512 LBCCF_Lct2PosStrdIO 1;
BA_ "VNSigInfotainment" SG_ 2150080512 LBCCF_Lct2PosStrdIO 1;
BA_ "SignalType" SG_ 2150080512 LBCCF_Lct2PosStrdIO "BLN";
BA_ "PacketOrder" SG_ 2150080512 LBCCF_Lct2PosStrdIO 2;
BA_ "SignalLongName" SG_ 2150080512 LBCCF_Lct2PosStrdIO "Location Based Charging Customer Feedback : Location 2 Position Stored Indication On";
BA_ "VNSigAllNodes" SG_ 2150080512 LBCCF_Lct2PosStrdIO 1;
BA_ "GenSigSendType" SG_ 2150080512 LBCCF_Lct1PosStrdIO 10;
BA_ "GenSigSendOnInit" SG_ 2150080512 LBCCF_Lct1PosStrdIO 1;
BA_ "VNSigInfotainment" SG_ 2150080512 LBCCF_Lct1PosStrdIO 1;
BA_ "SignalType" SG_ 2150080512 LBCCF_Lct1PosStrdIO "BLN";
BA_ "PacketOrder" SG_ 2150080512 LBCCF_Lct1PosStrdIO 1;
BA_ "SignalLongName" SG_ 2150080512 LBCCF_Lct1PosStrdIO "Location Based Charging Customer Feedback : Location 1 Position Stored Indication On";
BA_ "VNSigAllNodes" SG_ 2150080512 LBCCF_Lct1PosStrdIO 1;
BA_ "GenSigSendType" SG_ 2150080512 LBCCDRR_PosNumbr 10;
BA_ "VNSigInfotainment" SG_ 2150080512 LBCCDRR_PosNumbr 1;
BA_ "SignalType" SG_ 2150080512 LBCCDRR_PosNumbr "ENM";
BA_ "PacketOrder" SG_ 2150080512 LBCCDRR_PosNumbr 2;
BA_ "SignalLongName" SG_ 2150080512 LBCCDRR_PosNumbr "Location Based Charging Customer Data Reset Response : Position Number";
BA_ "VNSigAllNodes" SG_ 2150080512 LBCCDRR_PosNumbr 1;
BA_ "GenSigSendType" SG_ 2150080512 LBCCDRR_ClrStrdPosResp 10;
BA_ "VNSigInfotainment" SG_ 2150080512 LBCCDRR_ClrStrdPosResp 1;
BA_ "SignalType" SG_ 2150080512 LBCCDRR_ClrStrdPosResp "ENM";
BA_ "PacketOrder" SG_ 2150080512 LBCCDRR_ClrStrdPosResp 1;
BA_ "SignalLongName" SG_ 2150080512 LBCCDRR_ClrStrdPosResp "Location Based Charging Customer Data Reset Response : Clear Stored Position response";
BA_ "VNSigAllNodes" SG_ 2150080512 LBCCDRR_ClrStrdPosResp 1;
BA_ "GenSigDeltaValue" SG_ 2150080512 ChrgCyclOvrlEngyEcnEq 1;
BA_ "GenSigSendType" SG_ 2150080512 ChrgCyclOvrlEngyEcnEq 12;
BA_ "GenSigSendOnInit" SG_ 2150080512 ChrgCyclOvrlEngyEcnEq 1;
BA_ "VNSigInfotainment" SG_ 2150080512 ChrgCyclOvrlEngyEcnEq 1;
BA_ "SignalType" SG_ 2150080512 ChrgCyclOvrlEngyEcnEq "UNM";
BA_ "SignalLongName" SG_ 2150080512 ChrgCyclOvrlEngyEcnEq "Charge Cycle Overall Energy Economy Equivalent";
BA_ "VNSigAllNodes" SG_ 2150080512 ChrgCyclOvrlEngyEcnEq 1;
BA_ "GenSigDeltaValue" SG_ 2150080512 ChrgCyclElecEngyEcnEq 1;
BA_ "GenSigSendType" SG_ 2150080512 ChrgCyclElecEngyEcnEq 12;
BA_ "GenSigSendOnInit" SG_ 2150080512 ChrgCyclElecEngyEcnEq 1;
BA_ "VNSigInfotainment" SG_ 2150080512 ChrgCyclElecEngyEcnEq 1;
BA_ "SignalType" SG_ 2150080512 ChrgCyclElecEngyEcnEq "UNM";
BA_ "SignalLongName" SG_ 2150080512 ChrgCyclElecEngyEcnEq "Charge Cycle Electrical Energy Economy Equivalent";
BA_ "VNSigAllNodes" SG_ 2150080512 ChrgCyclElecEngyEcnEq 1;
BA_ "GenSigSendType" SG_ 2150080512 LBCChrgLvlPrfExpIO 10;
BA_ "GenSigSendOnInit" SG_ 2150080512 LBCChrgLvlPrfExpIO 1;
BA_ "VNSigInfotainment" SG_ 2150080512 LBCChrgLvlPrfExpIO 1;
BA_ "SignalType" SG_ 2150080512 LBCChrgLvlPrfExpIO "BLN";
BA_ "SignalLongName" SG_ 2150080512 LBCChrgLvlPrfExpIO "Location Based Charging Charge Level Preference Expiration Indication On";
BA_ "VNSigAllNodes" SG_ 2150080512 LBCChrgLvlPrfExpIO 1;
BA_ "GenSigSendType" SG_ 2150080512 EngAstHtDfrdHtMdAct 10;
BA_ "SignalType" SG_ 2150080512 EngAstHtDfrdHtMdAct "BLN";
BA_ "SignalLongName" SG_ 2150080512 EngAstHtDfrdHtMdAct "Engine Assisted Heating Deferred Heat Mode Active";
BA_ "VNSigAllNodes" SG_ 2150080512 EngAstHtDfrdHtMdAct 1;
BA_ "GenSigSendType" SG_ 2150080512 AuxClntHtrVlvStat 10;
BA_ "GenSigSendOnInit" SG_ 2150080512 AuxClntHtrVlvStat 1;
BA_ "SignalType" SG_ 2150080512 AuxClntHtrVlvStat "ENM";
BA_ "SignalLongName" SG_ 2150080512 AuxClntHtrVlvStat "Auxiliary Coolant Heater Valve Status";
BA_ "VNSigAllNodes" SG_ 2150080512 AuxClntHtrVlvStat 1;
BA_ "GenSigSendType" SG_ 2153873408 MnlHtdStWhlRqstd 10;
BA_ "SignalType" SG_ 2153873408 MnlHtdStWhlRqstd "BLN";
BA_ "SignalLongName" SG_ 2153873408 MnlHtdStWhlRqstd "Manual Heated Steering Wheel Requested";
BA_ "VNSigAllNodes" SG_ 2153873408 MnlHtdStWhlRqstd 1;
BA_ "SignalType" SG_ 2152128512 PSPMCA_PsngStPrfMd6Avl "BLN";
BA_ "PacketOrder" SG_ 2152128512 PSPMCA_PsngStPrfMd6Avl 6;
BA_ "SignalLongName" SG_ 2152128512 PSPMCA_PsngStPrfMd6Avl "Passenger Seat Performance Mode Customization Available : Passenger Seat Performance Mode 6 Available";
BA_ "VNSigAllNodes" SG_ 2152128512 PSPMCA_PsngStPrfMd6Avl 1;
BA_ "SignalType" SG_ 2152128512 PSPMCA_PsngStPrfMd5Avl "BLN";
BA_ "PacketOrder" SG_ 2152128512 PSPMCA_PsngStPrfMd5Avl 5;
BA_ "SignalLongName" SG_ 2152128512 PSPMCA_PsngStPrfMd5Avl "Passenger Seat Performance Mode Customization Available : Passenger Seat Performance Mode 5 Available";
BA_ "VNSigAllNodes" SG_ 2152128512 PSPMCA_PsngStPrfMd5Avl 1;
BA_ "SignalType" SG_ 2152128512 PSPMCA_PsngStPrfMd4Avl "BLN";
BA_ "PacketOrder" SG_ 2152128512 PSPMCA_PsngStPrfMd4Avl 4;
BA_ "SignalLongName" SG_ 2152128512 PSPMCA_PsngStPrfMd4Avl "Passenger Seat Performance Mode Customization Available : Passenger Seat Performance Mode 4 Available";
BA_ "VNSigAllNodes" SG_ 2152128512 PSPMCA_PsngStPrfMd4Avl 1;
BA_ "SignalType" SG_ 2152128512 PSPMCA_PsngStPrfMd3Avl "BLN";
BA_ "PacketOrder" SG_ 2152128512 PSPMCA_PsngStPrfMd3Avl 3;
BA_ "SignalLongName" SG_ 2152128512 PSPMCA_PsngStPrfMd3Avl "Passenger Seat Performance Mode Customization Available : Passenger Seat Performance Mode 3 Available";
BA_ "VNSigAllNodes" SG_ 2152128512 PSPMCA_PsngStPrfMd3Avl 1;
BA_ "SignalType" SG_ 2152128512 PSPMCA_PsngStPrfMd2Avl "BLN";
BA_ "PacketOrder" SG_ 2152128512 PSPMCA_PsngStPrfMd2Avl 2;
BA_ "SignalLongName" SG_ 2152128512 PSPMCA_PsngStPrfMd2Avl "Passenger Seat Performance Mode Customization Available : Passenger Seat Performance Mode 2 Available";
BA_ "VNSigAllNodes" SG_ 2152128512 PSPMCA_PsngStPrfMd2Avl 1;
BA_ "SignalType" SG_ 2152128512 PSPMCA_PsngStPrfMd1Avl "BLN";
BA_ "PacketOrder" SG_ 2152128512 PSPMCA_PsngStPrfMd1Avl 1;
BA_ "SignalLongName" SG_ 2152128512 PSPMCA_PsngStPrfMd1Avl "Passenger Seat Performance Mode Customization Available : Passenger Seat Performance Mode 1 Available";
BA_ "VNSigAllNodes" SG_ 2152128512 PSPMCA_PsngStPrfMd1Avl 1;
BA_ "SignalType" SG_ 2152128512 DSPMCA_DrvrStPrfMd6Avl "BLN";
BA_ "PacketOrder" SG_ 2152128512 DSPMCA_DrvrStPrfMd6Avl 6;
BA_ "SignalLongName" SG_ 2152128512 DSPMCA_DrvrStPrfMd6Avl "Driver Seat Performance Mode Customization Available : Driver Seat Performance Mode 6 Available";
BA_ "VNSigAllNodes" SG_ 2152128512 DSPMCA_DrvrStPrfMd6Avl 1;
BA_ "SignalType" SG_ 2152128512 DSPMCA_DrvrStPrfMd5Avl "BLN";
BA_ "PacketOrder" SG_ 2152128512 DSPMCA_DrvrStPrfMd5Avl 5;
BA_ "SignalLongName" SG_ 2152128512 DSPMCA_DrvrStPrfMd5Avl "Driver Seat Performance Mode Customization Available : Driver Seat Performance Mode 5 Available";
BA_ "VNSigAllNodes" SG_ 2152128512 DSPMCA_DrvrStPrfMd5Avl 1;
BA_ "SignalType" SG_ 2152128512 DSPMCA_DrvrStPrfMd4Avl "BLN";
BA_ "PacketOrder" SG_ 2152128512 DSPMCA_DrvrStPrfMd4Avl 4;
BA_ "SignalLongName" SG_ 2152128512 DSPMCA_DrvrStPrfMd4Avl "Driver Seat Performance Mode Customization Available : Driver Seat Performance Mode 4 Available";
BA_ "VNSigAllNodes" SG_ 2152128512 DSPMCA_DrvrStPrfMd4Avl 1;
BA_ "SignalType" SG_ 2152128512 DSPMCA_DrvrStPrfMd3Avl "BLN";
BA_ "PacketOrder" SG_ 2152128512 DSPMCA_DrvrStPrfMd3Avl 3;
BA_ "SignalLongName" SG_ 2152128512 DSPMCA_DrvrStPrfMd3Avl "Driver Seat Performance Mode Customization Available : Driver Seat Performance Mode 3 Available";
BA_ "VNSigAllNodes" SG_ 2152128512 DSPMCA_DrvrStPrfMd3Avl 1;
BA_ "SignalType" SG_ 2152128512 DSPMCA_DrvrStPrfMd2Avl "BLN";
BA_ "PacketOrder" SG_ 2152128512 DSPMCA_DrvrStPrfMd2Avl 2;
BA_ "SignalLongName" SG_ 2152128512 DSPMCA_DrvrStPrfMd2Avl "Driver Seat Performance Mode Customization Available : Driver Seat Performance Mode 2 Available";
BA_ "VNSigAllNodes" SG_ 2152128512 DSPMCA_DrvrStPrfMd2Avl 1;
BA_ "SignalType" SG_ 2152128512 DSPMCA_DrvrStPrfMd1Avl "BLN";
BA_ "PacketOrder" SG_ 2152128512 DSPMCA_DrvrStPrfMd1Avl 1;
BA_ "SignalLongName" SG_ 2152128512 DSPMCA_DrvrStPrfMd1Avl "Driver Seat Performance Mode Customization Available : Driver Seat Performance Mode 1 Available";
BA_ "VNSigAllNodes" SG_ 2152128512 DSPMCA_DrvrStPrfMd1Avl 1;
BA_ "SignalType" SG_ 2152128512 DSPMCA_DrvStyPrfMd7Avl "BLN";
BA_ "PacketOrder" SG_ 2152128512 DSPMCA_DrvStyPrfMd7Avl 7;
BA_ "SignalLongName" SG_ 2152128512 DSPMCA_DrvStyPrfMd7Avl "Driving Style Performance Mode Customization Available : Driving Style Performance Mode 7 Available";
BA_ "VNSigAllNodes" SG_ 2152128512 DSPMCA_DrvStyPrfMd7Avl 1;
BA_ "SignalType" SG_ 2152128512 DSPMCA_DrvStyPrfMd6Avl "BLN";
BA_ "PacketOrder" SG_ 2152128512 DSPMCA_DrvStyPrfMd6Avl 6;
BA_ "SignalLongName" SG_ 2152128512 DSPMCA_DrvStyPrfMd6Avl "Driving Style Performance Mode Customization Available : Driving Style Performance Mode 6 Available";
BA_ "VNSigAllNodes" SG_ 2152128512 DSPMCA_DrvStyPrfMd6Avl 1;
BA_ "SignalType" SG_ 2152128512 DSPMCA_DrvStyPrfMd5Avl "BLN";
BA_ "PacketOrder" SG_ 2152128512 DSPMCA_DrvStyPrfMd5Avl 5;
BA_ "SignalLongName" SG_ 2152128512 DSPMCA_DrvStyPrfMd5Avl "Driving Style Performance Mode Customization Available : Driving Style Performance Mode 5 Available";
BA_ "VNSigAllNodes" SG_ 2152128512 DSPMCA_DrvStyPrfMd5Avl 1;
BA_ "SignalType" SG_ 2152128512 DSPMCA_DrvStyPrfMd4Avl "BLN";
BA_ "PacketOrder" SG_ 2152128512 DSPMCA_DrvStyPrfMd4Avl 4;
BA_ "SignalLongName" SG_ 2152128512 DSPMCA_DrvStyPrfMd4Avl "Driving Style Performance Mode Customization Available : Driving Style Performance Mode 4 Available";
BA_ "VNSigAllNodes" SG_ 2152128512 DSPMCA_DrvStyPrfMd4Avl 1;
BA_ "SignalType" SG_ 2152128512 DSPMCA_DrvStyPrfMd3Avl "BLN";
BA_ "PacketOrder" SG_ 2152128512 DSPMCA_DrvStyPrfMd3Avl 3;
BA_ "SignalLongName" SG_ 2152128512 DSPMCA_DrvStyPrfMd3Avl "Driving Style Performance Mode Customization Available : Driving Style Performance Mode 3 Available";
BA_ "VNSigAllNodes" SG_ 2152128512 DSPMCA_DrvStyPrfMd3Avl 1;
BA_ "SignalType" SG_ 2152128512 DSPMCA_DrvStyPrfMd2Avl "BLN";
BA_ "PacketOrder" SG_ 2152128512 DSPMCA_DrvStyPrfMd2Avl 2;
BA_ "SignalLongName" SG_ 2152128512 DSPMCA_DrvStyPrfMd2Avl "Driving Style Performance Mode Customization Available : Driving Style Performance Mode 2 Available";
BA_ "VNSigAllNodes" SG_ 2152128512 DSPMCA_DrvStyPrfMd2Avl 1;
BA_ "SignalType" SG_ 2152128512 DSPMCA_DrvStyPrfMd1Avl "BLN";
BA_ "PacketOrder" SG_ 2152128512 DSPMCA_DrvStyPrfMd1Avl 1;
BA_ "SignalLongName" SG_ 2152128512 DSPMCA_DrvStyPrfMd1Avl "Driving Style Performance Mode Customization Available : Driving Style Performance Mode 1 Available";
BA_ "VNSigAllNodes" SG_ 2152128512 DSPMCA_DrvStyPrfMd1Avl 1;
BA_ "SignalType" SG_ 2152128512 ACCPMCA_ACCPrfMd6Avl "BLN";
BA_ "PacketOrder" SG_ 2152128512 ACCPMCA_ACCPrfMd6Avl 6;
BA_ "SignalLongName" SG_ 2152128512 ACCPMCA_ACCPrfMd6Avl "Adaptive Cruise Control Performance Mode Customization Available : Adaptive Cruise Control Performance Mode 6 Available";
BA_ "VNSigAllNodes" SG_ 2152128512 ACCPMCA_ACCPrfMd6Avl 1;
BA_ "SignalType" SG_ 2152128512 ACCPMCA_ACCPrfMd5Avl "BLN";
BA_ "PacketOrder" SG_ 2152128512 ACCPMCA_ACCPrfMd5Avl 5;
BA_ "SignalLongName" SG_ 2152128512 ACCPMCA_ACCPrfMd5Avl "Adaptive Cruise Control Performance Mode Customization Available : Adaptive Cruise Control Performance Mode 5 Available";
BA_ "VNSigAllNodes" SG_ 2152128512 ACCPMCA_ACCPrfMd5Avl 1;
BA_ "SignalType" SG_ 2152128512 ACCPMCA_ACCPrfMd4Avl "BLN";
BA_ "PacketOrder" SG_ 2152128512 ACCPMCA_ACCPrfMd4Avl 4;
BA_ "SignalLongName" SG_ 2152128512 ACCPMCA_ACCPrfMd4Avl "Adaptive Cruise Control Performance Mode Customization Available : Adaptive Cruise Control Performance Mode 4 Available";
BA_ "VNSigAllNodes" SG_ 2152128512 ACCPMCA_ACCPrfMd4Avl 1;
BA_ "SignalType" SG_ 2152128512 ACCPMCA_ACCPrfMd3Avl "BLN";
BA_ "PacketOrder" SG_ 2152128512 ACCPMCA_ACCPrfMd3Avl 3;
BA_ "SignalLongName" SG_ 2152128512 ACCPMCA_ACCPrfMd3Avl "Adaptive Cruise Control Performance Mode Customization Available : Adaptive Cruise Control Performance Mode 3 Available";
BA_ "VNSigAllNodes" SG_ 2152128512 ACCPMCA_ACCPrfMd3Avl 1;
BA_ "SignalType" SG_ 2152128512 ACCPMCA_ACCPrfMd2Avl "BLN";
BA_ "PacketOrder" SG_ 2152128512 ACCPMCA_ACCPrfMd2Avl 2;
BA_ "SignalLongName" SG_ 2152128512 ACCPMCA_ACCPrfMd2Avl "Adaptive Cruise Control Performance Mode Customization Available : Adaptive Cruise Control Performance Mode 2 Available";
BA_ "VNSigAllNodes" SG_ 2152128512 ACCPMCA_ACCPrfMd2Avl 1;
BA_ "SignalType" SG_ 2152128512 ACCPMCA_ACCPrfMd1Avl "BLN";
BA_ "PacketOrder" SG_ 2152128512 ACCPMCA_ACCPrfMd1Avl 1;
BA_ "SignalLongName" SG_ 2152128512 ACCPMCA_ACCPrfMd1Avl "Adaptive Cruise Control Performance Mode Customization Available : Adaptive Cruise Control Performance Mode 1 Available";
BA_ "VNSigAllNodes" SG_ 2152128512 ACCPMCA_ACCPrfMd1Avl 1;
BA_ "GenSigSendType" SG_ 2151997440 DrvDrowSysIndRq 10;
BA_ "SignalType" SG_ 2151997440 DrvDrowSysIndRq "ENM";
BA_ "SignalLongName" SG_ 2151997440 DrvDrowSysIndRq "Driver Drowsiness System Indication Request";
BA_ "VNSigAllNodes" SG_ 2151997440 DrvDrowSysIndRq 1;
BA_ "GenSigSendType" SG_ 2151997440 DrvDrwDetCsCrStVal 10;
BA_ "GenSigSendOnInit" SG_ 2151997440 DrvDrwDetCsCrStVal 2;
BA_ "SignalType" SG_ 2151997440 DrvDrwDetCsCrStVal "ENM";
BA_ "SignalLongName" SG_ 2151997440 DrvDrwDetCsCrStVal "Driver Drowsiness Detection Customization Current Setting Value";
BA_ "VNSigAllNodes" SG_ 2151997440 DrvDrwDetCsCrStVal 1;
BA_ "GenSigSendType" SG_ 2151997440 DrvDrowDetCstStAvl 10;
BA_ "GenSigSendOnInit" SG_ 2151997440 DrvDrowDetCstStAvl 2;
BA_ "SignalType" SG_ 2151997440 DrvDrowDetCstStAvl "BLN";
BA_ "SignalLongName" SG_ 2151997440 DrvDrowDetCstStAvl "Driver Drowsiness Detection Customization Setting Available";
BA_ "VNSigAllNodes" SG_ 2151997440 DrvDrowDetCstStAvl 1;
BA_ "GenSigDeltaValue" SG_ 2151997440 DrvDrsnHptcStRqSeqN 1;
BA_ "GenSigSendType" SG_ 2151997440 DrvDrsnHptcStRqSeqN 12;
BA_ "SignalType" SG_ 2151997440 DrvDrsnHptcStRqSeqN "UNM";
BA_ "SignalLongName" SG_ 2151997440 DrvDrsnHptcStRqSeqN "Driver Drowsiness System Haptic Seat Vibration Request Sequence Number";
BA_ "VNSigAllNodes" SG_ 2151997440 DrvDrsnHptcStRqSeqN 1;
BA_ "GenSigDeltaValue" SG_ 2151997440 DrDrwSysHptcStVbnRq 1;
BA_ "GenSigSendType" SG_ 2151997440 DrDrwSysHptcStVbnRq 12;
BA_ "SignalType" SG_ 2151997440 DrDrwSysHptcStVbnRq "UNM";
BA_ "SignalLongName" SG_ 2151997440 DrDrwSysHptcStVbnRq "Driver Drowsiness System Haptic Seat Vibration Request";
BA_ "VNSigAllNodes" SG_ 2151997440 DrDrwSysHptcStVbnRq 1;
BA_ "GenSigSendType" SG_ 2156331008 EUSD_MsrmntUnit 10;
BA_ "GenSigSendOnInit" SG_ 2156331008 EUSD_MsrmntUnit 1;
BA_ "PacketOrder" SG_ 2156331008 EUSD_MsrmntUnit 2;
BA_ "VNSigInfotainment" SG_ 2156331008 EUSD_MsrmntUnit 1;
BA_ "SignalType" SG_ 2156331008 EUSD_MsrmntUnit "ENM";
BA_ "SignalLongName" SG_ 2156331008 EUSD_MsrmntUnit "Energy Usage Score Display : Measurement Unit";
BA_ "VNSigAllNodes" SG_ 2156331008 EUSD_MsrmntUnit 1;
BA_ "GenSigDeltaValue" SG_ 2156331008 EUSD_MsrmntVal 1;
BA_ "GenSigSendType" SG_ 2156331008 EUSD_MsrmntVal 12;
BA_ "GenSigSendOnInit" SG_ 2156331008 EUSD_MsrmntVal 1;
BA_ "PacketOrder" SG_ 2156331008 EUSD_MsrmntVal 1;
BA_ "VNSigInfotainment" SG_ 2156331008 EUSD_MsrmntVal 1;
BA_ "SignalType" SG_ 2156331008 EUSD_MsrmntVal "UNM";
BA_ "SignalLongName" SG_ 2156331008 EUSD_MsrmntVal "Energy Usage Score Display : Measurement Value";
BA_ "VNSigAllNodes" SG_ 2156331008 EUSD_MsrmntVal 1;
BA_ "GenSigSendType" SG_ 2156331008 LwRngLVLdShdRq 10;
BA_ "VNSigInfotainment" SG_ 2156331008 LwRngLVLdShdRq 1;
BA_ "SignalType" SG_ 2156331008 LwRngLVLdShdRq "ENM";
BA_ "SignalLongName" SG_ 2156331008 LwRngLVLdShdRq "Low Range Low Voltage Load Shedding Request";
BA_ "VNSigAllNodes" SG_ 2156331008 LwRngLVLdShdRq 1;
BA_ "GenSigDeltaValue" SG_ 2156331008 HVDpltnMdMiCnfdcRg 1;
BA_ "GenSigSendType" SG_ 2156331008 HVDpltnMdMiCnfdcRg 12;
BA_ "GenSigSendOnInit" SG_ 2156331008 HVDpltnMdMiCnfdcRg 1;
BA_ "VNSigInfotainment" SG_ 2156331008 HVDpltnMdMiCnfdcRg 1;
BA_ "SignalType" SG_ 2156331008 HVDpltnMdMiCnfdcRg "UNM";
BA_ "SignalLongName" SG_ 2156331008 HVDpltnMdMiCnfdcRg "High Voltage Depletion Mode Minimum Confidence Range";
BA_ "VNSigAllNodes" SG_ 2156331008 HVDpltnMdMiCnfdcRg 1;
BA_ "GenSigDeltaValue" SG_ 2156331008 HVDpltnMdMxCnfdcRg 1;
BA_ "GenSigSendType" SG_ 2156331008 HVDpltnMdMxCnfdcRg 12;
BA_ "GenSigSendOnInit" SG_ 2156331008 HVDpltnMdMxCnfdcRg 1;
BA_ "VNSigInfotainment" SG_ 2156331008 HVDpltnMdMxCnfdcRg 1;
BA_ "SignalType" SG_ 2156331008 HVDpltnMdMxCnfdcRg "UNM";
BA_ "SignalLongName" SG_ 2156331008 HVDpltnMdMxCnfdcRg "High Voltage Depletion Mode Maximum Confidence Range";
BA_ "VNSigAllNodes" SG_ 2156331008 HVDpltnMdMxCnfdcRg 1;
BA_ "GenSigSendType" SG_ 2151776256 RCTALIC_Indctr1Act 10;
BA_ "SignalType" SG_ 2151776256 RCTALIC_Indctr1Act "BLN";
BA_ "PacketOrder" SG_ 2151776256 RCTALIC_Indctr1Act 1;
BA_ "SignalLongName" SG_ 2151776256 RCTALIC_Indctr1Act "Rear Cross Traffic Alert Left Indication Control : Indicator 1 Active";
BA_ "VNSigAllNodes" SG_ 2151776256 RCTALIC_Indctr1Act 1;
BA_ "GenSigSendType" SG_ 2151776256 RCTALIC_IndReq 10;
BA_ "SignalType" SG_ 2151776256 RCTALIC_IndReq "ENM";
BA_ "PacketOrder" SG_ 2151776256 RCTALIC_IndReq 2;
BA_ "SignalLongName" SG_ 2151776256 RCTALIC_IndReq "Rear Cross Traffic Alert Left Indication Control : Indication Request";
BA_ "VNSigAllNodes" SG_ 2151776256 RCTALIC_IndReq 1;
BA_ "GenSigDeltaValue" SG_ 2151776256 RrCTfcLHptcStRqSeqN 1;
BA_ "GenSigSendType" SG_ 2151776256 RrCTfcLHptcStRqSeqN 12;
BA_ "SignalType" SG_ 2151776256 RrCTfcLHptcStRqSeqN "UNM";
BA_ "SignalLongName" SG_ 2151776256 RrCTfcLHptcStRqSeqN "Rear Cross Traffic Alert Left Haptic Seat Request Sequence Number";
BA_ "VNSigAllNodes" SG_ 2151776256 RrCTfcLHptcStRqSeqN 1;
BA_ "GenSigDeltaValue" SG_ 2151776256 RrCTfcLHptcStReq 1;
BA_ "GenSigSendType" SG_ 2151776256 RrCTfcLHptcStReq 12;
BA_ "SignalType" SG_ 2151776256 RrCTfcLHptcStReq "UNM";
BA_ "SignalLongName" SG_ 2151776256 RrCTfcLHptcStReq "Rear Cross Traffic Alert Left Haptic Seat Request";
BA_ "VNSigAllNodes" SG_ 2151776256 RrCTfcLHptcStReq 1;
BA_ "GenSigSendType" SG_ 2154774528 LtRtHnTrGPSCsStAvl 10;
BA_ "GenSigSendOnInit" SG_ 2154774528 LtRtHnTrGPSCsStAvl 2;
BA_ "SignalType" SG_ 2154774528 LtRtHnTrGPSCsStAvl "BLN";
BA_ "SignalLongName" SG_ 2154774528 LtRtHnTrGPSCsStAvl "Left Right Hand Traffic With GPS Customization Setting Available";
BA_ "VNSigAllNodes" SG_ 2154774528 LtRtHnTrGPSCsStAvl 1;
BA_ "GenSigSendType" SG_ 2154774528 LtRtHnTrGPCsCrStVal 10;
BA_ "GenSigSendOnInit" SG_ 2154774528 LtRtHnTrGPCsCrStVal 2;
BA_ "SignalType" SG_ 2154774528 LtRtHnTrGPCsCrStVal "ENM";
BA_ "SignalLongName" SG_ 2154774528 LtRtHnTrGPCsCrStVal "Left Right Hand Traffic With GPS Customization Current Setting Value";
BA_ "VNSigAllNodes" SG_ 2154774528 LtRtHnTrGPCsCrStVal 1;
BA_ "GenSigSendType" SG_ 2154774528 LtRtHnTrCstStVal 10;
BA_ "GenSigSendOnInit" SG_ 2154774528 LtRtHnTrCstStVal 2;
BA_ "SignalType" SG_ 2154774528 LtRtHnTrCstStVal "ENM";
BA_ "SignalLongName" SG_ 2154774528 LtRtHnTrCstStVal "Left Right Hand Traffic Customization Current Setting Value";
BA_ "VNSigAllNodes" SG_ 2154774528 LtRtHnTrCstStVal 1;
BA_ "GenSigSendType" SG_ 2154774528 LtRtHnTrCstStAvail 10;
BA_ "GenSigSendOnInit" SG_ 2154774528 LtRtHnTrCstStAvail 2;
BA_ "SignalType" SG_ 2154774528 LtRtHnTrCstStAvail "ENM";
BA_ "SignalLongName" SG_ 2154774528 LtRtHnTrCstStAvail "Left Right Hand Traffic Customization Setting Available";
BA_ "VNSigAllNodes" SG_ 2154774528 LtRtHnTrCstStAvail 1;
BA_ "GenSigSendType" SG_ 2150375424 HVBChrgOvrdBtnDspReq 10;
BA_ "VNSigInfotainment" SG_ 2150375424 HVBChrgOvrdBtnDspReq 1;
BA_ "SignalType" SG_ 2150375424 HVBChrgOvrdBtnDspReq "ENM";
BA_ "SignalLongName" SG_ 2150375424 HVBChrgOvrdBtnDspReq "High Voltage Battery Charge Override Button Display Request";
BA_ "VNSigAllNodes" SG_ 2150375424 HVBChrgOvrdBtnDspReq 1;
BA_ "GenSigSendType" SG_ 2150375424 HVBChrgLmtBtnDspReq 10;
BA_ "VNSigInfotainment" SG_ 2150375424 HVBChrgLmtBtnDspReq 1;
BA_ "SignalType" SG_ 2150375424 HVBChrgLmtBtnDspReq "ENM";
BA_ "SignalLongName" SG_ 2150375424 HVBChrgLmtBtnDspReq "High Voltage Battery Charge Limit Button Display Request";
BA_ "VNSigAllNodes" SG_ 2150375424 HVBChrgLmtBtnDspReq 1;
BA_ "GenSigSendType" SG_ 2150375424 HVBHmChrgTmDspReq 10;
BA_ "VNSigInfotainment" SG_ 2150375424 HVBHmChrgTmDspReq 1;
BA_ "SignalType" SG_ 2150375424 HVBHmChrgTmDspReq "ENM";
BA_ "SignalLongName" SG_ 2150375424 HVBHmChrgTmDspReq "High Voltage Battery Home Charge Time Display Request";
BA_ "VNSigAllNodes" SG_ 2150375424 HVBHmChrgTmDspReq 1;
BA_ "GenSigSendType" SG_ 2150375424 HVBChrgTmDspReq 10;
BA_ "VNSigInfotainment" SG_ 2150375424 HVBChrgTmDspReq 1;
BA_ "SignalType" SG_ 2150375424 HVBChrgTmDspReq "ENM";
BA_ "SignalLongName" SG_ 2150375424 HVBChrgTmDspReq "High Voltage Battery Charge Time Display Request";
BA_ "VNSigAllNodes" SG_ 2150375424 HVBChrgTmDspReq 1;
BA_ "GenSigSendType" SG_ 2150375424 LBCCsStReq 10;
BA_ "VNSigInfotainment" SG_ 2150375424 LBCCsStReq 1;
BA_ "SignalType" SG_ 2150375424 LBCCsStReq "ENM";
BA_ "SignalLongName" SG_ 2150375424 LBCCsStReq "Location Based Charging Customization Setting Request";
BA_ "VNSigAllNodes" SG_ 2150375424 LBCCsStReq 1;
BA_ "GenSigSendType" SG_ 2150375424 LBCPosMdfcReq 10;
BA_ "VNSigInfotainment" SG_ 2150375424 LBCPosMdfcReq 1;
BA_ "SignalType" SG_ 2150375424 LBCPosMdfcReq "ENM";
BA_ "SignalLongName" SG_ 2150375424 LBCPosMdfcReq "Location Based Charging Position Modification Request";
BA_ "VNSigAllNodes" SG_ 2150375424 LBCPosMdfcReq 1;
BA_ "GenSigSendType" SG_ 2150375424 LBCCDRR_ClrStrdPosReq 10;
BA_ "VNSigInfotainment" SG_ 2150375424 LBCCDRR_ClrStrdPosReq 1;
BA_ "SignalType" SG_ 2150375424 LBCCDRR_ClrStrdPosReq "ENM";
BA_ "PacketOrder" SG_ 2150375424 LBCCDRR_ClrStrdPosReq 1;
BA_ "SignalLongName" SG_ 2150375424 LBCCDRR_ClrStrdPosReq "Location Based Charging Customer Data Reset Request : Clear Stored Position Request";
BA_ "VNSigAllNodes" SG_ 2150375424 LBCCDRR_ClrStrdPosReq 1;
BA_ "GenSigSendType" SG_ 2150375424 LBCCDRR_PosNum 10;
BA_ "VNSigInfotainment" SG_ 2150375424 LBCCDRR_PosNum 1;
BA_ "SignalType" SG_ 2150375424 LBCCDRR_PosNum "ENM";
BA_ "PacketOrder" SG_ 2150375424 LBCCDRR_PosNum 2;
BA_ "SignalLongName" SG_ 2150375424 LBCCDRR_PosNum "Location Based Charging Customer Data Reset Request : Position Number";
BA_ "VNSigAllNodes" SG_ 2150375424 LBCCDRR_PosNum 1;
BA_ "GenSigSendType" SG_ 2150375424 USBProgInPrgrs 10;
BA_ "SignalType" SG_ 2150375424 USBProgInPrgrs "BLN";
BA_ "SignalLongName" SG_ 2150375424 USBProgInPrgrs "USB Programming In Progress";
BA_ "VNSigAllNodes" SG_ 2150375424 USBProgInPrgrs 1;
BA_ "GenSigSendType" SG_ 2150375424 EngyCnsHistGrphRstRq 10;
BA_ "VNSigInfotainment" SG_ 2150375424 EngyCnsHistGrphRstRq 1;
BA_ "SignalType" SG_ 2150375424 EngyCnsHistGrphRstRq "BLN";
BA_ "SignalLongName" SG_ 2150375424 EngyCnsHistGrphRstRq "Energy Consumption History Graph Reset Requested";
BA_ "VNSigAllNodes" SG_ 2150375424 EngyCnsHistGrphRstRq 1;
BA_ "GenSigSendType" SG_ 2150375424 DsplTrnsShftLvrLckRqd 10;
BA_ "SignalType" SG_ 2150375424 DsplTrnsShftLvrLckRqd "BLN";
BA_ "SignalLongName" SG_ 2150375424 DsplTrnsShftLvrLckRqd "Displays Transmission Shift Lever Lock Requested";
BA_ "VNSigAllNodes" SG_ 2150375424 DsplTrnsShftLvrLckRqd 1;
BA_ "GenSigSendType" SG_ 2150375424 EngAstHtPlgInCstStRq 10;
BA_ "VNSigInfotainment" SG_ 2150375424 EngAstHtPlgInCstStRq 1;
BA_ "SignalType" SG_ 2150375424 EngAstHtPlgInCstStRq "ENM";
BA_ "SignalLongName" SG_ 2150375424 EngAstHtPlgInCstStRq "Engine Assisted Heating Plugged-In Customization Setting Request";
BA_ "VNSigAllNodes" SG_ 2150375424 EngAstHtPlgInCstStRq 1;
BA_ "GenSigSendType" SG_ 2150375424 EngAstHtCstStRq 10;
BA_ "VNSigInfotainment" SG_ 2150375424 EngAstHtCstStRq 1;
BA_ "SignalType" SG_ 2150375424 EngAstHtCstStRq "ENM";
BA_ "SignalLongName" SG_ 2150375424 EngAstHtCstStRq "Engine Assisted Heating Customization Setting Request";
BA_ "VNSigAllNodes" SG_ 2150375424 EngAstHtCstStRq 1;
BA_ "GenSigSendType" SG_ 2150375424 MntnceMdStEngRq 10;
BA_ "GenSigSendOnInit" SG_ 2150375424 MntnceMdStEngRq 2;
BA_ "VNSigInfotainment" SG_ 2150375424 MntnceMdStEngRq 1;
BA_ "SignalType" SG_ 2150375424 MntnceMdStEngRq "BLN";
BA_ "SignalLongName" SG_ 2150375424 MntnceMdStEngRq "Maintenance Mode Start Engine Request";
BA_ "VNSigAllNodes" SG_ 2150375424 MntnceMdStEngRq 1;
BA_ "GenSigSendType" SG_ 2150383616 LssOfPrplsnIO 10;
BA_ "SignalType" SG_ 2150383616 LssOfPrplsnIO "BLN";
BA_ "SignalLongName" SG_ 2150383616 LssOfPrplsnIO "Loss of Propulsion Indication On";
BA_ "VNSigAllNodes" SG_ 2150383616 LssOfPrplsnIO 1;
BA_ "GenSigDeltaValue" SG_ 2150383616 EngMntncePrcntCpl 1;
BA_ "GenSigSendType" SG_ 2150383616 EngMntncePrcntCpl 12;
BA_ "SignalType" SG_ 2150383616 EngMntncePrcntCpl "UNM";
BA_ "SignalLongName" SG_ 2150383616 EngMntncePrcntCpl "Engine Maintenance Percent Complete";
BA_ "VNSigAllNodes" SG_ 2150383616 EngMntncePrcntCpl 1;
BA_ "GenSigSendType" SG_ 2150383616 EngMntnceMdAct 10;
BA_ "SignalType" SG_ 2150383616 EngMntnceMdAct "BLN";
BA_ "SignalLongName" SG_ 2150383616 EngMntnceMdAct "Engine Maintenance Mode Active";
BA_ "VNSigAllNodes" SG_ 2150383616 EngMntnceMdAct 1;
BA_ "GenSigDeltaValue" SG_ 2150383616 BatPrpDspPwrLvlPct 1;
BA_ "GenSigSendType" SG_ 2150383616 BatPrpDspPwrLvlPct 12;
BA_ "SignalType" SG_ 2150383616 BatPrpDspPwrLvlPct "SNM";
BA_ "SignalLongName" SG_ 2150383616 BatPrpDspPwrLvlPct "Battery Propulsion Display Power Level Percent";
BA_ "VNSigAllNodes" SG_ 2150383616 BatPrpDspPwrLvlPct 1;
BA_ "GenSigDeltaValue" SG_ 2150383616 PrpDspTtlPwr 1;
BA_ "GenSigSendType" SG_ 2150383616 PrpDspTtlPwr 12;
BA_ "VNSigInfotainment" SG_ 2150383616 PrpDspTtlPwr 1;
BA_ "SignalType" SG_ 2150383616 PrpDspTtlPwr "UNM";
BA_ "SignalLongName" SG_ 2150383616 PrpDspTtlPwr "Propulsion Display Total Power";
BA_ "VNSigAllNodes" SG_ 2150383616 PrpDspTtlPwr 1;
BA_ "GenSigDeltaValue" SG_ 2150383616 PrpCapDspOpPs 1;
BA_ "GenSigSendType" SG_ 2150383616 PrpCapDspOpPs 12;
BA_ "VNSigInfotainment" SG_ 2150383616 PrpCapDspOpPs 1;
BA_ "SignalType" SG_ 2150383616 PrpCapDspOpPs "UNM";
BA_ "SignalLongName" SG_ 2150383616 PrpCapDspOpPs "Propulsion Capability Display Operating Position";
BA_ "VNSigAllNodes" SG_ 2150383616 PrpCapDspOpPs 1;
BA_ "GenSigDeltaValue" SG_ 2150383616 EstElecPrpCap 1;
BA_ "GenSigSendType" SG_ 2150383616 EstElecPrpCap 12;
BA_ "SignalType" SG_ 2150383616 EstElecPrpCap "UNM";
BA_ "SignalLongName" SG_ 2150383616 EstElecPrpCap "Estimated Electrical Propulsion Capability";
BA_ "VNSigAllNodes" SG_ 2150383616 EstElecPrpCap 1;
BA_ "GenSigDeltaValue" SG_ 2150383616 EngPrpDspPwrLvlPct 1;
BA_ "GenSigSendType" SG_ 2150383616 EngPrpDspPwrLvlPct 12;
BA_ "VNSigInfotainment" SG_ 2150383616 EngPrpDspPwrLvlPct 1;
BA_ "SignalType" SG_ 2150383616 EngPrpDspPwrLvlPct "UNM";
BA_ "SignalLongName" SG_ 2150383616 EngPrpDspPwrLvlPct "Engine Propulsion Display Power Level Percent";
BA_ "VNSigAllNodes" SG_ 2150383616 EngPrpDspPwrLvlPct 1;
BA_ "GenSigSendType" SG_ 2150383616 MntnceMdDsplyRq 10;
BA_ "GenSigSendOnInit" SG_ 2150383616 MntnceMdDsplyRq 1;
BA_ "VNSigInfotainment" SG_ 2150383616 MntnceMdDsplyRq 1;
BA_ "SignalType" SG_ 2150383616 MntnceMdDsplyRq "ENM";
BA_ "SignalLongName" SG_ 2150383616 MntnceMdDsplyRq "Maintenance Mode Display Request";
BA_ "VNSigAllNodes" SG_ 2150383616 MntnceMdDsplyRq 1;
BA_ "GenSigDeltaValue" SG_ 2151981056 DrvCyclBatPropRat 1;
BA_ "GenSigSendType" SG_ 2151981056 DrvCyclBatPropRat 12;
BA_ "GenSigSendOnInit" SG_ 2151981056 DrvCyclBatPropRat 1;
BA_ "VNSigInfotainment" SG_ 2151981056 DrvCyclBatPropRat 1;
BA_ "SignalType" SG_ 2151981056 DrvCyclBatPropRat "UNM";
BA_ "SignalLongName" SG_ 2151981056 DrvCyclBatPropRat "Drive Cycle Battery Propulsion Ratio";
BA_ "VNSigAllNodes" SG_ 2151981056 DrvCyclBatPropRat 1;
BA_ "GenSigDeltaValue" SG_ 2151981056 DTD_FuelPrpDstTrvld 1;
BA_ "GenSigSendType" SG_ 2151981056 DTD_FuelPrpDstTrvld 12;
BA_ "GenSigSendOnInit" SG_ 2151981056 DTD_FuelPrpDstTrvld 1;
BA_ "VNSigInfotainment" SG_ 2151981056 DTD_FuelPrpDstTrvld 1;
BA_ "SignalType" SG_ 2151981056 DTD_FuelPrpDstTrvld "UNM";
BA_ "PacketOrder" SG_ 2151981056 DTD_FuelPrpDstTrvld 2;
BA_ "SignalLongName" SG_ 2151981056 DTD_FuelPrpDstTrvld "Distance Traveled Data : Fuel Propulsion Distance Traveled";
BA_ "VNSigAllNodes" SG_ 2151981056 DTD_FuelPrpDstTrvld 1;
BA_ "GenSigDeltaValue" SG_ 2151981056 DTD_DrvCyclDstTrvld 1;
BA_ "GenSigSendType" SG_ 2151981056 DTD_DrvCyclDstTrvld 12;
BA_ "GenSigSendOnInit" SG_ 2151981056 DTD_DrvCyclDstTrvld 1;
BA_ "VNSigInfotainment" SG_ 2151981056 DTD_DrvCyclDstTrvld 1;
BA_ "SignalType" SG_ 2151981056 DTD_DrvCyclDstTrvld "UNM";
BA_ "PacketOrder" SG_ 2151981056 DTD_DrvCyclDstTrvld 3;
BA_ "SignalLongName" SG_ 2151981056 DTD_DrvCyclDstTrvld "Distance Traveled Data : Drive Cycle Distance Traveled";
BA_ "VNSigAllNodes" SG_ 2151981056 DTD_DrvCyclDstTrvld 1;
BA_ "GenSigDeltaValue" SG_ 2151981056 DTD_BattPrpDstTrvld 1;
BA_ "GenSigSendType" SG_ 2151981056 DTD_BattPrpDstTrvld 12;
BA_ "GenSigSendOnInit" SG_ 2151981056 DTD_BattPrpDstTrvld 1;
BA_ "VNSigInfotainment" SG_ 2151981056 DTD_BattPrpDstTrvld 1;
BA_ "SignalType" SG_ 2151981056 DTD_BattPrpDstTrvld "UNM";
BA_ "PacketOrder" SG_ 2151981056 DTD_BattPrpDstTrvld 1;
BA_ "SignalLongName" SG_ 2151981056 DTD_BattPrpDstTrvld "Distance Traveled Data : Battery Propulsion Distance Traveled";
BA_ "VNSigAllNodes" SG_ 2151981056 DTD_BattPrpDstTrvld 1;
BA_ "GenSigDeltaValue" SG_ 2151964672 DrvCyclTtlEnrgEfncy 1;
BA_ "GenSigSendType" SG_ 2151964672 DrvCyclTtlEnrgEfncy 12;
BA_ "GenSigSendOnInit" SG_ 2151964672 DrvCyclTtlEnrgEfncy 1;
BA_ "VNSigInfotainment" SG_ 2151964672 DrvCyclTtlEnrgEfncy 1;
BA_ "SignalType" SG_ 2151964672 DrvCyclTtlEnrgEfncy "UNM";
BA_ "SignalLongName" SG_ 2151964672 DrvCyclTtlEnrgEfncy "Drive Cycle Total Energy Efficiency";
BA_ "VNSigAllNodes" SG_ 2151964672 DrvCyclTtlEnrgEfncy 1;
BA_ "GenSigDeltaValue" SG_ 2151964672 DrvCyclFuelUsd 1;
BA_ "GenSigSendType" SG_ 2151964672 DrvCyclFuelUsd 12;
BA_ "GenSigSendOnInit" SG_ 2151964672 DrvCyclFuelUsd 1;
BA_ "VNSigInfotainment" SG_ 2151964672 DrvCyclFuelUsd 1;
BA_ "SignalType" SG_ 2151964672 DrvCyclFuelUsd "UNM";
BA_ "SignalLongName" SG_ 2151964672 DrvCyclFuelUsd "Drive Cycle Fuel Used";
BA_ "VNSigAllNodes" SG_ 2151964672 DrvCyclFuelUsd 1;
BA_ "GenSigDeltaValue" SG_ 2151964672 DrvCyclFuelEnmy 1;
BA_ "GenSigSendType" SG_ 2151964672 DrvCyclFuelEnmy 12;
BA_ "GenSigSendOnInit" SG_ 2151964672 DrvCyclFuelEnmy 1;
BA_ "VNSigInfotainment" SG_ 2151964672 DrvCyclFuelEnmy 1;
BA_ "SignalType" SG_ 2151964672 DrvCyclFuelEnmy "UNM";
BA_ "SignalLongName" SG_ 2151964672 DrvCyclFuelEnmy "Drive Cycle Fuel Economy";
BA_ "VNSigAllNodes" SG_ 2151964672 DrvCyclFuelEnmy 1;
BA_ "GenSigDeltaValue" SG_ 2151964672 DrvCyclDrvStEnrgEfncy 1;
BA_ "GenSigSendType" SG_ 2151964672 DrvCyclDrvStEnrgEfncy 12;
BA_ "GenSigSendOnInit" SG_ 2151964672 DrvCyclDrvStEnrgEfncy 1;
BA_ "VNSigInfotainment" SG_ 2151964672 DrvCyclDrvStEnrgEfncy 1;
BA_ "SignalType" SG_ 2151964672 DrvCyclDrvStEnrgEfncy "UNM";
BA_ "SignalLongName" SG_ 2151964672 DrvCyclDrvStEnrgEfncy "Drive Cycle Driving Style Energy Efficiency";
BA_ "VNSigAllNodes" SG_ 2151964672 DrvCyclDrvStEnrgEfncy 1;
BA_ "GenSigDeltaValue" SG_ 2151964672 DrvCyclCbnCondEnrgEfncy 1;
BA_ "GenSigSendType" SG_ 2151964672 DrvCyclCbnCondEnrgEfncy 12;
BA_ "GenSigSendOnInit" SG_ 2151964672 DrvCyclCbnCondEnrgEfncy 1;
BA_ "VNSigInfotainment" SG_ 2151964672 DrvCyclCbnCondEnrgEfncy 1;
BA_ "SignalType" SG_ 2151964672 DrvCyclCbnCondEnrgEfncy "UNM";
BA_ "SignalLongName" SG_ 2151964672 DrvCyclCbnCondEnrgEfncy "Drive Cycle Cabin Conditioning Energy Efficiency";
BA_ "VNSigAllNodes" SG_ 2151964672 DrvCyclCbnCondEnrgEfncy 1;
BA_ "GenSigDeltaValue" SG_ 2151964672 DrvCyclBatCondEnrgEfncy 1;
BA_ "GenSigSendType" SG_ 2151964672 DrvCyclBatCondEnrgEfncy 12;
BA_ "GenSigSendOnInit" SG_ 2151964672 DrvCyclBatCondEnrgEfncy 1;
BA_ "VNSigInfotainment" SG_ 2151964672 DrvCyclBatCondEnrgEfncy 1;
BA_ "SignalType" SG_ 2151964672 DrvCyclBatCondEnrgEfncy "UNM";
BA_ "SignalLongName" SG_ 2151964672 DrvCyclBatCondEnrgEfncy "Drive Cycle Battery Conditioning Energy Efficiency";
BA_ "VNSigAllNodes" SG_ 2151964672 DrvCyclBatCondEnrgEfncy 1;
BA_REL_ "GenSigSuprvResp" BU_SG_REL_ IPC_LS SG_ 2151464960 V2VWrngIndReq 1;
BA_REL_ "GenSigSuprvResp" BU_SG_REL_ IPC_LS SG_ 2151464960 V2VWrngDistRemng 1;
BA_REL_ "GenSigSuprvResp" BU_SG_REL_ IPC_LS SG_ 2151464960 V2VWrngDirctn 1;
BA_REL_ "GenSigSuprvResp" BU_SG_REL_ MSM_P_LS SG_ 2151448576 V2VSyRghtHptStVbRqSN 1;
BA_REL_ "GenSigSuprvResp" BU_SG_REL_ MSM_LS SG_ 2151448576 V2VSyRghtHptStVbRqSN 1;
BA_REL_ "GenSigSuprvResp" BU_SG_REL_ MSM_P_LS SG_ 2151448576 V2VSyRghtHptStVbRq 1;
BA_REL_ "GenSigSuprvResp" BU_SG_REL_ MSM_LS SG_ 2151448576 V2VSyRghtHptStVbRq 1;
BA_REL_ "GenSigSuprvResp" BU_SG_REL_ MSM_P_LS SG_ 2151448576 V2VSyLftHptStVbRqSN 1;
BA_REL_ "GenSigSuprvResp" BU_SG_REL_ MSM_LS SG_ 2151448576 V2VSyLftHptStVbRqSN 1;
BA_REL_ "GenSigSuprvResp" BU_SG_REL_ MSM_P_LS SG_ 2151448576 V2VSyLftHptStVbRq 1;
BA_REL_ "GenSigSuprvResp" BU_SG_REL_ MSM_LS SG_ 2151448576 V2VSyLftHptStVbRq 1;
BA_REL_ "GenSigSuprvResp" BU_SG_REL_ MSM_P_LS SG_ 2151448576 V2VSysHptStVibRqSN 1;
BA_REL_ "GenSigSuprvResp" BU_SG_REL_ MSM_LS SG_ 2151448576 V2VSysHptStVibRqSN 1;
BA_REL_ "GenSigSuprvResp" BU_SG_REL_ MSM_P_LS SG_ 2151448576 V2VSysHptcStVibReq 1;
BA_REL_ "GenSigSuprvResp" BU_SG_REL_ MSM_LS SG_ 2151448576 V2VSysHptcStVibReq 1;
BA_REL_ "GenSigSuprvResp" BU_SG_REL_ CGM_LS SG_ 2153930752 LCWrnIndReq 1;
BA_REL_ "GenSigSuprvResp" BU_SG_REL_ IPC_LS SG_ 2153930752 LCWrnIndReq 1;
BA_REL_ "GenSigSuprvResp" BU_SG_REL_ CGM_LS SG_ 2153930752 LCCDrvrAwrnsIO 1;
BA_REL_ "GenSigSuprvResp" BU_SG_REL_ IPC_LS SG_ 2153930752 LCCDrvrAwrnsIO 1;
BA_REL_ "GenSigSuprvResp" BU_SG_REL_ CGM_LS SG_ 2153930752 LCConvMsgIndreq 1;
BA_REL_ "GenSigSuprvResp" BU_SG_REL_ IPC_LS SG_ 2153930752 LCConvMsgIndreq 1;
BA_REL_ "GenSigSuprvResp" BU_SG_REL_ CGM_LS SG_ 2153930752 LCCIndReq 1;
BA_REL_ "GenSigSuprvResp" BU_SG_REL_ IPC_LS SG_ 2153930752 LCCIndReq 1;
BA_REL_ "GenSigSuprvResp" BU_SG_REL_ IPC_LS SG_ 2153930752 LnCntrngCtlIcnLoctn 1;
BA_REL_ "GenSigSuprvResp" BU_SG_REL_ CGM_LS SG_ 2153889792 LCArrwBlk5Offst 1;
BA_REL_ "GenSigSuprvResp" BU_SG_REL_ IPC_LS SG_ 2153889792 LCArrwBlk5Offst 1;
BA_REL_ "GenSigSuprvResp" BU_SG_REL_ CGM_LS SG_ 2153889792 LCArrwBlk5Act 1;
BA_REL_ "GenSigSuprvResp" BU_SG_REL_ IPC_LS SG_ 2153889792 LCArrwBlk5Act 1;
BA_REL_ "GenSigSuprvResp" BU_SG_REL_ CGM_LS SG_ 2153889792 LCArrwBlk4Offst 1;
BA_REL_ "GenSigSuprvResp" BU_SG_REL_ IPC_LS SG_ 2153889792 LCArrwBlk4Offst 1;
BA_REL_ "GenSigSuprvResp" BU_SG_REL_ CGM_LS SG_ 2153889792 LCArrwBlk4Act 1;
BA_REL_ "GenSigSuprvResp" BU_SG_REL_ IPC_LS SG_ 2153889792 LCArrwBlk4Act 1;
BA_REL_ "GenSigSuprvResp" BU_SG_REL_ CGM_LS SG_ 2153889792 LCArrwBlk3Offst 1;
BA_REL_ "GenSigSuprvResp" BU_SG_REL_ IPC_LS SG_ 2153889792 LCArrwBlk3Offst 1;
BA_REL_ "GenSigSuprvResp" BU_SG_REL_ CGM_LS SG_ 2153889792 LCArrwBlk3Act 1;
BA_REL_ "GenSigSuprvResp" BU_SG_REL_ IPC_LS SG_ 2153889792 LCArrwBlk3Act 1;
BA_REL_ "GenSigSuprvResp" BU_SG_REL_ CGM_LS SG_ 2153889792 LCArrwBlk2Offst 1;
BA_REL_ "GenSigSuprvResp" BU_SG_REL_ IPC_LS SG_ 2153889792 LCArrwBlk2Offst 1;
BA_REL_ "GenSigSuprvResp" BU_SG_REL_ CGM_LS SG_ 2153889792 LCArrwBlk2Act 1;
BA_REL_ "GenSigSuprvResp" BU_SG_REL_ IPC_LS SG_ 2153889792 LCArrwBlk2Act 1;
BA_REL_ "GenSigSuprvResp" BU_SG_REL_ CGM_LS SG_ 2153889792 LCArrwBlk1Act 1;
BA_REL_ "GenSigSuprvResp" BU_SG_REL_ IPC_LS SG_ 2153889792 LCArrwBlk1Act 1;
BA_REL_ "GenSigSuprvResp" BU_SG_REL_ CSM_LS SG_ 2153914368 EUSS_TrEgUgScrMxScVal 1;
BA_REL_ "GenSigSuprvResp" BU_SG_REL_ RadioHead_LS SG_ 2153914368 EUSS_TrEgUgScrMxScVal 1;
BA_REL_ "GenSigSuprvResp" BU_SG_REL_ CSM_LS SG_ 2153914368 EUSS_TrEgUgScrMnScVal 1;
BA_REL_ "GenSigSuprvResp" BU_SG_REL_ RadioHead_LS SG_ 2153914368 EUSS_TrEgUgScrMnScVal 1;
BA_REL_ "GenSigSuprvResp" BU_SG_REL_ CSM_LS SG_ 2153914368 EUSS_TcEgUgScrMxScVal 1;
BA_REL_ "GenSigSuprvResp" BU_SG_REL_ RadioHead_LS SG_ 2153914368 EUSS_TcEgUgScrMxScVal 1;
BA_REL_ "GenSigSuprvResp" BU_SG_REL_ CSM_LS SG_ 2153914368 EUSS_TcEgUgScrMnScVal 1;
BA_REL_ "GenSigSuprvResp" BU_SG_REL_ RadioHead_LS SG_ 2153914368 EUSS_TcEgUgScrMnScVal 1;
BA_REL_ "GenSigSuprvResp" BU_SG_REL_ CSM_LS SG_ 2153914368 EUSS_ITEgUgScrMxScVal 1;
BA_REL_ "GenSigSuprvResp" BU_SG_REL_ RadioHead_LS SG_ 2153914368 EUSS_ITEgUgScrMxScVal 1;
BA_REL_ "GenSigSuprvResp" BU_SG_REL_ CSM_LS SG_ 2153914368 EUSS_ITEgUgScrMnScVal 1;
BA_REL_ "GenSigSuprvResp" BU_SG_REL_ RadioHead_LS SG_ 2153914368 EUSS_ITEgUgScrMnScVal 1;
BA_REL_ "GenSigSuprvResp" BU_SG_REL_ CSM_LS SG_ 2153914368 EUSS_OTEgUgScrMxScVal 1;
BA_REL_ "GenSigSuprvResp" BU_SG_REL_ RadioHead_LS SG_ 2153914368 EUSS_OTEgUgScrMxScVal 1;
BA_REL_ "GenSigSuprvResp" BU_SG_REL_ CSM_LS SG_ 2153914368 EUSS_OTEgUgScrMnScVal 1;
BA_REL_ "GenSigSuprvResp" BU_SG_REL_ RadioHead_LS SG_ 2153914368 EUSS_OTEgUgScrMnScVal 1;
BA_REL_ "GenSigSuprvResp" BU_SG_REL_ IPC_LS SG_ 2150580224 CstNonUsbSOCDspLvl 1;
BA_REL_ "GenSigSuprvResp" BU_SG_REL_ IPC_LS SG_ 2150580224 CstmrNonUsblSOC 1;
BA_REL_ "GenSigSuprvResp" BU_SG_REL_ IPC_LS SG_ 2150580224 PrpDspTtlPwrLvlPct 1;
BA_REL_ "GenSigSuprvResp" BU_SG_REL_ SBZA_R_LS SG_ 2151735296 RtSdDetSysServDsbld 1;
BA_REL_ "GenSigSuprvResp" BU_SG_REL_ SBZA_R_LS SG_ 2151735296 RtSdDetSysTmpDsbld 1;
BA_REL_ "GenSigSuprvResp" BU_SG_REL_ SBZA_R_LS SG_ 2151735296 RtLnChgAlrtEnbld 1;
BA_REL_ "GenSigSuprvResp" BU_SG_REL_ SBZA_R_LS SG_ 2151735296 RtSBZAlrtEnbld 1;
BA_REL_ "GenSigSuprvResp" BU_SG_REL_ SBZA_R_LS SG_ 2151735296 RtRrCrsTrfcAlrtEnbld 1;
BA_REL_ "GenSigSuprvResp" BU_SG_REL_ SBZA_R_LS SG_ 2151735296 LnChgAlrtOffIndOn 1;
BA_REL_ "GenSigSuprvResp" BU_SG_REL_ IPC_LS SG_ 2151735296 LnChgAlrtOffIndOn 1;
BA_REL_ "GenSigSuprvResp" BU_SG_REL_ SBZA_R_LS SG_ 2151735296 RrCrsTrfcAlrtOffIO 1;
BA_REL_ "GenSigSuprvResp" BU_SG_REL_ VPM_LS SG_ 2151792640 RCTARIC_Indctr1Act 1;
BA_REL_ "GenSigSuprvResp" BU_SG_REL_ VPM_LS SG_ 2151792640 RCTARIC_IndReq 1;
BA_REL_ "GenSigSuprvResp" BU_SG_REL_ VPM_LS SG_ 2151792640 RrCTfcRHptcStRqSqN 1;
BA_REL_ "GenSigSuprvResp" BU_SG_REL_ MSM_P_LS SG_ 2151792640 RrCTfcRHptcStRqSqN 1;
BA_REL_ "GenSigSuprvResp" BU_SG_REL_ MSM_LS SG_ 2151792640 RrCTfcRHptcStRqSqN 1;
BA_REL_ "GenSigSuprvResp" BU_SG_REL_ VPM_LS SG_ 2151792640 RrCTfcRHptcStReq 1;
BA_REL_ "GenSigSuprvResp" BU_SG_REL_ MSM_P_LS SG_ 2151792640 RrCTfcRHptcStReq 1;
BA_REL_ "GenSigSuprvResp" BU_SG_REL_ MSM_LS SG_ 2151792640 RrCTfcRHptcStReq 1;
BA_REL_ "GenSigSuprvResp" BU_SG_REL_ BCM_LS SG_ 2149826560 SpdLmtVsnFsdSpdUnt 1;
BA_REL_ "GenSigSuprvResp" BU_SG_REL_ BCM_LS SG_ 2149826560 SpdLmtVnFsSpdNwDet 1;
BA_REL_ "GenSigSuprvResp" BU_SG_REL_ BCM_LS SG_ 2149826560 SpdLmtVsnFsdSpd 1;
BA_REL_ "GenSigSuprvResp" BU_SG_REL_ IPC_LS SG_ 2149826560 SpdLmtVsnFsdSpd 1;
BA_REL_ "GenSigSuprvResp" BU_SG_REL_ BCM_LS SG_ 2149826560 FOAI_VehAhdIndRq11E 1;
BA_REL_ "GenSigSuprvResp" BU_SG_REL_ BCM_LS SG_ 2149826560 FOAI_AlrtWrnIndRq11E 1;
BA_REL_ "GenSigSuprvResp" BU_SG_REL_ BCM_LS SG_ 2149826560 FOAI_AlrtChmIhbRq11E 1;
BA_REL_ "GenSigSuprvResp" BU_SG_REL_ CHUD_LS SG_ 2149826560 FwdClnAlrtPr11E 1;
BA_REL_ "GenSigSuprvResp" BU_SG_REL_ HUD_LS SG_ 2149826560 FwdClnAlrtPr11E 1;
BA_REL_ "GenSigSuprvResp" BU_SG_REL_ UPA_LS SG_ 2149957632 PrkAstRrObjSnsngRqAct 1;
BA_REL_ "GenSigSuprvResp" BU_SG_REL_ APA_LS SG_ 2149957632 PrkAstRrObjSnsngRqAct 1;
BA_REL_ "GenSigSuprvResp" BU_SG_REL_ UPA_LS SG_ 2149957632 PrkAstOprtrDsrdStat 1;
BA_REL_ "GenSigSuprvResp" BU_SG_REL_ APA_LS SG_ 2149957632 PrkAstOprtrDsrdStat 1;
BA_REL_ "GenSigSuprvResp" BU_SG_REL_ UPA_LS SG_ 2149957632 PrkAstInhbtReq 1;
BA_REL_ "GenSigSuprvResp" BU_SG_REL_ APA_LS SG_ 2149957632 PrkAstInhbtReq 1;
BA_REL_ "GenSigSuprvResp" BU_SG_REL_ UPA_LS SG_ 2149957632 ClsnMtgtnInhbtd 1;
BA_REL_ "GenSigSuprvResp" BU_SG_REL_ APA_LS SG_ 2149957632 ClsnMtgtnInhbtd 1;
BA_REL_ "GenSigSuprvResp" BU_SG_REL_ EOCM2B_K2_LS SG_ 2149941248 PrkAstRrObjSnsngAct 1;
BA_REL_ "GenSigSuprvResp" BU_SG_REL_ EOCM2A_K2_LS SG_ 2149941248 PrkAstRrObjSnsngAct 1;
BA_REL_ "GenSigSuprvResp" BU_SG_REL_ EOCM_F_LS SG_ 2149941248 PrkAstRrObjSnsngAct 1;
BA_REL_ "GenSigSuprvResp" BU_SG_REL_ EOCM2B_K2_LS SG_ 2149941248 PrkAstRrSysStatUnfltd 1;
BA_REL_ "GenSigSuprvResp" BU_SG_REL_ EOCM2A_K2_LS SG_ 2149941248 PrkAstRrSysStatUnfltd 1;
BA_REL_ "GenSigSuprvResp" BU_SG_REL_ EOCM_F_LS SG_ 2149941248 PrkAstRrSysStatUnfltd 1;
BA_REL_ "GenSigSuprvResp" BU_SG_REL_ EOCM2B_K2_LS SG_ 2149941248 PrkAstRrExtdDstUnfltd 1;
BA_REL_ "GenSigSuprvResp" BU_SG_REL_ EOCM2A_K2_LS SG_ 2149941248 PrkAstRrExtdDstUnfltd 1;
BA_REL_ "GenSigSuprvResp" BU_SG_REL_ EOCM_F_LS SG_ 2149941248 PrkAstRrExtdDstUnfltd 1;
BA_REL_ "GenSigSuprvResp" BU_SG_REL_ EOCM2B_K2_LS SG_ 2149941248 PrkAstFntnSnsDstrbdIO 1;
BA_REL_ "GenSigSuprvResp" BU_SG_REL_ EOCM2A_K2_LS SG_ 2149941248 PrkAstFntnSnsDstrbdIO 1;
BA_REL_ "GenSigSuprvResp" BU_SG_REL_ EOCM_F_LS SG_ 2149941248 PrkAstFntnSnsDstrbdIO 1;
BA_REL_ "GenSigSuprvResp" BU_SG_REL_ EOCM2B_K2_LS SG_ 2149941248 PrkAstFntnSnrsBlkd 1;
BA_REL_ "GenSigSuprvResp" BU_SG_REL_ EOCM2A_K2_LS SG_ 2149941248 PrkAstFntnSnrsBlkd 1;
BA_REL_ "GenSigSuprvResp" BU_SG_REL_ EOCM_F_LS SG_ 2149941248 PrkAstFntnSnrsBlkd 1;
BA_REL_ "GenSigSuprvResp" BU_SG_REL_ EOCM2B_K2_LS SG_ 2149941248 PrkAstFntnFld 1;
BA_REL_ "GenSigSuprvResp" BU_SG_REL_ EOCM2A_K2_LS SG_ 2149941248 PrkAstFntnFld 1;
BA_REL_ "GenSigSuprvResp" BU_SG_REL_ EOCM_F_LS SG_ 2149941248 PrkAstFntnFld 1;
BA_REL_ "GenSigSuprvResp" BU_SG_REL_ EOCM2B_K2_LS SG_ 2149941248 PrkAstFntnDsbldIO 1;
BA_REL_ "GenSigSuprvResp" BU_SG_REL_ EOCM2A_K2_LS SG_ 2149941248 PrkAstFntnDsbldIO 1;
BA_REL_ "GenSigSuprvResp" BU_SG_REL_ EOCM_F_LS SG_ 2149941248 PrkAstFntnDsbldIO 1;
BA_REL_ "GenSigSuprvResp" BU_SG_REL_ EOCM2B_K2_LS SG_ 2149941248 PrkAstFntnClnPrkAstIO 1;
BA_REL_ "GenSigSuprvResp" BU_SG_REL_ EOCM2A_K2_LS SG_ 2149941248 PrkAstFntnClnPrkAstIO 1;
BA_REL_ "GenSigSuprvResp" BU_SG_REL_ EOCM_F_LS SG_ 2149941248 PrkAstFntnClnPrkAstIO 1;
BA_REL_ "GenSigSuprvResp" BU_SG_REL_ EOCM2B_K2_LS SG_ 2149941248 ClsnMtgtnInhbtReqtd 1;
BA_REL_ "GenSigSuprvResp" BU_SG_REL_ EOCM2A_K2_LS SG_ 2149941248 ClsnMtgtnInhbtReqtd 1;
BA_REL_ "GenSigSuprvResp" BU_SG_REL_ EOCM_F_LS SG_ 2149941248 ClsnMtgtnInhbtReqtd 1;
BA_REL_ "GenSigSuprvResp" BU_SG_REL_ EOCM2B_K2_LS SG_ 2149941248 PARrRgn4ObjStatUnfltd 1;
BA_REL_ "GenSigSuprvResp" BU_SG_REL_ EOCM2A_K2_LS SG_ 2149941248 PARrRgn4ObjStatUnfltd 1;
BA_REL_ "GenSigSuprvResp" BU_SG_REL_ EOCM_F_LS SG_ 2149941248 PARrRgn4ObjStatUnfltd 1;
BA_REL_ "GenSigSuprvResp" BU_SG_REL_ EOCM2B_K2_LS SG_ 2149941248 PARrRgn3ObjStatUnfltd 1;
BA_REL_ "GenSigSuprvResp" BU_SG_REL_ EOCM2A_K2_LS SG_ 2149941248 PARrRgn3ObjStatUnfltd 1;
BA_REL_ "GenSigSuprvResp" BU_SG_REL_ EOCM_F_LS SG_ 2149941248 PARrRgn3ObjStatUnfltd 1;
BA_REL_ "GenSigSuprvResp" BU_SG_REL_ EOCM2B_K2_LS SG_ 2149941248 PARrRgn2ObjStatUnfltd 1;
BA_REL_ "GenSigSuprvResp" BU_SG_REL_ EOCM2A_K2_LS SG_ 2149941248 PARrRgn2ObjStatUnfltd 1;
BA_REL_ "GenSigSuprvResp" BU_SG_REL_ EOCM_F_LS SG_ 2149941248 PARrRgn2ObjStatUnfltd 1;
BA_REL_ "GenSigSuprvResp" BU_SG_REL_ EOCM2B_K2_LS SG_ 2149941248 PARrRgn1ObjStatUnfltd 1;
BA_REL_ "GenSigSuprvResp" BU_SG_REL_ EOCM2A_K2_LS SG_ 2149941248 PARrRgn1ObjStatUnfltd 1;
BA_REL_ "GenSigSuprvResp" BU_SG_REL_ EOCM_F_LS SG_ 2149941248 PARrRgn1ObjStatUnfltd 1;
BA_REL_ "GenSigSuprvResp" BU_SG_REL_ IPC_LS SG_ 2156314624 OffBrdCSFltDtctd 1;
BA_REL_ "GenSigSuprvResp" BU_SG_REL_ BCM_LS SG_ 2156314624 OBVhCsACChgRqBnVs 1;
BA_REL_ "GenSigSuprvResp" BU_SG_REL_ CSM_LS SG_ 2156314624 OBVhCsACChgRqBnVs 1;
BA_REL_ "GenSigSuprvResp" BU_SG_REL_ RadioHead_LS SG_ 2156314624 OBVhCsACChgRqBnVs 1;
BA_REL_ "GenSigSuprvResp" BU_SG_REL_ BCM_LS SG_ 2156314624 TODCNPDT_Min 1;
BA_REL_ "GenSigSuprvResp" BU_SG_REL_ CSM_LS SG_ 2156314624 TODCNPDT_Min 1;
BA_REL_ "GenSigSuprvResp" BU_SG_REL_ RadioHead_LS SG_ 2156314624 TODCNPDT_Min 1;
BA_REL_ "GenSigSuprvResp" BU_SG_REL_ RadioHead_LS SG_ 2156314624 TODCNPDT_Min 1;
BA_REL_ "GenSigSuprvResp" BU_SG_REL_ BCM_LS SG_ 2156314624 TODCNPDT_Hr 1;
BA_REL_ "GenSigSuprvResp" BU_SG_REL_ CSM_LS SG_ 2156314624 TODCNPDT_Hr 1;
BA_REL_ "GenSigSuprvResp" BU_SG_REL_ RadioHead_LS SG_ 2156314624 TODCNPDT_Hr 1;
BA_REL_ "GenSigSuprvResp" BU_SG_REL_ RadioHead_LS SG_ 2156314624 TODCNPDT_Hr 1;
BA_REL_ "GenSigSuprvResp" BU_SG_REL_ BCM_LS SG_ 2156314624 TODCNPDT_DyOfWk 1;
BA_REL_ "GenSigSuprvResp" BU_SG_REL_ CSM_LS SG_ 2156314624 TODCNPDT_DyOfWk 1;
BA_REL_ "GenSigSuprvResp" BU_SG_REL_ RadioHead_LS SG_ 2156314624 TODCNPDT_DyOfWk 1;
BA_REL_ "GenSigSuprvResp" BU_SG_REL_ RadioHead_LS SG_ 2156314624 TODCNPDT_DyOfWk 1;
BA_REL_ "GenSigSuprvResp" BU_SG_REL_ CSM_LS SG_ 2156314624 HVBatBlkSOC 1;
BA_REL_ "GenSigSuprvResp" BU_SG_REL_ RadioHead_LS SG_ 2156314624 HVBatBlkSOC 1;
BA_REL_ "GenSigSuprvResp" BU_SG_REL_ IPC_LS SG_ 2156314624 HVBatBlkSOC 1;
BA_REL_ "GenSigSuprvResp" BU_SG_REL_ TCP_LS SG_ 2156314624 TODCOpMd 1;
BA_REL_ "GenSigSuprvResp" BU_SG_REL_ ONSTAR_LS SG_ 2156314624 TODCOpMd 1;
BA_REL_ "GenSigSuprvResp" BU_SG_REL_ BCM_LS SG_ 2156314624 TODCDMPTO_TpOvR 1;
BA_REL_ "GenSigSuprvResp" BU_SG_REL_ TCP_LS SG_ 2156314624 TODCDMPTO_TpOvR 1;
BA_REL_ "GenSigSuprvResp" BU_SG_REL_ ONSTAR_LS SG_ 2156314624 TODCDMPTO_TpOvR 1;
BA_REL_ "GenSigSuprvResp" BU_SG_REL_ CSM_LS SG_ 2156314624 TODCDMPTO_TpOvR 1;
BA_REL_ "GenSigSuprvResp" BU_SG_REL_ RadioHead_LS SG_ 2156314624 TODCDMPTO_TpOvR 1;
BA_REL_ "GenSigSuprvResp" BU_SG_REL_ RadioHead_LS SG_ 2156314624 TODCDMPTO_TpOvR 1;
BA_REL_ "GenSigSuprvResp" BU_SG_REL_ IPC_LS SG_ 2156314624 TODCDMPTO_TpOvR 1;
BA_REL_ "GenSigSuprvResp" BU_SG_REL_ BCM_LS SG_ 2156314624 TODCDMPTO_CmPgR 1;
BA_REL_ "GenSigSuprvResp" BU_SG_REL_ TCP_LS SG_ 2156314624 TODCDMPTO_CmPgR 1;
BA_REL_ "GenSigSuprvResp" BU_SG_REL_ ONSTAR_LS SG_ 2156314624 TODCDMPTO_CmPgR 1;
BA_REL_ "GenSigSuprvResp" BU_SG_REL_ CSM_LS SG_ 2156314624 TODCDMPTO_CmPgR 1;
BA_REL_ "GenSigSuprvResp" BU_SG_REL_ RadioHead_LS SG_ 2156314624 TODCDMPTO_CmPgR 1;
BA_REL_ "GenSigSuprvResp" BU_SG_REL_ RadioHead_LS SG_ 2156314624 TODCDMPTO_CmPgR 1;
BA_REL_ "GenSigSuprvResp" BU_SG_REL_ IPC_LS SG_ 2156314624 TODCDMPTO_CmPgR 1;
BA_REL_ "GenSigSuprvResp" BU_SG_REL_ BCM_LS SG_ 2156314624 HVChrgSysStNot 1;
BA_REL_ "GenSigSuprvResp" BU_SG_REL_ ONSTAR_LS SG_ 2156314624 HVChrgSysStNot 1;
BA_REL_ "GenSigSuprvResp" BU_SG_REL_ TCP_LS SG_ 2156314624 HVChrgAbrtRsn 1;
BA_REL_ "GenSigSuprvResp" BU_SG_REL_ ONSTAR_LS SG_ 2156314624 HVChrgAbrtRsn 1;
BA_REL_ "GenSigSuprvResp" BU_SG_REL_ BCM_LS SG_ 2156314624 HVCSCLPD_UsrIntTyp 1;
BA_REL_ "GenSigSuprvResp" BU_SG_REL_ CSM_LS SG_ 2156314624 HVCSCLPD_UsrIntTyp 1;
BA_REL_ "GenSigSuprvResp" BU_SG_REL_ RadioHead_LS SG_ 2156314624 HVCSCLPD_UsrIntTyp 1;
BA_REL_ "GenSigSuprvResp" BU_SG_REL_ RadioHead_LS SG_ 2156314624 HVCSCLPD_UsrIntTyp 1;
BA_REL_ "GenSigSuprvResp" BU_SG_REL_ BCM_LS SG_ 2156314624 HVCSCLPD_RdCrntLv3 1;
BA_REL_ "GenSigSuprvResp" BU_SG_REL_ CSM_LS SG_ 2156314624 HVCSCLPD_RdCrntLv3 1;
BA_REL_ "GenSigSuprvResp" BU_SG_REL_ RadioHead_LS SG_ 2156314624 HVCSCLPD_RdCrntLv3 1;
BA_REL_ "GenSigSuprvResp" BU_SG_REL_ RadioHead_LS SG_ 2156314624 HVCSCLPD_RdCrntLv3 1;
BA_REL_ "GenSigSuprvResp" BU_SG_REL_ BCM_LS SG_ 2156314624 HVCSCLPD_RdCrntLv2 1;
BA_REL_ "GenSigSuprvResp" BU_SG_REL_ CSM_LS SG_ 2156314624 HVCSCLPD_RdCrntLv2 1;
BA_REL_ "GenSigSuprvResp" BU_SG_REL_ RadioHead_LS SG_ 2156314624 HVCSCLPD_RdCrntLv2 1;
BA_REL_ "GenSigSuprvResp" BU_SG_REL_ RadioHead_LS SG_ 2156314624 HVCSCLPD_RdCrntLv2 1;
BA_REL_ "GenSigSuprvResp" BU_SG_REL_ BCM_LS SG_ 2156314624 HVCSCLPD_RdCrntLv1 1;
BA_REL_ "GenSigSuprvResp" BU_SG_REL_ CSM_LS SG_ 2156314624 HVCSCLPD_RdCrntLv1 1;
BA_REL_ "GenSigSuprvResp" BU_SG_REL_ RadioHead_LS SG_ 2156314624 HVCSCLPD_RdCrntLv1 1;
BA_REL_ "GenSigSuprvResp" BU_SG_REL_ RadioHead_LS SG_ 2156314624 HVCSCLPD_RdCrntLv1 1;
BA_REL_ "GenSigSuprvResp" BU_SG_REL_ BCM_LS SG_ 2156314624 HVCSCLPD_NrmChrgC 1;
BA_REL_ "GenSigSuprvResp" BU_SG_REL_ CSM_LS SG_ 2156314624 HVCSCLPD_NrmChrgC 1;
BA_REL_ "GenSigSuprvResp" BU_SG_REL_ RadioHead_LS SG_ 2156314624 HVCSCLPD_NrmChrgC 1;
BA_REL_ "GenSigSuprvResp" BU_SG_REL_ RadioHead_LS SG_ 2156314624 HVCSCLPD_NrmChrgC 1;
BA_REL_ "GenSigSuprvResp" BU_SG_REL_ BCM_LS SG_ 2156314624 HVCSCLPD_ChgLvlPfS 1;
BA_REL_ "GenSigSuprvResp" BU_SG_REL_ CSM_LS SG_ 2156314624 HVCSCLPD_ChgLvlPfS 1;
BA_REL_ "GenSigSuprvResp" BU_SG_REL_ RadioHead_LS SG_ 2156314624 HVCSCLPD_ChgLvlPfS 1;
BA_REL_ "GenSigSuprvResp" BU_SG_REL_ RadioHead_LS SG_ 2156314624 HVCSCLPD_ChgLvlPfS 1;
BA_REL_ "GenSigSuprvResp" BU_SG_REL_ IPC_LS SG_ 2150449152 ESPDrvrExtIO 1;
BA_REL_ "GenSigSuprvResp" BU_SG_REL_ IPC_LS SG_ 2150449152 ESPDrvrDrStIndtrmntIO 1;
BA_REL_ "GenSigSuprvResp" BU_SG_REL_ IPC_LS SG_ 2150449152 ESPAutoPrkIO 1;
BA_REL_ "GenSigSuprvResp" BU_SG_REL_ IPC_LS SG_ 2150449152 ManTransIndReq 1;
BA_REL_ "GenSigSuprvResp" BU_SG_REL_ IPC_LS SG_ 2150449152 SrvcFlSysPrkInOpnArIO 1;
BA_REL_ "GenSigSuprvResp" BU_SG_REL_ IPC_LS SG_ 2150449152 TnDrvStblCtrlOffUnbIO 1;
BA_REL_ "GenSigSuprvResp" BU_SG_REL_ IPC_LS SG_ 2150449152 TnDrvTrCtrlOffUnbIO 1;
BA_REL_ "GenSigSuprvResp" BU_SG_REL_ IPC_LS SG_ 2150449152 ASIRI_Indication08 1;
BA_REL_ "GenSigSuprvResp" BU_SG_REL_ IPC_LS SG_ 2150449152 ASIRI_Indication07 1;
BA_REL_ "GenSigSuprvResp" BU_SG_REL_ IPC_LS SG_ 2150449152 ASIRI_Indication06 1;
BA_REL_ "GenSigSuprvResp" BU_SG_REL_ IPC_LS SG_ 2150449152 ASIRI_Indication05 1;
BA_REL_ "GenSigSuprvResp" BU_SG_REL_ IPC_LS SG_ 2150449152 ASIRI_Indication04 1;
BA_REL_ "GenSigSuprvResp" BU_SG_REL_ IPC_LS SG_ 2150449152 ASIRI_Indication03 1;
BA_REL_ "GenSigSuprvResp" BU_SG_REL_ IPC_LS SG_ 2150449152 ASIRI_Indication02 1;
BA_REL_ "GenSigSuprvResp" BU_SG_REL_ IPC_LS SG_ 2150449152 ASIRI_Indication01 1;
BA_REL_ "GenSigSuprvResp" BU_SG_REL_ FCM_LS SG_ 2150449152 SpdLmtrSttngTypAct 1;
BA_REL_ "GenSigSuprvResp" BU_SG_REL_ VIS2_LS SG_ 2150449152 SpdLmtrSttngTypAct 1;
BA_REL_ "GenSigSuprvResp" BU_SG_REL_ IPC_LS SG_ 2150449152 SpdLmtrSttngTypAct 1;
BA_REL_ "GenSigSuprvResp" BU_SG_REL_ IPC_LS SG_ 2150449152 FuelSysNEmsRltMalfAct 1;
BA_REL_ "GenSigSuprvResp" BU_SG_REL_ IPC_LS SG_ 2150449152 InActFuelMdFuelLvlIO 1;
BA_REL_ "GenSigSuprvResp" BU_SG_REL_ MSM_P_LS SG_ 2149810176 FCAHptcStVbnRqSeqN 1;
BA_REL_ "GenSigSuprvResp" BU_SG_REL_ MSM_LS SG_ 2149810176 FCAHptcStVbnRqSeqN 1;
BA_REL_ "GenSigSuprvResp" BU_SG_REL_ MSM_P_LS SG_ 2149810176 FCAHptcStVbnReq 1;
BA_REL_ "GenSigSuprvResp" BU_SG_REL_ MSM_LS SG_ 2149810176 FCAHptcStVbnReq 1;
BA_REL_ "GenSigSuprvResp" BU_SG_REL_ IPC_LS SG_ 2149793792 AutoEmrgncyBrkDisbldIO 1;
BA_REL_ "GenSigSuprvResp" BU_SG_REL_ CSM_LS SG_ 2150080512 LBCVLS_VehGPSLctV 1;
BA_REL_ "GenSigSuprvResp" BU_SG_REL_ RadioHead_LS SG_ 2150080512 LBCVLS_VehGPSLctV 1;
BA_REL_ "GenSigSuprvResp" BU_SG_REL_ CSM_LS SG_ 2150080512 LBCVLS_VehGPSLct 1;
BA_REL_ "GenSigSuprvResp" BU_SG_REL_ RadioHead_LS SG_ 2150080512 LBCVLS_VehGPSLct 1;
BA_REL_ "GenSigSuprvResp" BU_SG_REL_ CSM_LS SG_ 2150080512 LBCCF_Lct4PosStrdIO 1;
BA_REL_ "GenSigSuprvResp" BU_SG_REL_ RadioHead_LS SG_ 2150080512 LBCCF_Lct4PosStrdIO 1;
BA_REL_ "GenSigSuprvResp" BU_SG_REL_ CSM_LS SG_ 2150080512 LBCCF_Lct3PosStrdIO 1;
BA_REL_ "GenSigSuprvResp" BU_SG_REL_ RadioHead_LS SG_ 2150080512 LBCCF_Lct3PosStrdIO 1;
BA_REL_ "GenSigSuprvResp" BU_SG_REL_ CSM_LS SG_ 2150080512 LBCCF_Lct2PosStrdIO 1;
BA_REL_ "GenSigSuprvResp" BU_SG_REL_ RadioHead_LS SG_ 2150080512 LBCCF_Lct2PosStrdIO 1;
BA_REL_ "GenSigSuprvResp" BU_SG_REL_ CSM_LS SG_ 2150080512 LBCCF_Lct1PosStrdIO 1;
BA_REL_ "GenSigSuprvResp" BU_SG_REL_ RadioHead_LS SG_ 2150080512 LBCCF_Lct1PosStrdIO 1;
BA_REL_ "GenSigSuprvResp" BU_SG_REL_ CSM_LS SG_ 2150080512 ChrgCyclOvrlEngyEcnEq 1;
BA_REL_ "GenSigSuprvResp" BU_SG_REL_ RadioHead_LS SG_ 2150080512 ChrgCyclOvrlEngyEcnEq 1;
BA_REL_ "GenSigSuprvResp" BU_SG_REL_ CSM_LS SG_ 2150080512 ChrgCyclElecEngyEcnEq 1;
BA_REL_ "GenSigSuprvResp" BU_SG_REL_ RadioHead_LS SG_ 2150080512 ChrgCyclElecEngyEcnEq 1;
BA_REL_ "GenSigSuprvResp" BU_SG_REL_ ECC_LS SG_ 2150080512 EngAstHtDfrdHtMdAct 1;
BA_REL_ "GenSigSuprvResp" BU_SG_REL_ CSM_LS SG_ 2152128512 PSPMCA_PsngStPrfMd6Avl 1;
BA_REL_ "GenSigSuprvResp" BU_SG_REL_ RadioHead_LS SG_ 2152128512 PSPMCA_PsngStPrfMd6Avl 1;
BA_REL_ "GenSigSuprvResp" BU_SG_REL_ CSM_LS SG_ 2152128512 PSPMCA_PsngStPrfMd5Avl 1;
BA_REL_ "GenSigSuprvResp" BU_SG_REL_ RadioHead_LS SG_ 2152128512 PSPMCA_PsngStPrfMd5Avl 1;
BA_REL_ "GenSigSuprvResp" BU_SG_REL_ CSM_LS SG_ 2152128512 PSPMCA_PsngStPrfMd4Avl 1;
BA_REL_ "GenSigSuprvResp" BU_SG_REL_ RadioHead_LS SG_ 2152128512 PSPMCA_PsngStPrfMd4Avl 1;
BA_REL_ "GenSigSuprvResp" BU_SG_REL_ CSM_LS SG_ 2152128512 PSPMCA_PsngStPrfMd3Avl 1;
BA_REL_ "GenSigSuprvResp" BU_SG_REL_ RadioHead_LS SG_ 2152128512 PSPMCA_PsngStPrfMd3Avl 1;
BA_REL_ "GenSigSuprvResp" BU_SG_REL_ CSM_LS SG_ 2152128512 PSPMCA_PsngStPrfMd2Avl 1;
BA_REL_ "GenSigSuprvResp" BU_SG_REL_ RadioHead_LS SG_ 2152128512 PSPMCA_PsngStPrfMd2Avl 1;
BA_REL_ "GenSigSuprvResp" BU_SG_REL_ CSM_LS SG_ 2152128512 PSPMCA_PsngStPrfMd1Avl 1;
BA_REL_ "GenSigSuprvResp" BU_SG_REL_ RadioHead_LS SG_ 2152128512 PSPMCA_PsngStPrfMd1Avl 1;
BA_REL_ "GenSigSuprvResp" BU_SG_REL_ CSM_LS SG_ 2152128512 DSPMCA_DrvrStPrfMd6Avl 1;
BA_REL_ "GenSigSuprvResp" BU_SG_REL_ RadioHead_LS SG_ 2152128512 DSPMCA_DrvrStPrfMd6Avl 1;
BA_REL_ "GenSigSuprvResp" BU_SG_REL_ CSM_LS SG_ 2152128512 DSPMCA_DrvrStPrfMd5Avl 1;
BA_REL_ "GenSigSuprvResp" BU_SG_REL_ RadioHead_LS SG_ 2152128512 DSPMCA_DrvrStPrfMd5Avl 1;
BA_REL_ "GenSigSuprvResp" BU_SG_REL_ CSM_LS SG_ 2152128512 DSPMCA_DrvrStPrfMd4Avl 1;
BA_REL_ "GenSigSuprvResp" BU_SG_REL_ RadioHead_LS SG_ 2152128512 DSPMCA_DrvrStPrfMd4Avl 1;
BA_REL_ "GenSigSuprvResp" BU_SG_REL_ CSM_LS SG_ 2152128512 DSPMCA_DrvrStPrfMd3Avl 1;
BA_REL_ "GenSigSuprvResp" BU_SG_REL_ RadioHead_LS SG_ 2152128512 DSPMCA_DrvrStPrfMd3Avl 1;
BA_REL_ "GenSigSuprvResp" BU_SG_REL_ CSM_LS SG_ 2152128512 DSPMCA_DrvrStPrfMd2Avl 1;
BA_REL_ "GenSigSuprvResp" BU_SG_REL_ RadioHead_LS SG_ 2152128512 DSPMCA_DrvrStPrfMd2Avl 1;
BA_REL_ "GenSigSuprvResp" BU_SG_REL_ CSM_LS SG_ 2152128512 DSPMCA_DrvrStPrfMd1Avl 1;
BA_REL_ "GenSigSuprvResp" BU_SG_REL_ RadioHead_LS SG_ 2152128512 DSPMCA_DrvrStPrfMd1Avl 1;
BA_REL_ "GenSigSuprvResp" BU_SG_REL_ CSM_LS SG_ 2152128512 DSPMCA_DrvStyPrfMd7Avl 1;
BA_REL_ "GenSigSuprvResp" BU_SG_REL_ RadioHead_LS SG_ 2152128512 DSPMCA_DrvStyPrfMd7Avl 1;
BA_REL_ "GenSigSuprvResp" BU_SG_REL_ CSM_LS SG_ 2152128512 DSPMCA_DrvStyPrfMd6Avl 1;
BA_REL_ "GenSigSuprvResp" BU_SG_REL_ RadioHead_LS SG_ 2152128512 DSPMCA_DrvStyPrfMd6Avl 1;
BA_REL_ "GenSigSuprvResp" BU_SG_REL_ CSM_LS SG_ 2152128512 DSPMCA_DrvStyPrfMd5Avl 1;
BA_REL_ "GenSigSuprvResp" BU_SG_REL_ RadioHead_LS SG_ 2152128512 DSPMCA_DrvStyPrfMd5Avl 1;
BA_REL_ "GenSigSuprvResp" BU_SG_REL_ CSM_LS SG_ 2152128512 DSPMCA_DrvStyPrfMd4Avl 1;
BA_REL_ "GenSigSuprvResp" BU_SG_REL_ RadioHead_LS SG_ 2152128512 DSPMCA_DrvStyPrfMd4Avl 1;
BA_REL_ "GenSigSuprvResp" BU_SG_REL_ CSM_LS SG_ 2152128512 DSPMCA_DrvStyPrfMd3Avl 1;
BA_REL_ "GenSigSuprvResp" BU_SG_REL_ RadioHead_LS SG_ 2152128512 DSPMCA_DrvStyPrfMd3Avl 1;
BA_REL_ "GenSigSuprvResp" BU_SG_REL_ CSM_LS SG_ 2152128512 DSPMCA_DrvStyPrfMd2Avl 1;
BA_REL_ "GenSigSuprvResp" BU_SG_REL_ RadioHead_LS SG_ 2152128512 DSPMCA_DrvStyPrfMd2Avl 1;
BA_REL_ "GenSigSuprvResp" BU_SG_REL_ CSM_LS SG_ 2152128512 DSPMCA_DrvStyPrfMd1Avl 1;
BA_REL_ "GenSigSuprvResp" BU_SG_REL_ RadioHead_LS SG_ 2152128512 DSPMCA_DrvStyPrfMd1Avl 1;
BA_REL_ "GenSigSuprvResp" BU_SG_REL_ CSM_LS SG_ 2152128512 ACCPMCA_ACCPrfMd6Avl 1;
BA_REL_ "GenSigSuprvResp" BU_SG_REL_ RadioHead_LS SG_ 2152128512 ACCPMCA_ACCPrfMd6Avl 1;
BA_REL_ "GenSigSuprvResp" BU_SG_REL_ CSM_LS SG_ 2152128512 ACCPMCA_ACCPrfMd5Avl 1;
BA_REL_ "GenSigSuprvResp" BU_SG_REL_ RadioHead_LS SG_ 2152128512 ACCPMCA_ACCPrfMd5Avl 1;
BA_REL_ "GenSigSuprvResp" BU_SG_REL_ CSM_LS SG_ 2152128512 ACCPMCA_ACCPrfMd4Avl 1;
BA_REL_ "GenSigSuprvResp" BU_SG_REL_ RadioHead_LS SG_ 2152128512 ACCPMCA_ACCPrfMd4Avl 1;
BA_REL_ "GenSigSuprvResp" BU_SG_REL_ CSM_LS SG_ 2152128512 ACCPMCA_ACCPrfMd3Avl 1;
BA_REL_ "GenSigSuprvResp" BU_SG_REL_ RadioHead_LS SG_ 2152128512 ACCPMCA_ACCPrfMd3Avl 1;
BA_REL_ "GenSigSuprvResp" BU_SG_REL_ CSM_LS SG_ 2152128512 ACCPMCA_ACCPrfMd2Avl 1;
BA_REL_ "GenSigSuprvResp" BU_SG_REL_ RadioHead_LS SG_ 2152128512 ACCPMCA_ACCPrfMd2Avl 1;
BA_REL_ "GenSigSuprvResp" BU_SG_REL_ CSM_LS SG_ 2152128512 ACCPMCA_ACCPrfMd1Avl 1;
BA_REL_ "GenSigSuprvResp" BU_SG_REL_ RadioHead_LS SG_ 2152128512 ACCPMCA_ACCPrfMd1Avl 1;
BA_REL_ "GenSigSuprvResp" BU_SG_REL_ BCM_LS SG_ 2151997440 DrvDrowSysIndRq 1;
BA_REL_ "GenSigSuprvResp" BU_SG_REL_ IPC_LS SG_ 2151997440 DrvDrowSysIndRq 1;
BA_REL_ "GenSigSuprvResp" BU_SG_REL_ CSM_LS SG_ 2151997440 DrvDrwDetCsCrStVal 1;
BA_REL_ "GenSigSuprvResp" BU_SG_REL_ RadioHead_LS SG_ 2151997440 DrvDrwDetCsCrStVal 1;
BA_REL_ "GenSigSuprvResp" BU_SG_REL_ CSM_LS SG_ 2151997440 DrvDrowDetCstStAvl 1;
BA_REL_ "GenSigSuprvResp" BU_SG_REL_ RadioHead_LS SG_ 2151997440 DrvDrowDetCstStAvl 1;
BA_REL_ "GenSigSuprvResp" BU_SG_REL_ MSM_P_LS SG_ 2151997440 DrvDrsnHptcStRqSeqN 1;
BA_REL_ "GenSigSuprvResp" BU_SG_REL_ MSM_LS SG_ 2151997440 DrvDrsnHptcStRqSeqN 1;
BA_REL_ "GenSigSuprvResp" BU_SG_REL_ BCM_LS SG_ 2151997440 DrDrwSysHptcStVbnRq 1;
BA_REL_ "GenSigSuprvResp" BU_SG_REL_ MSM_P_LS SG_ 2151997440 DrDrwSysHptcStVbnRq 1;
BA_REL_ "GenSigSuprvResp" BU_SG_REL_ MSM_LS SG_ 2151997440 DrDrwSysHptcStVbnRq 1;
BA_REL_ "GenSigSuprvResp" BU_SG_REL_ CSM_LS SG_ 2156331008 EUSD_MsrmntUnit 1;
BA_REL_ "GenSigSuprvResp" BU_SG_REL_ RadioHead_LS SG_ 2156331008 EUSD_MsrmntUnit 1;
BA_REL_ "GenSigSuprvResp" BU_SG_REL_ CSM_LS SG_ 2156331008 EUSD_MsrmntVal 1;
BA_REL_ "GenSigSuprvResp" BU_SG_REL_ RadioHead_LS SG_ 2156331008 EUSD_MsrmntVal 1;
BA_REL_ "GenSigSuprvResp" BU_SG_REL_ BCM_LS SG_ 2156331008 LwRngLVLdShdRq 1;
BA_REL_ "GenSigSuprvResp" BU_SG_REL_ CSM_LS SG_ 2156331008 HVDpltnMdMiCnfdcRg 1;
BA_REL_ "GenSigSuprvResp" BU_SG_REL_ RadioHead_LS SG_ 2156331008 HVDpltnMdMiCnfdcRg 1;
BA_REL_ "GenSigSuprvResp" BU_SG_REL_ RadioHead_LS SG_ 2156331008 HVDpltnMdMiCnfdcRg 1;
BA_REL_ "GenSigSuprvResp" BU_SG_REL_ CSM_LS SG_ 2156331008 HVDpltnMdMxCnfdcRg 1;
BA_REL_ "GenSigSuprvResp" BU_SG_REL_ RadioHead_LS SG_ 2156331008 HVDpltnMdMxCnfdcRg 1;
BA_REL_ "GenSigSuprvResp" BU_SG_REL_ RadioHead_LS SG_ 2156331008 HVDpltnMdMxCnfdcRg 1;
BA_REL_ "GenSigSuprvResp" BU_SG_REL_ VPM_LS SG_ 2151776256 RCTALIC_Indctr1Act 1;
BA_REL_ "GenSigSuprvResp" BU_SG_REL_ VPM_LS SG_ 2151776256 RCTALIC_IndReq 1;
BA_REL_ "GenSigSuprvResp" BU_SG_REL_ VPM_LS SG_ 2151776256 RrCTfcLHptcStRqSeqN 1;
BA_REL_ "GenSigSuprvResp" BU_SG_REL_ MSM_P_LS SG_ 2151776256 RrCTfcLHptcStRqSeqN 1;
BA_REL_ "GenSigSuprvResp" BU_SG_REL_ MSM_LS SG_ 2151776256 RrCTfcLHptcStRqSeqN 1;
BA_REL_ "GenSigSuprvResp" BU_SG_REL_ VPM_LS SG_ 2151776256 RrCTfcLHptcStReq 1;
BA_REL_ "GenSigSuprvResp" BU_SG_REL_ MSM_P_LS SG_ 2151776256 RrCTfcLHptcStReq 1;
BA_REL_ "GenSigSuprvResp" BU_SG_REL_ MSM_LS SG_ 2151776256 RrCTfcLHptcStReq 1;
BA_REL_ "GenSigSuprvResp" BU_SG_REL_ CSM_LS SG_ 2154774528 LtRtHnTrGPSCsStAvl 1;
BA_REL_ "GenSigSuprvResp" BU_SG_REL_ RadioHead_LS SG_ 2154774528 LtRtHnTrGPSCsStAvl 1;
BA_REL_ "GenSigSuprvResp" BU_SG_REL_ CSM_LS SG_ 2154774528 LtRtHnTrGPCsCrStVal 1;
BA_REL_ "GenSigSuprvResp" BU_SG_REL_ RadioHead_LS SG_ 2154774528 LtRtHnTrGPCsCrStVal 1;
BA_REL_ "GenSigSuprvResp" BU_SG_REL_ CSM_LS SG_ 2154774528 LtRtHnTrCstStVal 1;
BA_REL_ "GenSigSuprvResp" BU_SG_REL_ CSM_LS SG_ 2154774528 LtRtHnTrCstStVal 1;
BA_REL_ "GenSigSuprvResp" BU_SG_REL_ RadioHead_LS SG_ 2154774528 LtRtHnTrCstStVal 1;
BA_REL_ "GenSigSuprvResp" BU_SG_REL_ RadioHead_LS SG_ 2154774528 LtRtHnTrCstStVal 1;
BA_REL_ "GenSigSuprvResp" BU_SG_REL_ CSM_LS SG_ 2154774528 LtRtHnTrCstStAvail 1;
BA_REL_ "GenSigSuprvResp" BU_SG_REL_ CSM_LS SG_ 2154774528 LtRtHnTrCstStAvail 1;
BA_REL_ "GenSigSuprvResp" BU_SG_REL_ RadioHead_LS SG_ 2154774528 LtRtHnTrCstStAvail 1;
BA_REL_ "GenSigSuprvResp" BU_SG_REL_ RadioHead_LS SG_ 2154774528 LtRtHnTrCstStAvail 1;
BA_REL_ "GenSigSuprvResp" BU_SG_REL_ BCM_LS SG_ 2150375424 USBProgInPrgrs 1;
BA_REL_ "GenSigSuprvResp" BU_SG_REL_ BCM_LS SG_ 2150375424 DsplTrnsShftLvrLckRqd 1;
BA_REL_ "GenSigSuprvResp" BU_SG_REL_ IPC_LS SG_ 2150383616 BatPrpDspPwrLvlPct 1;
BA_REL_ "GenSigSuprvResp" BU_SG_REL_ IPC_LS SG_ 2150383616 PrpDspTtlPwr 1;
BA_REL_ "GenSigSuprvResp" BU_SG_REL_ IPC_LS SG_ 2150383616 PrpCapDspOpPs 1;
BA_REL_ "GenSigSuprvResp" BU_SG_REL_ IPC_LS SG_ 2150383616 EstElecPrpCap 1;
BA_REL_ "GenSigSuprvResp" BU_SG_REL_ IPC_LS SG_ 2150383616 EngPrpDspPwrLvlPct 1;
BA_REL_ "GenSigSuprvResp" BU_SG_REL_ CSM_LS SG_ 2151981056 DrvCyclBatPropRat 1;
BA_REL_ "GenSigSuprvResp" BU_SG_REL_ RadioHead_LS SG_ 2151981056 DrvCyclBatPropRat 1;
BA_REL_ "GenSigSuprvResp" BU_SG_REL_ RadioHead_LS SG_ 2151981056 DrvCyclBatPropRat 1;
BA_REL_ "GenSigSuprvResp" BU_SG_REL_ CSM_LS SG_ 2151981056 DTD_FuelPrpDstTrvld 1;
BA_REL_ "GenSigSuprvResp" BU_SG_REL_ RadioHead_LS SG_ 2151981056 DTD_FuelPrpDstTrvld 1;
BA_REL_ "GenSigSuprvResp" BU_SG_REL_ RadioHead_LS SG_ 2151981056 DTD_FuelPrpDstTrvld 1;
BA_REL_ "GenSigSuprvResp" BU_SG_REL_ CSM_LS SG_ 2151981056 DTD_DrvCyclDstTrvld 1;
BA_REL_ "GenSigSuprvResp" BU_SG_REL_ RadioHead_LS SG_ 2151981056 DTD_DrvCyclDstTrvld 1;
BA_REL_ "GenSigSuprvResp" BU_SG_REL_ RadioHead_LS SG_ 2151981056 DTD_DrvCyclDstTrvld 1;
BA_REL_ "GenSigSuprvResp" BU_SG_REL_ CSM_LS SG_ 2151981056 DTD_BattPrpDstTrvld 1;
BA_REL_ "GenSigSuprvResp" BU_SG_REL_ RadioHead_LS SG_ 2151981056 DTD_BattPrpDstTrvld 1;
BA_REL_ "GenSigSuprvResp" BU_SG_REL_ RadioHead_LS SG_ 2151981056 DTD_BattPrpDstTrvld 1;
BA_REL_ "GenSigSuprvResp" BU_SG_REL_ CSM_LS SG_ 2151964672 DrvCyclTtlEnrgEfncy 1;
BA_REL_ "GenSigSuprvResp" BU_SG_REL_ RadioHead_LS SG_ 2151964672 DrvCyclTtlEnrgEfncy 1;
BA_REL_ "GenSigSuprvResp" BU_SG_REL_ RadioHead_LS SG_ 2151964672 DrvCyclTtlEnrgEfncy 1;
BA_REL_ "GenSigSuprvResp" BU_SG_REL_ CSM_LS SG_ 2151964672 DrvCyclFuelUsd 1;
BA_REL_ "GenSigSuprvResp" BU_SG_REL_ RadioHead_LS SG_ 2151964672 DrvCyclFuelUsd 1;
BA_REL_ "GenSigSuprvResp" BU_SG_REL_ RadioHead_LS SG_ 2151964672 DrvCyclFuelUsd 1;
BA_REL_ "GenSigSuprvResp" BU_SG_REL_ CSM_LS SG_ 2151964672 DrvCyclFuelEnmy 1;
BA_REL_ "GenSigSuprvResp" BU_SG_REL_ RadioHead_LS SG_ 2151964672 DrvCyclFuelEnmy 1;
BA_REL_ "GenSigSuprvResp" BU_SG_REL_ RadioHead_LS SG_ 2151964672 DrvCyclFuelEnmy 1;
BA_REL_ "GenSigSuprvResp" BU_SG_REL_ CSM_LS SG_ 2151964672 DrvCyclDrvStEnrgEfncy 1;
BA_REL_ "GenSigSuprvResp" BU_SG_REL_ RadioHead_LS SG_ 2151964672 DrvCyclDrvStEnrgEfncy 1;
BA_REL_ "GenSigSuprvResp" BU_SG_REL_ RadioHead_LS SG_ 2151964672 DrvCyclDrvStEnrgEfncy 1;
BA_REL_ "GenSigSuprvResp" BU_SG_REL_ CSM_LS SG_ 2151964672 DrvCyclCbnCondEnrgEfncy 1;
BA_REL_ "GenSigSuprvResp" BU_SG_REL_ RadioHead_LS SG_ 2151964672 DrvCyclCbnCondEnrgEfncy 1;
BA_REL_ "GenSigSuprvResp" BU_SG_REL_ RadioHead_LS SG_ 2151964672 DrvCyclCbnCondEnrgEfncy 1;
BA_REL_ "GenSigSuprvResp" BU_SG_REL_ CSM_LS SG_ 2151964672 DrvCyclBatCondEnrgEfncy 1;
BA_REL_ "GenSigSuprvResp" BU_SG_REL_ RadioHead_LS SG_ 2151964672 DrvCyclBatCondEnrgEfncy 1;
BA_REL_ "GenSigSuprvResp" BU_SG_REL_ RadioHead_LS SG_ 2151964672 DrvCyclBatCondEnrgEfncy 1;
VAL_ 2151292928 TrfRdsdInfCsStAvail 1 "true" 0 "false" ;
VAL_ 2151292928 TrfRdsdInfCsCrStVal 7 "Reserved5" 6 "Reserved4" 5 "Reserved3" 4 "Reserved2" 3 "Reserved1" 2 "On" 1 "Off" 0 "No Action" ;
VAL_ 2151292928 TRICA_Resrv5Avail 1 "true" 0 "false" ;
VAL_ 2151292928 TRICA_Resrv4Avail 1 "true" 0 "false" ;
VAL_ 2151292928 TRICA_Resrv3Avail 1 "true" 0 "false" ;
VAL_ 2151292928 TRICA_Resrv2Avail 1 "true" 0 "false" ;
VAL_ 2151292928 TRICA_Resrv1Avail 1 "true" 0 "false" ;
VAL_ 2151292928 TRICA_OnAvail 1 "true" 0 "false" ;
VAL_ 2151292928 TRICA_OfAvail 1 "true" 0 "false" ;
VAL_ 2151292928 IntrStopAlrtCsSetAvl 1 "true" 0 "false" ;
VAL_ 2151292928 IntrStAlrtCsCrSetVal 7 "Reserved4" 6 "Reserved3" 5 "Reserved2" 4 "Reserved1" 3 "Alert and Brake" 2 "Alert " 1 "Off" 0 "No Action" ;
VAL_ 2151292928 ISACA_Resrv4Avail 1 "true" 0 "false" ;
VAL_ 2151292928 ISACA_Resrv3Avail 1 "true" 0 "false" ;
VAL_ 2151292928 ISACA_Resrv2Avail 1 "true" 0 "false" ;
VAL_ 2151292928 ISACA_Resrv1Avail 1 "true" 0 "false" ;
VAL_ 2151292928 ISACA_AlrtBrkAvail 1 "true" 0 "false" ;
VAL_ 2151292928 ISACA_AlrtAvail 1 "true" 0 "false" ;
VAL_ 2151292928 ISACA_OfAvail 1 "true" 0 "false" ;
VAL_ 2151292928 CntdVehBrkAltCsStAvl 1 "true" 0 "false" ;
VAL_ 2151292928 CntdVehBrAltCsCrStVal 7 "Reserved5" 6 "Reserved4" 5 "Reserved3" 4 "Reserved2" 3 "Reserved1" 2 "On" 1 "Off" 0 "No Action" ;
VAL_ 2151292928 CVBACA_Resrv5Avail 1 "true" 0 "false" ;
VAL_ 2151292928 CVBACA_Resrv4Avail 1 "true" 0 "false" ;
VAL_ 2151292928 CVBACA_Resrv3Avail 1 "true" 0 "false" ;
VAL_ 2151292928 CVBACA_Resrv2Avail 1 "true" 0 "false" ;
VAL_ 2151292928 CVBACA_Resrv1Avail 1 "true" 0 "false" ;
VAL_ 2151292928 CVBACA_OnAvail 1 "true" 0 "false" ;
VAL_ 2151292928 CVBACA_OfAvail 1 "true" 0 "false" ;
VAL_ 2151464960 V2VWrngIndReq 31 "Unused And Reserved 15" 30 "Unused And Reserved 14" 29 "Unused And Reserved 13" 28 "Unused And Reserved 12" 27 "Unused And Reserved 11" 26 "Unused And Reserved 10" 25 "Unused And Reserved 9" 24 "Unused And Reserved 8" 23 "Unused And Reserved 7" 22 "Unused And Reserved 6" 21 "Unused And Reserved 5" 20 "Unused And Reserved 4" 19 "Unused And Reserved 3" 18 "Unused And Reserved 2" 17 "Unused And Reserved 1" 16 "Green Light Optimal Speed Advisory" 15 "Intersection Colision Warning Right" 14 "Intersection Colision Warning Left" 13 "Intersection Stop" 12 "Construction Ends" 11 "Construction Starts" 10 "Slowing Traffic" 9 "Crosswinds" 8 "Slippery Road" 7 "Low Visibility" 6 "Heavy Rain" 5 "Sharp  Curve" 4 "Obstacle" 3 "Emergency Vehicle" 2 "Hard Braking" 1 "Hazard Lights" 0 "No Indication" ;
VAL_ 2151464960 V2VWrngDirctn 7 "North West" 6 "West" 5 "South West" 4 "South" 3 "South East" 2 "East" 1 "North East" 0 "North" ;
VAL_ 2151464960 V2VSrvIndReq 3 "Unused and Reserved2" 2 "Unused and Reserved1" 1 "Service V2V System" 0 "No Indication" ;
VAL_ 2151464960 V2VTLI_TrfLghtMntngDirctn 1 "Horizontal" 0 "Vertical" ;
VAL_ 2151464960 V2VTLI_TrfLghtValDirctn 3 "All direction" 2 "Right" 1 "Left" 0 "Straight" ;
VAL_ 2151464960 V2VTLI_TrfLghtPhsArivl 3 "Unknown Phase" 2 "Yellow" 1 "Green" 0 "Red" ;
VAL_ 2151464960 V2VTLI_TrfLghtActlPhs 3 "Unknown Phase" 2 "Yellow" 1 "Green" 0 "Red" ;
VAL_ 2153930752 LnCntrVhlStpd 1 "true" 0 "false" ;
VAL_ 2153930752 LnCntrSpchPrmtReq 3 "Unused and Reserved" 2 "Take Vehicle Control" 1 "Take Steering" 0 "No Prompt" ;
VAL_ 2153930752 LCWrnIndReq 25 "Sensor Imparied" 24 "Vehicle Center" 23 "Driver Action" 22 "GPS Unavailable" 21 "Driver Attn Off Road" 20 "Controlled Access" 19 "Adaptive Cruise" 18 "Vehicle Setting" 17 "GM Authority" 16 "Exit Lane" 15 "Lane Ending" 14 "Lane Following Locked Out" 13 "Service Driver Assist System" 12 "Take Vehicle Control" 11 "Take Steering" 10 "Due to Weather" 9 "Attention Unknown" 8 "Unavailable" 7 "Adaptive Cruise Disengaging" 6 "Vehicle Proximity" 5 "Excessive Speed" 4 "Construction" 3 "Freeway Ends" 2 "Tight Curve" 1 "Lane Lines" 0 "No Indication" ;
VAL_ 2153930752 LCCDrvrAwrnsIO 1 "true" 0 "false" ;
VAL_ 2153930752 LCConvMsgIndreq 31 "Reserved" 30 "Reserved" 29 "Reserved" 28 "Reserved" 27 "Reserved" 26 "Reserved" 25 "Reserved" 24 "Reserved" 23 "Reserved" 22 "Reserved" 21 "Reserved" 20 "Reserved" 19 "Show Fuel Range" 18 "Show Fuel Level" 17 "Take Time to Look at Road" 16 "Road Detour Detected" 15 "Lane Ending Ahead" 14 "Exit Only Lane Ahead" 13 "Road Exit Detected Ahead" 12 "Major Road Interchange Ahead" 11 "Slow Moving Traffic in Right Lane" 10 "Slow Moving Traffic Ahead" 9 "Slow Moving Traffic in Left Lane" 8 "Merging Vehicle" 7 "Heavy Traffic" 6 "Right Blind Spot Occupied" 5 "Left Blind Spot Occupied" 4 "Tailgater Detected" 3 "Being Passed on Right" 2 "Being Passed on Left" 1 "Behind Slow Vehicle" 0 "No Indication" ;
VAL_ 2153930752 LCCIndReq 7 "Reserved" 6 "Reserved" 5 "Reserved" 4 "Red Indicator" 3 "Blue Indicator" 2 "Green Indicator" 1 "White Indicator" 0 "Indicator Off" ;
VAL_ 2153930752 LnCntrNonRspDrvrCnd 1 "true" 0 "false" ;
VAL_ 2153930752 LnCntrEsclnStat 3 "System Faulted" 2 "Limit Condition" 1 "Driver Not Looking to Roadway" 0 "None" ;
VAL_ 2153889792 LCArrwBlk5Act 1 "true" 0 "false" ;
VAL_ 2153889792 LCArrwBlk4Act 1 "true" 0 "false" ;
VAL_ 2153889792 LCArrwBlk3Act 1 "true" 0 "false" ;
VAL_ 2153889792 LCArrwBlk2Act 1 "true" 0 "false" ;
VAL_ 2153889792 LCArrwBlk1Act 1 "true" 0 "false" ;
VAL_ 2151882752 PTOTpStpSpdCsStReq 0 "No Action" 1 "5 rpm" 2 "10 rpm" 3 "25 rpm" 4 "50 rpm" 5 "100 rpm" 6 "250 rpm" 7 "500 rpm" ;
VAL_ 2151882752 PTOStdbySpdCsStReq 0 "No Action" 1 "900 rpm" 2 "1000 rpm" 3 "1100 rpm" 4 "1200 rpm" 5 "1300 rpm" 6 "1400 rpm" 7 "1500 rpm" ;
VAL_ 2151882752 PTOEngRnTmrCsStRq 0 "No Action" 1 "10 min" 2 "30 min" 3 "90 min" 4 "120 min" 5 "150 min" 6 "180 min" 7 "210 min" 8 "240 min" 9 "270 min" 10 "300 min" 11 "330 min" 12 "360 min" 13 "390 min" 14 "420 min" 15 "450 min" ;
VAL_ 2151882752 PTOSet2SpdCsStReq 0 "No Action" 1 "Speed 1" 2 "Speed 2" 3 "Speed 3" 4 "Speed 4" 5 "Speed 5" 6 "Speed 6" 7 "Speed 7" 8 "Speed 8" 9 "Speed 9" 10 "Speed 10" 11 "Speed 11" 12 "Speed 12" 13 "Speed 13" 14 "Speed 14" 15 "Speed 15" ;
VAL_ 2151882752 PTOSet1SpdCsStReq 0 "No Action" 1 "1100 rpm" 2 "1200 rpm" 3 "1300 rpm" 4 "1400 rpm" 5 "1500 rpm" 6 "1600 rpm" 7 "1700 rpm" 8 "1800 rpm" 9 "1900 rpm" 10 "2000 rpm" 11 "2100 rpm" 12 "2200 rpm" 13 "2300 rpm" 14 "2400 rpm" 15 "2500 rpm" ;
VAL_ 2151899136 PTOAccelUpnBrkRelIO 1 "true" 0 "false" ;
VAL_ 2151899136 PTOEngUpnBrkRelIO 1 "true" 0 "false" ;
VAL_ 2151899136 PTOManTransInGrIO 1 "true" 0 "false" ;
VAL_ 2151899136 PTOServIndOn 1 "true" 0 "false" ;
VAL_ 2151899136 PTOVDM 0 "Don't Use Data" 1 "Use Data" ;
VAL_ 2151899136 PTOVDA 1 "VirtualDeviceAvailable" 0 "VirtualDeviceUnavailable" ;
VAL_ 2151899136 PTOTransInGearIO 1 "true" 0 "false" ;
VAL_ 2151899136 PTOTpStpSpdCsStAvl 1 "true" 0 "false" ;
VAL_ 2151899136 PTOTpStSpdCsCrStVal 0 "No Action" 1 "5 rpm" 2 "10 rpm" 3 "25 rpm" 4 "50 rpm" 5 "100 rpm" 6 "250 rpm" 7 "500 rpm" ;
VAL_ 2151899136 PTOStdbySpdCsStAvl 1 "true" 0 "false" ;
VAL_ 2151899136 PTOStdbSpdCsCrStVal 0 "No Action" 1 "900 rpm" 2 "1000 rpm" 3 "1100 rpm" 4 "1200 rpm" 5 "1300 rpm" 6 "1400 rpm" 7 "1500 rpm" ;
VAL_ 2151899136 PTOSetPrkBrkIO 1 "true" 0 "false" ;
VAL_ 2151899136 PTOSet2SpdCsStAvl 1 "true" 0 "false" ;
VAL_ 2151899136 PTOSet2SpdCsCrStVal 0 "No action" 1 "Speed 1" 2 "Speed 2" 3 "Speed 3" 4 "Speed 4" 5 "Speed 5" 6 "Speed 6" 7 "Speed 7" 8 "Speed 8" 9 "Speed 9" 10 "Speed 10" 11 "Speed 11" 12 "Speed 12" 13 "Speed 13" 14 "Speed 14" 15 "Speed 15" ;
VAL_ 2151899136 PTOSet1SpdCsStAvl 1 "true" 0 "false" ;
VAL_ 2151899136 PTOSet1SpdCsCrStVal 0 "No Action" 1 "1100 rpm" 2 "1200 rpm" 3 "1300 rpm" 4 "1400 rpm" 5 "1500 rpm" 6 "1600 rpm" 7 "1700 rpm" 8 "1800 rpm" 9 "1900 rpm" 10 "2000 rpm" 11 "2100 rpm" 12 "2200 rpm" 13 "2300 rpm" 14 "2400 rpm" 15 "2500 rpm" ;
VAL_ 2151899136 PTORelCltPedIO 1 "true" 0 "false" ;
VAL_ 2151899136 PTORelBrkPedIO 1 "true" 0 "false" ;
VAL_ 2151899136 PTORelAccPedIO 1 "true" 0 "false" ;
VAL_ 2151899136 PTORedEngSpdIO 1 "true" 0 "false" ;
VAL_ 2151899136 PTOPrsRelCltPedIO 1 "true" 0 "false" ;
VAL_ 2151899136 PTOPrsRelBrkPedIO 1 "true" 0 "false" ;
VAL_ 2151899136 PTOEngRnTmrCsStAvl 1 "true" 0 "false" ;
VAL_ 2151899136 PTOEnRnTmCsCrStVal 0 "No Action" 1 "10 min" 2 "30 min" 3 "90 min" 4 "120 min" 5 "150 min" 6 "180 min" 7 "210 min" 8 "240 min" 9 "270 min" 10 "300 min" 11 "330 min" 12 "360 min" 13 "390 min" 14 "420 min" 15 "450 min" ;
VAL_ 2151899136 PTOEngmntStatInd 0 "No Indication" 1 "Continuous Indication" 2 "Slow Flashing Indication" 3 "Fast Flashing Indication" ;
VAL_ 2151899136 PTODisengCrsCntlIO 1 "true" 0 "false" ;
VAL_ 2150580224 CstmrNonUsblSOCV 1 "Invalid" 0 "Valid" ;
VAL_ 2151735296 RtSdDetSysServDsbld 1 "true" 0 "false" ;
VAL_ 2151735296 RtSdDetSysTmpDsbld 1 "true" 0 "false" ;
VAL_ 2151735296 RtLnChgAlrtEnbld 1 "true" 0 "false" ;
VAL_ 2151735296 RtSBZAlrtEnbld 1 "true" 0 "false" ;
VAL_ 2151735296 RtRrCrsTrfcAlrtEnbld 1 "true" 0 "false" ;
VAL_ 2151735296 LnChgAlrtOffIndOn 1 "true" 0 "false" ;
VAL_ 2151735296 RrCrsTrfcAlrtOffIO 1 "true" 0 "false" ;
VAL_ 2151792640 RCTARIC_Indctr1Act 1 "true" 0 "false" ;
VAL_ 2151792640 RCTARIC_IndReq 0 "Off" 1 "Continuous Indication" 2 "Flashing Indication" ;
VAL_ 2149826560 SpdSignUltdDetdIO 1 "true" 0 "false" ;
VAL_ 2149826560 TrfcSgnMmryIcePosIO 1 "true" 0 "false" ;
VAL_ 2149826560 SpdLmtVsnFsdSpdUnt 0 "km/h" 1 "mph" ;
VAL_ 2149826560 SpdLmtVnFsSpdNwDet 1 "true" 0 "false" ;
VAL_ 2149826560 SpdLmtVsnFsdSpdM 0 "Don't Use Data" 1 "Use Data" ;
VAL_ 2149826560 FOAI_VehAhdIndRq11E 0 "No Alert" 1 "Alert Level 1" 2 "Alert Level 2" 3 "Alert Level 3" ;
VAL_ 2149826560 FOAI_AlrtWrnIndRq11E 0 "No Alert" 1 "Alert Level 1" 2 "Alert Level 2" 3 "Alert Level 3" ;
VAL_ 2149826560 FOAI_AlrtChmIhbRq11E 0 "Allow Chime" 1 "Inhibit Chime" ;
VAL_ 2149826560 FwdClnAlrtOffIO11E 1 "true" 0 "false" ;
VAL_ 2149826560 FwdClnAlrtPr11E 1 "true" 0 "false" ;
VAL_ 2149826560 FCABrkPrflReq 1 "true" 0 "false" ;
VAL_ 2149826560 FCAHdwyStngIO 1 "true" 0 "false" ;
VAL_ 2149826560 FCAGpStng 0 "Off" 1 "Near" 2 "Medium" 3 "Reserved3" 4 "Reserved4" 5 "Reserved5" 6 "Reserved6" 7 "Far" ;
VAL_ 2149826560 FCACrusCtrlCnclReqd 1 "true" 0 "false" ;
VAL_ 2149957632 PrkAstRrObjSnsngRqAct 1 "true" 0 "false" ;
VAL_ 2149957632 PrkAstOprtrDsrdStat 0 "Off" 1 "On" 2 "Tow Bar Attached" ;
VAL_ 2149957632 PrkAstInhbtReq 1 "true" 0 "false" ;
VAL_ 2149957632 ClsnMtgtnInhbtd 1 "true" 0 "false" ;
VAL_ 2149941248 PrkAstRrObjSnsngAct 1 "true" 0 "false" ;
VAL_ 2149941248 PrkAstRrSysStatUnfltd 0 "Disabled" 1 "Enabled" 2 "Inhibited" 3 "Failed" ;
VAL_ 2149941248 PrkAstFntnSnsDstrbdIO 1 "true" 0 "false" ;
VAL_ 2149941248 PrkAstFntnSnrsBlkd 1 "true" 0 "false" ;
VAL_ 2149941248 PrkAstFntnFld 1 "true" 0 "false" ;
VAL_ 2149941248 PrkAstFntnDsbldIO 1 "true" 0 "false" ;
VAL_ 2149941248 PrkAstFntnClnPrkAstIO 1 "true" 0 "false" ;
VAL_ 2149941248 ClsnMtgtnInhbtReqtd 1 "true" 0 "false" ;
VAL_ 2149941248 PARrRgn4ObjStatUnfltd 0 "No Object" 1 "Zone 1" 2 "Zone 2" 3 "Zone 3" 4 "Zone 4" 5 "Zone 5" 6 "Zone 6" 7 "Zone 7" 8 "Zone 8" 9 "Zone 9" 10 "Zone 10" 11 "Zone 11" 12 "Zone 12" 13 "Zone 13" 14 "Zone 14" 15 "Zone 15" ;
VAL_ 2149941248 PARrRgn3ObjStatUnfltd 0 "No Object" 1 "Zone 1" 2 "Zone 2" 3 "Zone 3" 4 "Zone 4" 5 "Zone 5" 6 "Zone 6" 7 "Zone 7" 8 "Zone 8" 9 "Zone 9" 10 "Zone 10" 11 "Zone 11" 12 "Zone 12" 13 "Zone 13" 14 "Zone 14" 15 "Zone 15" ;
VAL_ 2149941248 PARrRgn2ObjStatUnfltd 0 "No Object" 1 "Zone 1" 2 "Zone 2" 3 "Zone 3" 4 "Zone 4" 5 "Zone 5" 6 "Zone 6" 7 "Zone 7" 8 "Zone 8" 9 "Zone 9" 10 "Zone 10" 11 "Zone 11" 12 "Zone 12" 13 "Zone 13" 14 "Zone 14" 15 "Zone 15" ;
VAL_ 2149941248 PARrRgn1ObjStatUnfltd 0 "No Object" 1 "Zone 1" 2 "Zone 2" 3 "Zone 3" 4 "Zone 4" 5 "Zone 5" 6 "Zone 6" 7 "Zone 7" 8 "Zone 8" 9 "Zone 9" 10 "Zone 10" 11 "Zone 11" 12 "Zone 12" 13 "Zone 13" 14 "Zone 14" 15 "Zone 15" ;
VAL_ 2156314624 HVChrgSysSplyFltIO 1 "true" 0 "false" ;
VAL_ 2156314624 OffBrdCSFltDtctd 1 "true" 0 "false" ;
VAL_ 2156314624 OBVhCsACChgRqBnVs 1 "true" 0 "false" ;
VAL_ 2156314624 TODCNPDT_DyOfWk 0 "Unknown" 1 "Sunday" 2 "Monday" 3 "Tuesday" 4 "Wednesday" 5 "Thursday" 6 "Friday" 7 "Saturday" ;
VAL_ 2156314624 TODCOpMd 0 "Normal Operation" 1 "Departure Time Temporary Override" 2 "Charge Mode Temporary Override" 3 "Time of Day Faulted" ;
VAL_ 2156314624 TODCDMPTO_TpOvR 11 "Offboard Thermal Conditioning Only" 10 "Offboard Not Active Bulk Done" 9 "Offboard Active Bulk Done" 8 "Offboard Not Active" 7 "Offboard Active" 0 "None" 1 "Override Immediate" 2 "Override Next Plan Depart Time" 3 "Disabled" 4 "Onboard Fault" 5 "Offboard Fault Off Vehicle" 6 "Offboard Fault On Vehicle" ;
VAL_ 2156314624 TODCDMPTO_CmPgR 1 "true" 0 "false" ;
VAL_ 2156314624 HVChrgSysStNot 6 "Utility Override" 0 "Default" 1 "Idle" 2 "Initializing" 3 "Active" 4 "Complete" 5 "Aborted" ;
VAL_ 2156314624 HVChrgAbrtRsn 0 "No Action" 1 "Loss of AC" 2 "Unplug Charge" 3 "Unplug Delay" 4 "Charge Failure" 5 "Cordset Fault" 6 "Cordset Delay" ;
VAL_ 2156314624 HVCSCLPD_UsrIntTyp 0 "User Interface 1" 1 "User Interface 2" ;
VAL_ 2156314624 HVCSCLPD_ChgLvlPfS 0 "No Reduction" 1 "Reduced Current Level 1" 2 "Reduced Current Level 2" 3 "Reduced Current Level 3" ;
VAL_ 2150449152 ESPDrvrExtIO 1 "true" 0 "false" ;
VAL_ 2150449152 ESPDrvrDrStIndtrmntIO 1 "true" 0 "false" ;
VAL_ 2150449152 ESPAutoPrkIO 1 "true" 0 "false" ;
VAL_ 2150449152 ManTransIndReq 3 "Indication 3" 2 "Indication 2" 1 "Indication 1" 0 "No Indication" ;
VAL_ 2150449152 SrvcFlSysPrkInOpnArIO 1 "true" 0 "false" ;
VAL_ 2150449152 TnDrvStblCtrlOffUnbIO 1 "true" 0 "false" ;
VAL_ 2150449152 TnDrvTrCtrlOffUnbIO 1 "true" 0 "false" ;
VAL_ 2150449152 ASIRI_Indication08 1 "true" 0 "false" ;
VAL_ 2150449152 ASIRI_Indication07 1 "true" 0 "false" ;
VAL_ 2150449152 ASIRI_Indication06 1 "true" 0 "false" ;
VAL_ 2150449152 ASIRI_Indication05 1 "true" 0 "false" ;
VAL_ 2150449152 ASIRI_Indication04 1 "true" 0 "false" ;
VAL_ 2150449152 ASIRI_Indication03 1 "true" 0 "false" ;
VAL_ 2150449152 ASIRI_Indication02 1 "true" 0 "false" ;
VAL_ 2150449152 ASIRI_Indication01 1 "true" 0 "false" ;
VAL_ 2150449152 SpdLmtrSttngTypAct 3 "Reserved" 2 "Auto" 1 "Manual" 0 "Off" ;
VAL_ 2150449152 FuelSysNEmsRltMalfAct 1 "true" 0 "false" ;
VAL_ 2150449152 InActFuelMdFuelLvlIO 1 "true" 0 "false" ;
VAL_ 2150449152 EngInltSpcfcHmdtyV 1 "Invalid" 0 "Valid" ;
VAL_ 2150449152 EngInltSpcfcHmdtyM 0 "Don't Use Data" 1 "Use Data" ;
VAL_ 2150449152 AltFuelSysOvrflDtdIO 1 "true" 0 "false" ;
VAL_ 2149793792 AutoEmrgncyBrkDisbldIO 1 "true" 0 "false" ;
VAL_ 2149793792 VADIR_IndLvl 0 "No indication" 1 "Indication level 1" 2 "Indication Level 2" 3 "Indication Level 3" 4 "Indication Level 4" 5 "Indication Level 5" 6 "Indication Level 6" 7 "Indication Level 7" 8 "Indication Level 8" ;
VAL_ 2149793792 FCACustStngAvlbl 1 "true" 0 "false" ;
VAL_ 2149793792 FwdClnAlrtCustCrntSetngVal 0 "No Action" 1 "Off" 2 "On" ;
VAL_ 2150080512 LBCVLS_VehGPSLctV 1 "Invalid" 0 "Valid" ;
VAL_ 2150080512 LBCVLS_VehGPSLct 4 "Vehicle Within Stored GPS Region 4" 3 "Vehicle Within Stored GPS Region 3" 2 "Vehicle Within Stored GPS Region 2" 1 "Vehicle Within Stored GPS Region 1" 0 "Vehicle Not Within Stored GPS Region" ;
VAL_ 2150080512 LBCPSS_PosUpdtStat 2 "Position Modification Failed " 1 "Position  Updated  " 0 "No Action" ;
VAL_ 2150080512 LBCPSS_PosUpdtLct 4 "Position 4" 3 "Position 3" 2 "Position 2" 1 "Position 1" 0 "No Action" ;
VAL_ 2150080512 LBCCsStAvl 1 "true" 0 "false" ;
VAL_ 2150080512 LBCCsCrStVal 2 "On" 1 "Off" 0 "No Action" ;
VAL_ 2150080512 LBCCF_Lct4PosStrdIO 1 "true" 0 "false" ;
VAL_ 2150080512 LBCCF_Lct3PosStrdIO 1 "true" 0 "false" ;
VAL_ 2150080512 LBCCF_Lct2PosStrdIO 1 "true" 0 "false" ;
VAL_ 2150080512 LBCCF_Lct1PosStrdIO 1 "true" 0 "false" ;
VAL_ 2150080512 LBCCDRR_PosNumbr 4 "Position Number 4 " 3 "Position Number 3" 2 "Position Number 2" 1 "Position Number 1" 0 "No Action" ;
VAL_ 2150080512 LBCCDRR_ClrStrdPosResp 2 "Clear Position Performed" 1 "Clear Position Request Acknowledged" 0 "No Action" ;
VAL_ 2150080512 LBCChrgLvlPrfExpIO 1 "true" 0 "false" ;
VAL_ 2150080512 EngAstHtDfrdHtMdAct 1 "true" 0 "false" ;
VAL_ 2150080512 AuxClntHtrVlvStat 7 "Unused and Reserved 2" 6 "De-Aeration Routine Active" 5 "Diagnostic Override" 4 "Re-Calibration" 3 "Fault Active" 2 "Engine Link" 1 "Transition" 0 "Engine Bypass" ;
VAL_ 2153873408 MnlHtdStWhlRqstd 1 "true" 0 "false" ;
VAL_ 2152128512 PSPMCA_PsngStPrfMd6Avl 1 "true" 0 "false" ;
VAL_ 2152128512 PSPMCA_PsngStPrfMd5Avl 1 "true" 0 "false" ;
VAL_ 2152128512 PSPMCA_PsngStPrfMd4Avl 1 "true" 0 "false" ;
VAL_ 2152128512 PSPMCA_PsngStPrfMd3Avl 1 "true" 0 "false" ;
VAL_ 2152128512 PSPMCA_PsngStPrfMd2Avl 1 "true" 0 "false" ;
VAL_ 2152128512 PSPMCA_PsngStPrfMd1Avl 1 "true" 0 "false" ;
VAL_ 2152128512 DSPMCA_DrvrStPrfMd6Avl 1 "true" 0 "false" ;
VAL_ 2152128512 DSPMCA_DrvrStPrfMd5Avl 1 "true" 0 "false" ;
VAL_ 2152128512 DSPMCA_DrvrStPrfMd4Avl 1 "true" 0 "false" ;
VAL_ 2152128512 DSPMCA_DrvrStPrfMd3Avl 1 "true" 0 "false" ;
VAL_ 2152128512 DSPMCA_DrvrStPrfMd2Avl 1 "true" 0 "false" ;
VAL_ 2152128512 DSPMCA_DrvrStPrfMd1Avl 1 "true" 0 "false" ;
VAL_ 2152128512 DSPMCA_DrvStyPrfMd7Avl 1 "true" 0 "false" ;
VAL_ 2152128512 DSPMCA_DrvStyPrfMd6Avl 1 "true" 0 "false" ;
VAL_ 2152128512 DSPMCA_DrvStyPrfMd5Avl 1 "true" 0 "false" ;
VAL_ 2152128512 DSPMCA_DrvStyPrfMd4Avl 1 "true" 0 "false" ;
VAL_ 2152128512 DSPMCA_DrvStyPrfMd3Avl 1 "true" 0 "false" ;
VAL_ 2152128512 DSPMCA_DrvStyPrfMd2Avl 1 "true" 0 "false" ;
VAL_ 2152128512 DSPMCA_DrvStyPrfMd1Avl 1 "true" 0 "false" ;
VAL_ 2152128512 ACCPMCA_ACCPrfMd6Avl 1 "true" 0 "false" ;
VAL_ 2152128512 ACCPMCA_ACCPrfMd5Avl 1 "true" 0 "false" ;
VAL_ 2152128512 ACCPMCA_ACCPrfMd4Avl 1 "true" 0 "false" ;
VAL_ 2152128512 ACCPMCA_ACCPrfMd3Avl 1 "true" 0 "false" ;
VAL_ 2152128512 ACCPMCA_ACCPrfMd2Avl 1 "true" 0 "false" ;
VAL_ 2152128512 ACCPMCA_ACCPrfMd1Avl 1 "true" 0 "false" ;
VAL_ 2151997440 DrvDrowSysIndRq 0 "No Indication" 1 "Continuous Indication" 2 "Flashing Indication With Chime" 3 "Flashing Indication Without Chime" 4 "Reserved1" 5 "Reserved2" 6 "Reserved3" 7 "Reserved4" ;
VAL_ 2151997440 DrvDrwDetCsCrStVal 0 "No Action" 1 "Off" 2 "On" 3 "Reserved1" 4 "Reserved2" 5 "Reserved3" 6 "Reserved4" 7 "Reserved5" ;
VAL_ 2151997440 DrvDrowDetCstStAvl 1 "true" 0 "false" ;
VAL_ 2156331008 EUSD_MsrmntUnit 3 "Unused and Reserved 1" 2 "Unitless Score" 1 "km" 0 "No Action" ;
VAL_ 2156331008 LwRngLVLdShdRq 0 "No Load Shedding" 1 "Load Shed Level1" 2 "Load Shed Level2" 3 "Load Shed Level3" ;
VAL_ 2151776256 RCTALIC_Indctr1Act 1 "true" 0 "false" ;
VAL_ 2151776256 RCTALIC_IndReq 0 "Off" 1 "Continuous Indication" 2 "Flashing Indication" ;
VAL_ 2154774528 LtRtHnTrGPSCsStAvl 1 "true" 0 "false" ;
VAL_ 2154774528 LtRtHnTrGPCsCrStVal 0 "No Value" 1 "Left Hand Traffic" 2 "Right Hand Traffic" 3 "Automatic" 4 "Reserved1" 5 "Reserved2" 6 "Reserved3" 7 "Reserved4" ;
VAL_ 2154774528 LtRtHnTrCstStVal 0 "No Value" 1 "Left Hand Traffic" 2 "Right Hand Traffic" ;
VAL_ 2154774528 LtRtHnTrCstStAvail 0 "Not Available" 1 "Present" ;
VAL_ 2150375424 HVBChrgOvrdBtnDspReq 2 "Do Not Display Charge Override Button" 1 "Display Charge Override Button" 0 "No Action" ;
VAL_ 2150375424 HVBChrgLmtBtnDspReq 2 "Do Not Display Charge Limit Button" 1 "Display Charge Limit Button" 0 "No Action" ;
VAL_ 2150375424 HVBHmChrgTmDspReq 4 "Display Master Setting" 3 "Display Both Cord and Station" 2 "Display Charge Station Charge Value" 1 "Display Portable Cord Charge Value" 0 "No Action" ;
VAL_ 2150375424 HVBChrgTmDspReq 3 "Display Both Cord and Station" 2 "Display Charge Station Charge Value" 1 "Display Portable Cord Charge Value" 0 "No Action" ;
VAL_ 2150375424 LBCCsStReq 2 "On" 1 "Off" 0 "No Action" ;
VAL_ 2150375424 LBCPosMdfcReq 4 "Store Position 4" 3 "Store Position 3" 2 "Store Position 2" 1 "Store Position 1" 0 "No Action" ;
VAL_ 2150375424 LBCCDRR_ClrStrdPosReq 2 "Confirmation to Clear Position" 1 "Request to Clear Position" 0 "No Action" ;
VAL_ 2150375424 LBCCDRR_PosNum 4 "Position Number 4" 3 "Position Number 3" 2 "Position Number 2" 1 "Position Number 1" 0 "No Action" ;
VAL_ 2150375424 USBProgInPrgrs 1 "true" 0 "false" ;
VAL_ 2150375424 EngyCnsHistGrphRstRq 1 "true" 0 "false" ;
VAL_ 2150375424 DsplTrnsShftLvrLckRqd 1 "true" 0 "false" ;
VAL_ 2150375424 EngAstHtPlgInCstStRq 0 "No Action" 1 "Off" 2 "On" ;
VAL_ 2150375424 EngAstHtCstStRq 3 "Off" 0 "No Action" 1 "On" 2 "Deferred" ;
VAL_ 2150375424 MntnceMdStEngRq 1 "true" 0 "false" ;
VAL_ 2150383616 LssOfPrplsnIO 1 "true" 0 "false" ;
VAL_ 2150383616 EngMntnceMdAct 1 "true" 0 "false" ;
VAL_ 2150383616 MntnceMdDsplyRq 15 "Unused and Reserved" 14 "Continue FM" 13 "Force FM" 12 "FM 1 Day Warning" 11 "FM 2 Day Warning" 10 "FM 3 Day Warning" 9 "FM 4 Day Warning" 8 "FM 5 Day Warning" 7 "Continue EM" 6 "Force EM" 5 "EM 1 Day Warning" 4 "EM 2 Day Warning" 3 "EM 3 Day Warning" 2 "EM 4 Day Warning" 1 "EM 5 Day Warning" 0 "No Request" ;
SIG_GROUP_ 2151292928 TrfRdsdInfCsAvail 1 : TRICA_Resrv5Avail TRICA_Resrv4Avail TRICA_Resrv3Avail TRICA_Resrv2Avail TRICA_Resrv1Avail TRICA_OnAvail TRICA_OfAvail;
SIG_GROUP_ 2151292928 IntrStAlrtCsAvail 1 : ISACA_Resrv4Avail ISACA_Resrv3Avail ISACA_Resrv2Avail ISACA_Resrv1Avail ISACA_AlrtBrkAvail ISACA_AlrtAvail ISACA_OfAvail;
SIG_GROUP_ 2151292928 CntdVehBrkAlrtCsAvail 1 : CVBACA_Resrv5Avail CVBACA_Resrv4Avail CVBACA_Resrv3Avail CVBACA_Resrv2Avail CVBACA_Resrv1Avail CVBACA_OnAvail CVBACA_OfAvail;
SIG_GROUP_ 2151464960 V2VSpdRecmndtn 1 : V2VSR_TrfLghtDispLim V2VSR_TrfLghtMaxRecmndSpd V2VSR_TrfLghtMinRecmndSpd;
SIG_GROUP_ 2151464960 V2VTrfLghtInfo 1 : V2VTLI_TrfLghtMntngDirctn V2VTLI_TrfLghtValDirctn V2VTLI_TrfLghtPhsArivl V2VTLI_TrfLghtActlPhs V2VTLI_TrfLghtTmPhsSw;
SIG_GROUP_ 2153914368 EngyUsgScrScal 1 : EUSS_TrEgUgScrMxScVal EUSS_TrEgUgScrMnScVal EUSS_TcEgUgScrMxScVal EUSS_TcEgUgScrMnScVal EUSS_ITEgUgScrMxScVal EUSS_ITEgUgScrMnScVal EUSS_OTEgUgScrMxScVal EUSS_OTEgUgScrMnScVal;
SIG_GROUP_ 2151792640 RrCrsTrfAltRgtIndCtrl 1 : RCTARIC_Indctr1Act RCTARIC_IndReq;
SIG_GROUP_ 2149826560 FwdObjAlrtInd11E 1 : FOAI_VehAhdIndRq11E FOAI_AlrtWrnIndRq11E FOAI_AlrtChmIhbRq11E;
SIG_GROUP_ 2156314624 TODCNxtPlnndDprtrTm 1 : TODCNPDT_Min TODCNPDT_Hr TODCNPDT_DyOfWk;
SIG_GROUP_ 2156314624 TODCDspMnPgTmpOr 1 : TODCDMPTO_TpOvR TODCDMPTO_CmPgR;
SIG_GROUP_ 2156314624 HVChgSyChgLvlPrfDt 1 : HVCSCLPD_UsrIntTyp HVCSCLPD_RdCrntLv3 HVCSCLPD_RdCrntLv2 HVCSCLPD_RdCrntLv1 HVCSCLPD_NrmChrgC HVCSCLPD_ChgLvlPfS;
SIG_GROUP_ 2150449152 AutoStpInhbtRsnInd 1 : ASIRI_Indication08 ASIRI_Indication07 ASIRI_Indication06 ASIRI_Indication05 ASIRI_Indication04 ASIRI_Indication03 ASIRI_Indication02 ASIRI_Indication01;
SIG_GROUP_ 2149793792 VhlAhdDstIndReq 1 : VADIR_IndLvl VADIR_FlwTme VADIR_FlwDst;
SIG_GROUP_ 2150080512 LBCVehLctStat 1 : LBCVLS_VehGPSLctV LBCVLS_VehGPSLct;
SIG_GROUP_ 2150080512 LBCPosStgStat 1 : LBCPSS_PosUpdtStat LBCPSS_PosUpdtLct;
SIG_GROUP_ 2150080512 LBCCstmrFdbk 1 : LBCCF_Lct4PosStrdIO LBCCF_Lct3PosStrdIO LBCCF_Lct2PosStrdIO LBCCF_Lct1PosStrdIO;
SIG_GROUP_ 2150080512 LBCCstmrDaRstResp 1 : LBCCDRR_PosNumbr LBCCDRR_ClrStrdPosResp;
SIG_GROUP_ 2152128512 PsngStPerfMdCustAvl 1 : PSPMCA_PsngStPrfMd6Avl PSPMCA_PsngStPrfMd5Avl PSPMCA_PsngStPrfMd4Avl PSPMCA_PsngStPrfMd3Avl PSPMCA_PsngStPrfMd2Avl PSPMCA_PsngStPrfMd1Avl;
SIG_GROUP_ 2152128512 DrvrStPerfMdCustAvl 1 : DSPMCA_DrvrStPrfMd6Avl DSPMCA_DrvrStPrfMd5Avl DSPMCA_DrvrStPrfMd4Avl DSPMCA_DrvrStPrfMd3Avl DSPMCA_DrvrStPrfMd2Avl DSPMCA_DrvrStPrfMd1Avl;
SIG_GROUP_ 2152128512 DrvStyPerfMdCustAvl 1 : DSPMCA_DrvStyPrfMd7Avl DSPMCA_DrvStyPrfMd6Avl DSPMCA_DrvStyPrfMd5Avl DSPMCA_DrvStyPrfMd4Avl DSPMCA_DrvStyPrfMd3Avl DSPMCA_DrvStyPrfMd2Avl DSPMCA_DrvStyPrfMd1Avl;
SIG_GROUP_ 2152128512 ACCPerfMdCustAvl 1 : ACCPMCA_ACCPrfMd6Avl ACCPMCA_ACCPrfMd5Avl ACCPMCA_ACCPrfMd4Avl ACCPMCA_ACCPrfMd3Avl ACCPMCA_ACCPrfMd2Avl ACCPMCA_ACCPrfMd1Avl;
SIG_GROUP_ 2156331008 EngyUsgScrDsp 1 : EUSD_MsrmntUnit EUSD_MsrmntVal;
SIG_GROUP_ 2151776256 RrCrsTrfAltLftIndCtrl 1 : RCTALIC_Indctr1Act RCTALIC_IndReq;
SIG_GROUP_ 2150375424 LBCCstmrDaRstReq 1 : LBCCDRR_ClrStrdPosReq LBCCDRR_PosNum;
SIG_GROUP_ 2151981056 DstTrvldDt 1 : DTD_FuelPrpDstTrvld DTD_DrvCyclDstTrvld DTD_BattPrpDstTrvld;
